VERSION ""

NS_ :

BS_:

BU_: L_DHRR_FD L_UWB_BLE_MST_FD L_UWB_RR_FD L_UWB_BLE_SLV_FD L_UWB_FR_FD L_ROA_FR_FD L_ROA_FD L_DHRL_FD L_UWB_TRNK_FD L_UWB_FRNK_FD L_EDT_FD L_UWB_FL_FD GW_BDC_FD L_UWB_RL_FD L_SAL_FD L_WPC_FD L_TPMS_FD L_DHL_FD L_DHR_FD

BO_ 994 PDC_FD_03_200ms: 16 GW_BDC_FD
 SG_ PDC_FD_Crc3Val : 0|16@1+ (1,0) [0|0] "" Vector__XXX
 SG_ PDC_FD_AlvCnt3Val : 16|8@1+ (1,0) [0|0] "" Vector__XXX
 SG_ Warn_DrvDrSwSta_Copy_0 : 64|2@1+ (1,0) [0|0] ""  L_UWB_BLE_MST_FD
 SG_ Warn_AsstDrSwSta_Copy_0 : 66|2@1+ (1,0) [0|0] ""  L_UWB_BLE_MST_FD
 SG_ Warn_RrLftDrSwSta_Copy_0 : 68|2@1+ (1,0) [0|0] ""  L_UWB_BLE_MST_FD
 SG_ Warn_RrRtDrSwSta_Copy_0 : 70|2@1+ (1,0) [0|0] ""  L_UWB_BLE_MST_FD
 SG_ Warn_HoodSwSta_Copy_0 : 72|2@1+ (1,0) [0|0] ""  L_UWB_BLE_MST_FD
 SG_ DoorLock_DrvDrUnLkSta_Copy_0 : 74|2@1+ (1,0) [0|0] ""  L_UWB_BLE_MST_FD
 SG_ DoorLock_AsstDrUnLkSta_Copy_0 : 76|2@1+ (1,0) [0|0] ""  L_UWB_BLE_MST_FD
 SG_ DoorLock_RrLftDrUnLkSta_Copy_0 : 78|2@1+ (1,0) [0|0] ""  L_UWB_BLE_MST_FD
 SG_ DoorLock_RrRtDrUnLkSta_Copy_0 : 80|2@1+ (1,0) [0|0] ""  L_UWB_BLE_MST_FD
 SG_ DoorLock_DrvKeyLkSwSta_Copy_0 : 82|2@1+ (1,0) [0|0] "" Vector__XXX
 SG_ DoorLock_DrvKeyUnLkSwSta_Copy_0 : 84|2@1+ (1,0) [0|0] "" Vector__XXX
 SG_ DoorLock_CtrlDrLkSwSta_ICU_Copy_ : 86|2@1+ (1,0) [0|0] "" Vector__XXX
 SG_ DoorLock_CtrlDrUnLkSwSta_ICU_Cop : 88|2@1+ (1,0) [0|0] "" Vector__XXX
 SG_ DoorLock_CtrlDrLkUnLkSwSta_ICU_C : 90|2@1+ (1,0) [0|0] "" Vector__XXX
 SG_ C_CrashUnlockState_Copy_0 : 92|2@1+ (1,0) [0|0] "" Vector__XXX
 SG_ Lamp_LedHdLmpSta_Copy_0 : 94|2@1+ (1,0) [0|0] "" Vector__XXX
 SG_ Warn_ChaDrSwFrtSta_Copy_0 : 96|2@1+ (1,0) [0|0] "" Vector__XXX
 SG_ Warn_ChaDrSwRrSta_Copy_0 : 98|2@1+ (1,0) [0|0] "" Vector__XXX

BO_ 2348810241 L_BDC_FD_01_200ms: 32 GW_BDC_FD
 SG_ L_BDC_FD_Crc1Val : 0|16@1+ (1,0) [0|0] "0"  L_SAL_FD
 SG_ MoodLamp_BottomBlueVal : 104|8@1+ (1,0) [0|0] ""  L_SAL_FD
 SG_ MoodLamp_AIVoiceMicLevel : 112|6@1+ (1,0) [0|0] ""  L_SAL_FD
 SG_ MoodLamp_AIVoiceTTSLevel : 120|6@1+ (1,0) [0|0] ""  L_SAL_FD
 SG_ MoodLamp_VehicleSpeed : 128|9@1+ (1,0) [0|0] ""  L_SAL_FD
 SG_ MoodLamp_MLBrghtModCmd_6bit : 137|6@1+ (1,0) [0|0] ""  L_SAL_FD
 SG_ MoodLamp_MLColorModCmd_6bit : 143|6@1+ (1,0) [0|0] ""  L_SAL_FD
 SG_ MoodLamp_DrvTempChgModCmd : 149|2@1+ (1,0) [0|0] ""  L_SAL_FD
 SG_ MoodLamp_AstTempChgModCmd : 151|2@1+ (1,0) [0|0] ""  L_SAL_FD
 SG_ MoodLamp_PhoneCallModCmd : 153|2@1+ (1,0) [0|0] ""  L_SAL_FD
 SG_ MoodLamp_AIVoiceRecogPosSta : 155|3@1+ (1,0) [0|0] ""  L_SAL_FD
 SG_ MoodLamp_FLDoorWarnModCmd : 158|3@1+ (1,0) [0|0] ""  L_SAL_FD
 SG_ L_BDC_FD_AlvCnt1Val : 16|8@1+ (1,0) [0|0] "0"  L_SAL_FD
 SG_ MoodLamp_FRDoorWarnModCmd : 161|3@1+ (1,0) [0|0] ""  L_SAL_FD
 SG_ MoodLamp_RLDoorWarnModCmd : 164|3@1+ (1,0) [0|0] ""  L_SAL_FD
 SG_ MoodLamp_RRDoorWarnModCmd : 167|3@1+ (1,1) [0|0] ""  L_SAL_FD
 SG_ MoodLamp_HazardModCmd : 170|2@1+ (1,0) [0|0] ""  L_SAL_FD
 SG_ MoodLamp_FLDoorObstacleModCmd : 172|2@1+ (1,0) [0|0] ""  L_SAL_FD
 SG_ MoodLamp_FRDoorObstacleModCmd : 174|2@1+ (1,0) [0|0] ""  L_SAL_FD
 SG_ MoodLamp_RLDoorObstacleModCmd : 176|2@1+ (1,0) [0|0] ""  L_SAL_FD
 SG_ MoodLamp_RRDoorObstacleModCmd : 178|2@1+ (1,0) [0|0] ""  L_SAL_FD
 SG_ MoodLamp_LowFuelWarnModCmd : 180|2@1+ (1,0) [0|0] ""  L_SAL_FD
 SG_ MoodLamp_NShiftModCmd : 182|3@1+ (1,0) [0|0] ""  L_SAL_FD
 SG_ MoodLamp_MLBrghtModCmd : 24|4@1+ (1,0) [0|0] ""  L_SAL_FD
 SG_ MoodLamp_MLColorModCmd : 28|4@1+ (1,0) [0|0] ""  L_SAL_FD
 SG_ MoodLamp_WelcomeAndGoodbyeSeqMod : 32|2@1+ (1,0) [0|0] ""  L_SAL_FD
 SG_ MoodLamp_AIVoiceSeqModCmd : 34|3@1+ (1,0) [0|0] ""  L_SAL_FD
 SG_ MoodLamp_EngineRunningSeqModCmd : 37|2@1+ (1,0) [0|0] ""  L_SAL_FD
 SG_ MoodLamp_OverSpeedSeqModCmd : 40|2@1+ (1,0) [0|0] ""  L_SAL_FD
 SG_ MoodLamp_DriveSeqModCmd : 42|4@1+ (1,0) [0|0] ""  L_SAL_FD
 SG_ MoodLamp_AirCleaningSeqModCmd : 48|3@1+ (1,0) [0|0] ""  L_SAL_FD
 SG_ MoodLamp_FootLampModCmd : 51|2@1+ (1,0) [0|0] ""  L_SAL_FD
 SG_ MoodLamp_SunroofModCmd : 53|2@1+ (1,0) [0|0] ""  L_SAL_FD
 SG_ MoodLamp_BrghtVal : 56|4@1+ (1,0) [0|0] ""  L_SAL_FD
 SG_ MoodLamp_RedVal : 64|8@1+ (1,0) [0|0] ""  L_SAL_FD
 SG_ MoodLamp_GreenVal : 72|8@1+ (1,0) [0|0] ""  L_SAL_FD
 SG_ MoodLamp_BlueVal : 80|8@1+ (1,0) [0|0] ""  L_SAL_FD
 SG_ MoodLamp_BottomRedVal : 88|8@1+ (1,0) [0|0] ""  L_SAL_FD
 SG_ MoodLamp_BottomGreenVal : 96|8@1+ (1,0) [0|0] ""  L_SAL_FD

BO_ 996 PDC_FD_10_200ms: 16 GW_BDC_FD
 SG_ PDC_FD_Crc10Val : 0|16@1+ (1,0) [0|0] "" Vector__XXX
 SG_ PDC_PwrOnModePowerReq_Copy_0 : 107|2@1+ (1,0) [0|0] "" Vector__XXX
 SG_ PDC_LeadAcidBatType_Copy_0 : 109|5@1+ (1,0) [0|0] "" Vector__XXX
 SG_ PDC_BatPwrClassOpt_Copy_0 : 114|2@1+ (1,0) [0|0] "" Vector__XXX
 SG_ PDC_MainLBMOpt : 116|2@1+ (1,0) [0|0] "" Vector__XXX
 SG_ PDC_FD_AlvCnt10Val : 16|8@1+ (1,0) [0|0] "" Vector__XXX
 SG_ ICU_PowerAutoCutModSta_Copy_0 : 64|2@1+ (1,0) [0|0] ""  L_TPMS_FD
 SG_ Autocut_DlvryModSta_Copy_0 : 66|2@1+ (1,0) [0|0] "" Vector__XXX
 SG_ ICU_SoCBattStaMsgReq_Copy_0 : 68|2@1+ (1,0) [0|0] "" Vector__XXX
 SG_ Batt_SoCWarningValue_Copy_0 : 70|8@1+ (1,0) [0|0] "%" Vector__XXX
 SG_ ICU_BattAutoCutPreWrng_Copy_0 : 78|2@1+ (1,0) [0|0] "" Vector__XXX
 SG_ OTAModeACCOffReq_Copy_0 : 80|2@1+ (1,0) [0|0] "" Vector__XXX
 SG_ C_ICUIGNOffReq_Copy_0 : 82|2@1+ (1,0) [0|0] "" Vector__XXX
 SG_ IGN_AutoOff_WarnSta_Copy_0 : 84|2@1+ (1,0) [0|0] "" Vector__XXX
 SG_ IGN_AutoOff_WarnSta_CLU_Copy_0 : 86|2@1+ (1,0) [0|0] "" Vector__XXX
 SG_ PDC_BatPwrStateClassA_Copy_0 : 88|2@1+ (1,0) [0|0] "" Vector__XXX
 SG_ PDC_BatPwrStateClassB_Copy_0 : 90|2@1+ (1,0) [0|0] "" Vector__XXX
 SG_ PDC_BatPwrStateClassC_Copy_0 : 92|2@1+ (1,0) [0|0] "" Vector__XXX
 SG_ PLBMAvailableState_Copy_0 : 94|1@1+ (1,0) [0|0] "" Vector__XXX
 SG_ Bat_dischrg_Copy_0 : 95|2@1+ (1,0) [0|0] "" Vector__XXX
 SG_ Bat12V_Chr_Req_Copy_0 : 97|2@1+ (1,0) [0|0] "" Vector__XXX
 SG_ ICU_BattMngAlert_Copy_0 : 99|8@1+ (1,0) [0|0] "" Vector__XXX

BO_ 2549874800 NM_CGW_CCU: 32 GW_BDC_FD
 SG_ SNI_CGW_CCU : 0|8@1+ (1,0) [0|0] ""  L_DHL_FD,L_DHRL_FD,L_DHRR_FD,L_DHR_FD,L_SAL_FD,L_TPMS_FD,L_UWB_BLE_MST_FD,L_UWB_BLE_SLV_FD,L_UWB_FL_FD,L_UWB_FRNK_FD,L_UWB_FR_FD,L_UWB_RL_FD,L_UWB_RR_FD,L_UWB_TRNK_FD,L_WPC_FD
 SG_ CBV_NMCoSRB_CGW_CCU : 11|1@1+ (1,0) [0|0] ""  L_DHL_FD,L_DHRL_FD,L_DHRR_FD,L_DHR_FD,L_SAL_FD,L_TPMS_FD,L_UWB_BLE_MST_FD,L_UWB_BLE_SLV_FD,L_UWB_FL_FD,L_UWB_FRNK_FD,L_UWB_FR_FD,L_UWB_RL_FD,L_UWB_RR_FD,L_UWB_TRNK_FD,L_WPC_FD
 SG_ CBV_AWB_CGW_CCU : 12|1@1+ (1,0) [0|0] ""  L_DHL_FD,L_DHRL_FD,L_DHRR_FD,L_DHR_FD,L_SAL_FD,L_TPMS_FD,L_UWB_BLE_MST_FD,L_UWB_BLE_SLV_FD,L_UWB_FL_FD,L_UWB_FRNK_FD,L_UWB_FR_FD,L_UWB_RL_FD,L_UWB_RR_FD,L_UWB_TRNK_FD,L_WPC_FD
 SG_ PNI_CGW_CCU_2 : 128|64@1+ (1,0) [0|0] ""  L_DHL_FD,L_DHRL_FD,L_DHRR_FD,L_DHR_FD,L_SAL_FD,L_TPMS_FD,L_UWB_BLE_MST_FD,L_UWB_BLE_SLV_FD,L_UWB_FL_FD,L_UWB_FRNK_FD,L_UWB_FR_FD,L_UWB_RL_FD,L_UWB_RR_FD,L_UWB_TRNK_FD,L_WPC_FD
 SG_ CBV_PNIB_CGW_CCU : 14|1@1+ (1,0) [0|0] ""  L_DHL_FD,L_DHRL_FD,L_DHRR_FD,L_DHR_FD,L_SAL_FD,L_TPMS_FD,L_UWB_BLE_MST_FD,L_UWB_BLE_SLV_FD,L_UWB_FL_FD,L_UWB_FRNK_FD,L_UWB_FR_FD,L_UWB_RL_FD,L_UWB_RR_FD,L_UWB_TRNK_FD,L_WPC_FD
 SG_ NRR_CGW_CCU : 16|8@1+ (1,0) [0|0] ""  L_DHL_FD,L_DHRL_FD,L_DHRR_FD,L_DHR_FD,L_SAL_FD,L_TPMS_FD,L_UWB_BLE_MST_FD,L_UWB_BLE_SLV_FD,L_UWB_FL_FD,L_UWB_FRNK_FD,L_UWB_FR_FD,L_UWB_RL_FD,L_UWB_RR_FD,L_UWB_TRNK_FD,L_WPC_FD
 SG_ PNI_CGW_CCU_3 : 192|64@1+ (1,0) [0|0] ""  L_DHL_FD,L_DHRL_FD,L_DHRR_FD,L_DHR_FD,L_SAL_FD,L_TPMS_FD,L_UWB_BLE_MST_FD,L_UWB_BLE_SLV_FD,L_UWB_FL_FD,L_UWB_FRNK_FD,L_UWB_FR_FD,L_UWB_RL_FD,L_UWB_RR_FD,L_UWB_TRNK_FD,L_WPC_FD
 SG_ NM_State_CGW_CCU : 24|8@1+ (1,0) [0|0] ""  L_DHL_FD,L_DHRL_FD,L_DHRR_FD,L_DHR_FD,L_SAL_FD,L_TPMS_FD,L_UWB_BLE_MST_FD,L_UWB_BLE_SLV_FD,L_UWB_FL_FD,L_UWB_FRNK_FD,L_UWB_FR_FD,L_UWB_RL_FD,L_UWB_RR_FD,L_UWB_TRNK_FD,L_WPC_FD
 SG_ PNI_CGW_CCU : 32|32@1+ (1,0) [0|0] ""  L_DHL_FD,L_DHRL_FD,L_DHRR_FD,L_DHR_FD,L_SAL_FD,L_TPMS_FD,L_UWB_BLE_MST_FD,L_UWB_BLE_SLV_FD,L_UWB_FL_FD,L_UWB_FRNK_FD,L_UWB_FR_FD,L_UWB_RL_FD,L_UWB_RR_FD,L_UWB_TRNK_FD,L_WPC_FD
 SG_ PNI_CGW_CCU_1 : 64|64@1+ (1,0) [0|0] ""  L_DHL_FD,L_DHRL_FD,L_DHRR_FD,L_DHR_FD,L_SAL_FD,L_TPMS_FD,L_UWB_BLE_MST_FD,L_UWB_BLE_SLV_FD,L_UWB_FL_FD,L_UWB_FRNK_FD,L_UWB_FR_FD,L_UWB_RL_FD,L_UWB_RR_FD,L_UWB_TRNK_FD,L_WPC_FD
 SG_ CBV_RMR_CGW_CCU : 8|1@1+ (1,0) [0|0] ""  L_DHL_FD,L_DHRL_FD,L_DHRR_FD,L_DHR_FD,L_SAL_FD,L_TPMS_FD,L_UWB_BLE_MST_FD,L_UWB_BLE_SLV_FD,L_UWB_FL_FD,L_UWB_FRNK_FD,L_UWB_FR_FD,L_UWB_RL_FD,L_UWB_RR_FD,L_UWB_TRNK_FD,L_WPC_FD
 SG_ CBV_NMCoID_CGW_CCU : 9|2@1+ (1,0) [0|0] ""  L_DHL_FD,L_DHRL_FD,L_DHRR_FD,L_DHR_FD,L_SAL_FD,L_TPMS_FD,L_UWB_BLE_MST_FD,L_UWB_BLE_SLV_FD,L_UWB_FL_FD,L_UWB_FRNK_FD,L_UWB_FR_FD,L_UWB_RL_FD,L_UWB_RR_FD,L_UWB_TRNK_FD,L_WPC_FD

BO_ 2348810242 L_BDC_FD_02_200ms: 32 GW_BDC_FD
 SG_ TPMS_SnsrIdRrVal : 128|32@1+ (1,0) [0|0] ""  L_TPMS_FD
 SG_ TPMS_FrontLowPressureWarnSetVal : 160|16@1+ (1,0) [0|0] ""  L_TPMS_FD
 SG_ TPMS_RearLowPressureWarnSetVal : 176|16@1+ (1,0) [0|0] ""  L_TPMS_FD
 SG_ TPMS_FrontLowPressureWarnClearVa : 192|16@1+ (1,0) [0|0] ""  L_TPMS_FD
 SG_ TPMS_RearLowPressureWarnClearVal : 208|16@1+ (1,0) [0|0] ""  L_TPMS_FD
 SG_ TPMS_SensorSupplierInfo : 224|2@1+ (1,0) [0|0] ""  L_TPMS_FD
 SG_ TPMS_RfConfigueVal : 226|2@1+ (1,0) [0|0] ""  L_TPMS_FD
 SG_ TPMS_SnsrIdFlVal : 24|32@1+ (1,0) [0|0] ""  L_TPMS_FD
 SG_ TPMS_LowPressureWarnSta : 56|4@1+ (1,0) [0|0] ""  L_TPMS_FD
 SG_ TPMS_LastTpsDataReq : 60|2@1+ (1,0) [0|0] ""  L_TPMS_FD
 SG_ TPMS_SnsrIdFrVal : 64|32@1+ (1,0) [0|0] ""  L_TPMS_FD
 SG_ TPMS_SnsrIdRlVal : 96|32@1+ (1,0) [0|0] ""  L_TPMS_FD

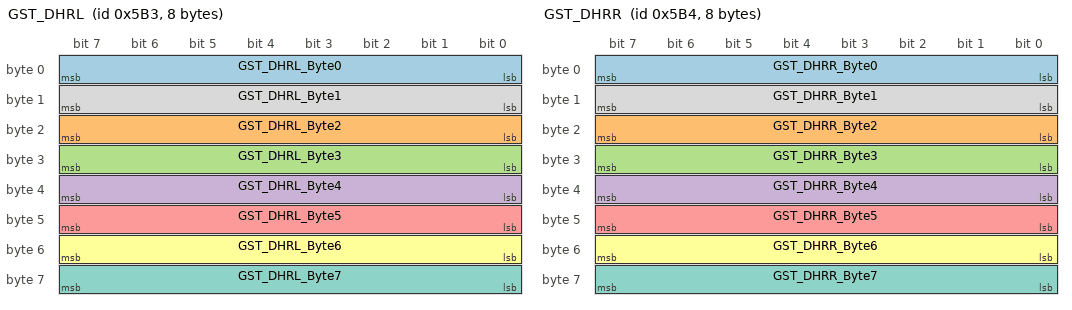
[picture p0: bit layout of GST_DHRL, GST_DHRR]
BO_ 1459 GST_DHRL: 8 GW_BDC_FD
 SG_ GST_DHRL_Byte0 : 0|8@1+ (1,0) [0|0] ""  L_DHRL_FD
 SG_ GST_DHRL_Byte2 : 16|8@1+ (1,0) [0|0] ""  L_DHRL_FD
 SG_ GST_DHRL_Byte3 : 24|8@1+ (1,0) [0|0] ""  L_DHRL_FD
 SG_ GST_DHRL_Byte4 : 32|8@1+ (1,0) [0|0] ""  L_DHRL_FD
 SG_ GST_DHRL_Byte5 : 40|8@1+ (1,0) [0|0] ""  L_DHRL_FD
 SG_ GST_DHRL_Byte6 : 48|8@1+ (1,0) [0|0] ""  L_DHRL_FD
 SG_ GST_DHRL_Byte7 : 56|8@1+ (1,0) [0|0] ""  L_DHRL_FD
 SG_ GST_DHRL_Byte1 : 8|8@1+ (1,0) [0|0] ""  L_DHRL_FD

BO_ 2683310258 L_ROA_FD_Debug_03: 8 L_ROA_FD
 SG_ ROA_Debug_08 : 0|64@1+ (1,0) [0|0] "" Vector__XXX

BO_ 1460 GST_DHRR: 8 GW_BDC_FD
 SG_ GST_DHRR_Byte0 : 0|8@1+ (1,0) [0|0] ""  L_DHRR_FD
 SG_ GST_DHRR_Byte2 : 16|8@1+ (1,0) [0|0] ""  L_DHRR_FD
 SG_ GST_DHRR_Byte3 : 24|8@1+ (1,0) [0|0] ""  L_DHRR_FD
 SG_ GST_DHRR_Byte4 : 32|8@1+ (1,0) [0|0] ""  L_DHRR_FD
 SG_ GST_DHRR_Byte5 : 40|8@1+ (1,0) [0|0] ""  L_DHRR_FD
 SG_ GST_DHRR_Byte6 : 48|8@1+ (1,0) [0|0] ""  L_DHRR_FD
 SG_ GST_DHRR_Byte7 : 56|8@1+ (1,0) [0|0] ""  L_DHRR_FD
 SG_ GST_DHRR_Byte1 : 8|8@1+ (1,0) [0|0] ""  L_DHRR_FD

BO_ 2683310256 L_ROA_FD_Debug_01: 32 L_ROA_FD
 SG_ ROA_Debug_00 : 0|64@1+ (1,0) [0|0] "" Vector__XXX
 SG_ ROA_Debug_02 : 128|64@1+ (1,0) [0|0] "" Vector__XXX
 SG_ ROA_Debug_03 : 192|64@1+ (1,0) [0|0] "" Vector__XXX
 SG_ ROA_Debug_01 : 64|64@1+ (1,0) [0|0] "" Vector__XXX

BO_ 2683310257 L_ROA_FD_Debug_02: 32 L_ROA_FD
 SG_ ROA_Debug_04 : 0|64@1+ (1,0) [0|0] "" Vector__XXX
 SG_ ROA_Debug_06 : 128|64@1+ (1,0) [0|0] "" Vector__XXX
 SG_ ROA_Debug_07 : 192|64@1+ (1,0) [0|0] "" Vector__XXX
 SG_ ROA_Debug_05 : 64|64@1+ (1,0) [0|0] "" Vector__XXX

BO_ 2281701616 L_UWB_RL_FD_10_200ms: 24 L_UWB_RL_FD
 SG_ L_UWB_RL_FD_Crc10Val : 0|16@1+ (1,0) [0|0] "0" Vector__XXX
 SG_ UWB_RL_SW_MCU_Ver_Major : 104|8@1+ (1,0) [0|0] ""  L_UWB_BLE_MST_FD
 SG_ UWB_RL_SW_MCU_Ver_Minor : 112|8@1+ (1,0) [0|0] ""  L_UWB_BLE_MST_FD
 SG_ UWB_RL_SW_IC_Ver_Major : 120|8@1+ (1,0) [0|0] ""  L_UWB_BLE_MST_FD
 SG_ UWB_RL_SW_IC_Ver_Minor : 128|8@1+ (1,0) [0|0] ""  L_UWB_BLE_MST_FD
 SG_ UWB_RL_DTC : 136|8@1+ (1,0) [0|0] ""  L_UWB_BLE_MST_FD
 SG_ L_UWB_RL_FD_AlvCnt10Val : 16|8@1+ (1,0) [0|0] "0" Vector__XXX
 SG_ UWB_RL_Status1 : 24|4@1+ (1,0) [0|7] ""  GW_BDC_FD,L_UWB_BLE_MST_FD
 SG_ UWB_RL_Status2 : 28|4@1+ (1,0) [0|0] ""  GW_BDC_FD,L_UWB_BLE_MST_FD
 SG_ UWB_RL_Status3 : 32|4@1+ (1,0) [0|0] ""  GW_BDC_FD,L_UWB_BLE_MST_FD
 SG_ UWB_RL_Status4 : 36|4@1+ (1,0) [0|0] ""  GW_BDC_FD,L_UWB_BLE_MST_FD
 SG_ UWB_RL_Status5 : 40|4@1+ (1,0) [0|0] ""  GW_BDC_FD,L_UWB_BLE_MST_FD
 SG_ UWB_RL_Status6 : 44|4@1+ (1,0) [0|0] ""  GW_BDC_FD,L_UWB_BLE_MST_FD
 SG_ UWB_RL_Status7 : 48|4@1+ (1,0) [0|0] ""  GW_BDC_FD,L_UWB_BLE_MST_FD
 SG_ UWB_RL_Status8 : 52|4@1+ (1,0) [0|0] ""  GW_BDC_FD,L_UWB_BLE_MST_FD
 SG_ UWB_RL_Status9 : 56|4@1+ (1,0) [0|0] ""  GW_BDC_FD,L_UWB_BLE_MST_FD
 SG_ UWB_RL_Status10 : 60|4@1+ (1,0) [0|0] ""  GW_BDC_FD,L_UWB_BLE_MST_FD
 SG_ UWB_RL_Status11 : 64|4@1+ (1,0) [0|0] ""  GW_BDC_FD,L_UWB_BLE_MST_FD
 SG_ UWB_RL_Status12 : 68|4@1+ (1,0) [0|0] ""  GW_BDC_FD,L_UWB_BLE_MST_FD
 SG_ UWB_RL_Status13 : 72|4@1+ (1,0) [0|0] ""  GW_BDC_FD,L_UWB_BLE_MST_FD
 SG_ UWB_RL_Status14 : 76|4@1+ (1,0) [0|0] ""  GW_BDC_FD,L_UWB_BLE_MST_FD
 SG_ UWB_RL_Status15 : 80|4@1+ (1,0) [0|0] ""  GW_BDC_FD,L_UWB_BLE_MST_FD
 SG_ UWB_RL_Status16 : 84|4@1+ (1,0) [0|0] ""  GW_BDC_FD,L_UWB_BLE_MST_FD
 SG_ UWB_RL_HW_Ver_Major : 88|8@1+ (1,0) [0|0] ""  L_UWB_BLE_MST_FD
 SG_ UWB_RL_HW_Ver_Minor : 96|8@1+ (1,0) [0|0] ""  L_UWB_BLE_MST_FD

BO_ 979 BDC_FD_04_200ms: 32 GW_BDC_FD
 SG_ BDC_FD_Crc4Val : 0|16@1+ (1,0) [0|0] "" Vector__XXX
 SG_ BDC_FD_AlvCnt4Val : 16|8@1+ (1,0) [0|0] "" Vector__XXX
 SG_ BAlarm_BglrAlrm_CurrentSta : 24|4@1+ (1,0) [0|0] "" Vector__XXX
 SG_ BAlarm_BglrAlrm_Sta : 28|2@1+ (1,0) [0|0] "" Vector__XXX
 SG_ BAlarm_PncAlrmSta_Copy_0 : 30|2@1+ (1,0) [0|0] "" Vector__XXX
 SG_ SBR_StBltStpWrngBzrSta_Copy_0 : 34|3@1+ (1,0) [0|0] "" Vector__XXX
 SG_ SBR_StBltWrngBzrSta_Copy_0 : 37|3@1+ (1,0) [0|0] "" Vector__XXX
 SG_ BAlarm_BrglrHrnRlySta_Copy_0 : 40|2@1+ (1,0) [0|0] "" Vector__XXX
 SG_ SBR_DrvStBltIndSta_Copy_0 : 42|2@1+ (1,0) [0|0] "" Vector__XXX
 SG_ SBR_RrLftStBltWrngIndSta_Copy_0 : 44|2@1+ (1,0) [0|0] "" Vector__XXX
 SG_ SBR_RrRtStBltWrngIndSta_Copy_0 : 46|2@1+ (1,0) [0|0] "" Vector__XXX
 SG_ SBR_RrCtrStBltIndSta_Copy_0 : 48|2@1+ (1,0) [0|0] "" Vector__XXX
 SG_ SBR_3rdLftStBltWrngIndSta_Copy_0 : 50|2@1+ (1,0) [0|0] "" Vector__XXX
 SG_ SBR_3rdRtStBltWrngIndSta_Copy_0 : 52|2@1+ (1,0) [0|0] "" Vector__XXX
 SG_ SBR_3rdCtrStBltWrngIndSta_Copy_0 : 54|2@1+ (1,0) [0|0] "" Vector__XXX
 SG_ Warn_BzrWrngSta_Copy_0 : 56|4@1+ (1,0) [0|0] "" Vector__XXX
 SG_ Warn_BCMWrngSta_Copy_0 : 60|4@1+ (1,0) [0|0] "" Vector__XXX
 SG_ ROA_RrBlwAutoOffReq_Copy_0 : 64|2@1+ (1,0) [0|0] "" Vector__XXX
 SG_ ROA_RegionOpt_Copy_0 : 66|2@1+ (1,0) [0|0] "" Vector__XXX
 SG_ Warn_RrStRmndOpt_Copy_0 : 68|2@1+ (1,0) [0|0] "" Vector__XXX
 SG_ Warn_RrStRmndAlrmOnReq_Copy_0 : 70|2@1+ (1,0) [0|0] "" Vector__XXX
 SG_ Warn_RrStRmndSysSta_Copy_0 : 72|2@1+ (1,0) [0|0] "" Vector__XXX
 SG_ Warn_RrStRmndAlrmInfo_Copy_0 : 74|3@1+ (1,0) [0|0] "" Vector__XXX
 SG_ Warn_RoaErr_Copy_0 : 77|3@1+ (1,0) [0|0] "" Vector__XXX
 SG_ Warn_RrStRmndDelay_Copy_0 : 80|2@1+ (1,0) [0|0] "" Vector__XXX
 SG_ Warn_RrStRmndSysAct_Copy_0 : 82|2@1+ (1,0) [0|0] "" Vector__XXX
 SG_ WAL_FobSearching_Copy_0 : 84|2@1+ (1,0) [0|0] "" Vector__XXX
 SG_ Warn_RrStRmndSysOffIND_Copy_0 : 86|2@1+ (1,0) [0|0] "" Vector__XXX
 SG_ Warn_VehNotPWrngSta_Copy_0 : 88|3@1+ (1,0) [0|0] "" Vector__XXX
 SG_ Warn_RrStRmndAlrmInfo_1_Copy_0 : 91|3@1+ (1,0) [0|0] ""  L_ROA_FD

BO_ 2533736961 L_UWB_TRNK_FD_06_00ms: 32 L_UWB_TRNK_FD
 SG_ L_UWB_TRNK_FD_Crc6Val : 0|16@1+ (1,0) [0|0] "" Vector__XXX
 SG_ L_UWB_TRNK_FD_AlvCnt6Val : 16|8@1+ (1,0) [0|0] "" Vector__XXX
 SG_ TRNK_SWID_4_IVD_1 : 24|232@1+ (1,0) [0|0] ""  L_UWB_BLE_MST_FD

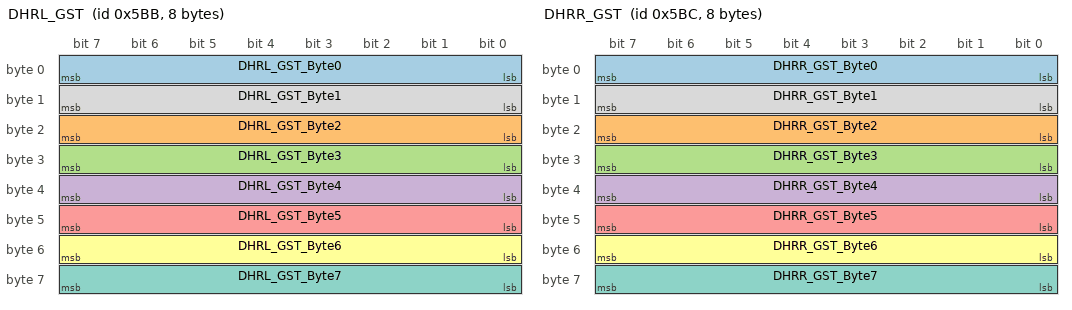
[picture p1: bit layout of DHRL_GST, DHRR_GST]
BO_ 1467 DHRL_GST: 8 L_DHRL_FD
 SG_ DHRL_GST_Byte0 : 0|8@1+ (1,0) [0|0] ""  GW_BDC_FD
 SG_ DHRL_GST_Byte2 : 16|8@1+ (1,0) [0|0] ""  GW_BDC_FD
 SG_ DHRL_GST_Byte3 : 24|8@1+ (1,0) [0|0] ""  GW_BDC_FD
 SG_ DHRL_GST_Byte4 : 32|8@1+ (1,0) [0|0] ""  GW_BDC_FD
 SG_ DHRL_GST_Byte5 : 40|8@1+ (1,0) [0|0] ""  GW_BDC_FD
 SG_ DHRL_GST_Byte6 : 48|8@1+ (1,0) [0|0] ""  GW_BDC_FD
 SG_ DHRL_GST_Byte7 : 56|8@1+ (1,0) [0|0] ""  GW_BDC_FD
 SG_ DHRL_GST_Byte1 : 8|8@1+ (1,0) [0|0] ""  GW_BDC_FD

BO_ 977 BDC_FD_02_200ms: 32 GW_BDC_FD
 SG_ BDC_FD_Crc2Val : 0|16@1+ (1,0) [0|0] "" Vector__XXX
 SG_ BDC_FD_AlvCnt2Val : 16|8@1+ (1,0) [0|0] "" Vector__XXX
 SG_ BCM_KeyInSta_Copy_0 : 24|2@1+ (1,0) [0|0] "" Vector__XXX
 SG_ BCM_AccInSta_Copy_0 : 26|2@1+ (1,0) [0|0] "" Vector__XXX
 SG_ BCM_Ign1InSta_Copy_0 : 28|2@1+ (1,0) [0|0] ""  L_ROA_FD,L_ROA_FR_FD,L_TPMS_FD,L_UWB_BLE_MST_FD,L_UWB_BLE_SLV_FD
 SG_ BCM_Ign2InSta_Copy_0 : 30|2@1+ (1,0) [0|0] ""  L_ROA_FD,L_ROA_FR_FD,L_UWB_BLE_MST_FD,L_UWB_BLE_SLV_FD
 SG_ IBU_HDPSpprtSWVer_Copy_0 : 32|6@1+ (1,0) [0|0] "" Vector__XXX
 SG_ IBU_HDPSpprtRdy_Copy_0 : 38|2@1+ (1,0) [0|0] "" Vector__XXX
 SG_ BCM_GearPosPSta_Copy_0 : 40|2@1+ (1,0) [0|0] "" Vector__XXX
 SG_ BCM_SmkOptTyp_Copy_0 : 42|2@1+ (1,0) [0|0] "" Vector__XXX
 SG_ BDC_ResetOpSta_Copy_0 : 44|2@1+ (1,0) [0|0] "" Vector__XXX
 SG_ IBU_SWVerMajor1_Copy_0 : 48|7@1+ (1,0) [0|0] "" Vector__XXX
 SG_ IBU_SWVerMinor1_Copy_0 : 56|7@1+ (1,0) [0|0] "" Vector__XXX
 SG_ IBU_SWVerMinor2_Copy_0 : 64|7@1+ (1,0) [0|0] "" Vector__XXX
 SG_ BDC_PlatformVerType_Copy_0 : 72|4@1+ (1,0) [0|0] "" Vector__XXX
 SG_ BDC_PlatformVerDate_Copy_0 : 80|8@1+ (1,0) [0|0] "" Vector__XXX

BO_ 2529538561 L_UWB_RL_FD_06_00ms: 32 L_UWB_RL_FD
 SG_ L_UWB_RL_FD_Crc6Val : 0|16@1+ (1,0) [0|0] "" Vector__XXX
 SG_ L_UWB_RL_FD_AlvCnt6Val : 16|8@1+ (1,0) [0|0] "" Vector__XXX
 SG_ RL_SWID_4_IVD_1 : 24|232@1+ (1,0) [0|0] ""  L_UWB_BLE_MST_FD

BO_ 1468 DHRR_GST: 8 L_DHRR_FD
 SG_ DHRR_GST_Byte0 : 0|8@1+ (1,0) [0|0] ""  GW_BDC_FD
 SG_ DHRR_GST_Byte2 : 16|8@1+ (1,0) [0|0] ""  GW_BDC_FD
 SG_ DHRR_GST_Byte3 : 24|8@1+ (1,0) [0|0] ""  GW_BDC_FD
 SG_ DHRR_GST_Byte4 : 32|8@1+ (1,0) [0|0] ""  GW_BDC_FD
 SG_ DHRR_GST_Byte5 : 40|8@1+ (1,0) [0|0] ""  GW_BDC_FD
 SG_ DHRR_GST_Byte6 : 48|8@1+ (1,0) [0|0] ""  GW_BDC_FD
 SG_ DHRR_GST_Byte7 : 56|8@1+ (1,0) [0|0] ""  GW_BDC_FD
 SG_ DHRR_GST_Byte1 : 8|8@1+ (1,0) [0|0] ""  GW_BDC_FD

CM_ BO_ 994 "[PE] Periodic and On Event";
CM_ SG_ 994 PDC_FD_Crc3Val "PDC_FD_CyclicRedundancyCheck3Value";
CM_ SG_ 994 PDC_FD_AlvCnt3Val "PDC_FD_AliveCounter3Value";
CM_ SG_ 994 Warn_DrvDrSwSta_Copy_0 "DoorLock_DriverDoorSwitchStatus ##2G## -  - C_DrvDrSw,CF_Gway_DrvDrSw,Warn_DrvDrSwSta";
CM_ SG_ 994 Warn_AsstDrSwSta_Copy_0 "Warn_AssistDoorSwitchStatus ##2G## -  - C_AstDrSw,CF_Gway_AstDrSw,Warn_AsstDrSwSta";
CM_ SG_ 994 Warn_RrLftDrSwSta_Copy_0 "Warn_RearLeftDoorSwitchStatus ##2G## -  - C_RLDrSw,CF_Gway_RLDrSw,Warn_RrLftDrSwSta";
CM_ SG_ 994 Warn_RrRtDrSwSta_Copy_0 "Warn_RearRightDoorSwitchStatus ##2G## -  - C_RRDrSw,CF_Gway_RRDrSw,Warn_RrRtDrSwSta";
CM_ SG_ 994 Warn_HoodSwSta_Copy_0 "Warn_HoodSwitchStatus ##2G## -  - C_HoodSw,CF_Gway_HoodSw";
CM_ SG_ 994 DoorLock_DrvDrUnLkSta_Copy_0 "DoorLock_DriverDoorUnLockStatus ##2G## -  - C_DrvUnlockState,CF_Gway_DrvUnlockState";
CM_ SG_ 994 DoorLock_AsstDrUnLkSta_Copy_0 "DoorLock_AssistDoorUnLockStatus ##2G## -  - C_AstUnlockState,DoorLock_AsstDrUnLkSta";
CM_ SG_ 994 DoorLock_RrLftDrUnLkSta_Copy_0 "DoorLock_RearLeftDoorUnLockStatus ##2G## -  - C_RLUnlockState,DoorLock_RrLftDrUnLkSta";
CM_ SG_ 994 DoorLock_RrRtDrUnLkSta_Copy_0 "DoorLock_RearRightDoorUnLockStatus ##2G## -  - C_RRUnlockState,DoorLock_RrRtDrUnLkSta";
CM_ SG_ 994 DoorLock_DrvKeyLkSwSta_Copy_0 "DoorLock_DriverKeyLockSwitchStatus ##2G## -  - C_DrvKeyLockSw";
CM_ SG_ 994 DoorLock_DrvKeyUnLkSwSta_Copy_0 "DoorLock_DriverKeyUnLockSwitchStatus ##2G## -  - C_DrvKeyUnlockSw";
CM_ SG_ 994 DoorLock_CtrlDrLkSwSta_ICU_Copy_ "Central Door Lock Switch State(DRV or AST or RL or RR Door trim)";
CM_ SG_ 994 DoorLock_CtrlDrUnLkSwSta_ICU_Cop "Central Door Unlock Switch State(DRV or AST or RL or RR Door trim)";
CM_ SG_ 994 DoorLock_CtrlDrLkUnLkSwSta_ICU_C "Central Door Lock/Unlock Switch State(C/PAD, Integrated & self return type)";
CM_ SG_ 994 C_CrashUnlockState_Copy_0 "Crash Unlock Active State";
CM_ SG_ 994 Lamp_LedHdLmpSta_Copy_0 "Lamp_LedHeadLampStatus ##2G## -  - CF_Afs_LedHLStat";
CM_ SG_ 994 Warn_ChaDrSwFrtSta_Copy_0 "##2G## - -  CF_Gway_ChaDrSwFrt";
CM_ SG_ 994 Warn_ChaDrSwRrSta_Copy_0 "##2G## -  - CF_Gway_ChaDrSwRr";
CM_ BO_ 2348810241 "[PE] Periodic and On Event";
CM_ SG_ 2348810241 L_BDC_FD_Crc1Val "L_BDC_FD_CyclicRedundancyCheck1Value";
CM_ SG_ 2348810241 MoodLamp_MLBrghtModCmd_6bit "MoodLamp Brightness Mode Command (6bit)";
CM_ SG_ 2348810241 MoodLamp_MLColorModCmd_6bit "MoodLamp Color Mode Command (6bit)";
CM_ SG_ 2348810241 L_BDC_FD_AlvCnt1Val "L_BDC_FD_AliveCounter1Value";
CM_ BO_ 996 "[PE] Periodic and On Event";
CM_ SG_ 996 PDC_FD_Crc10Val "PDC_FD_CyclicRedundancyCheck10Value";
CM_ SG_ 996 PDC_PwrOnModePowerReq_Copy_0 "This is for high voltage battery discharge request at Power On mode of EV";
CM_ SG_ 996 PDC_LeadAcidBatType_Copy_0 "Lead Acid Battery Type Information";
CM_ SG_ 996 PDC_MainLBMOpt "M-LBM(Main LBM) Option";
CM_ SG_ 996 PDC_FD_AlvCnt10Val "PDC_FD_AliveCounter10Value";
CM_ SG_ 996 ICU_PowerAutoCutModSta_Copy_0 "##2G## -  - CF_Gway_ICUPowerAutoCutMode";
CM_ SG_ 996 Autocut_DlvryModSta_Copy_0 "Autocut_DeliveryModeStatus ##2G## -  - C_SJBDeliveryMode,CF_Gway_SJBDeliveryMode";
CM_ SG_ 996 ICU_SoCBattStaMsgReq_Copy_0 "##2G## -  - Batt_SoCWarningAlertMsgReq";
CM_ SG_ 996 Batt_SoCWarningValue_Copy_0 "Value of SoC warning level. ##2G## -  - Batt_SoCWarningValue";
CM_ SG_ 996 ICU_BattAutoCutPreWrng_Copy_0 "This is a warning signal before blocking the dark current of the ICU by the battery SOC.";
CM_ SG_ 996 OTAModeACCOffReq_Copy_0 "ACC off request during OTA mode for battery saver";
CM_ SG_ 996 C_ICUIGNOffReq_Copy_0 "IGN off request(Not engine running state only) for battery saver";
CM_ SG_ 996 IGN_AutoOff_WarnSta_Copy_0 "this signal is defined as the warning signal related with battery discharge";
CM_ SG_ 996 IGN_AutoOff_WarnSta_CLU_Copy_0 "this signal is defined as the warning signal related with battery discharge";
CM_ SG_ 996 PDC_BatPwrStateClassA_Copy_0 "Vehicle Low-Voltage Power State Class A";
CM_ SG_ 996 PDC_BatPwrStateClassB_Copy_0 "Vehicle Low-Voltage Power State Class  B";
CM_ SG_ 996 PDC_BatPwrStateClassC_Copy_0 "Vehicle Low-Voltage Power State Class  C";
CM_ SG_ 996 Bat_dischrg_Copy_0 "Battery discharge notification flag #2G# Bat_dischrg";
CM_ SG_ 996 Bat12V_Chr_Req_Copy_0 "12V lead acid battery charging request signal";
CM_ SG_ 996 ICU_BattMngAlert_Copy_0 "This signal is for battery discharge warning.";
CM_ BO_ 2549874800 "[P] Periodic";
CM_ SG_ 2549874800 SNI_CGW_CCU "ASR NM Source Node Identifier";
CM_ SG_ 2549874800 CBV_NMCoSRB_CGW_CCU "ASR NM Control Bit Vector - ASR NM Coordinator Sleep Ready Bit";
CM_ SG_ 2549874800 CBV_AWB_CGW_CCU "ASR NM Control Bit Vector - Active Wakeup Bit";
CM_ SG_ 2549874800 PNI_CGW_CCU_2 "ASR NM Partial Networking Information";
CM_ SG_ 2549874800 CBV_PNIB_CGW_CCU "ASR NM Control Bit Vector - PN Info Bit";
CM_ SG_ 2549874800 NRR_CGW_CCU "ASR NM Network Request Reason";
CM_ SG_ 2549874800 PNI_CGW_CCU_3 "ASR NM Partial Networking Information";
CM_ SG_ 2549874800 NM_State_CGW_CCU "ASR NM State_Current State_Previous State";
CM_ SG_ 2549874800 PNI_CGW_CCU "ASR NM Partial Networking Information";
CM_ SG_ 2549874800 PNI_CGW_CCU_1 "ASR NM Partial Networking Information";
CM_ SG_ 2549874800 CBV_RMR_CGW_CCU "ASR NM Control Bit Vector - Repeat Message Request";
CM_ SG_ 2549874800 CBV_NMCoID_CGW_CCU "ASR NM Control Bit Vector - ASR NM Coordinator ID";
CM_ BO_ 2348810242 "[PE] Periodic and On Event";
CM_ SG_ 2348810242 TPMS_SnsrIdRrVal "TPMS ID Learning Information(RR)";
CM_ SG_ 2348810242 TPMS_FrontLowPressureWarnSetVal "Front tire low pressure warning setting pressure";
CM_ SG_ 2348810242 TPMS_RearLowPressureWarnSetVal "Rear tire low pressure warning setting pressure";
CM_ SG_ 2348810242 TPMS_FrontLowPressureWarnClearVa "Front tire low pressure warning release pressure";
CM_ SG_ 2348810242 TPMS_RearLowPressureWarnClearVal "Rear tire low pressure warning release pressure";
CM_ SG_ 2348810242 TPMS_SensorSupplierInfo "TPMS Sensor Supplier Info";
CM_ SG_ 2348810242 TPMS_RfConfigueVal "RF Frequency Info by Sales Area";
CM_ SG_ 2348810242 TPMS_SnsrIdFlVal "TPMS ID Learning Information(FL)";
CM_ SG_ 2348810242 TPMS_LowPressureWarnSta "Low pressure condition by tire position";
CM_ SG_ 2348810242 TPMS_LastTpsDataReq "Final Received FL/FR/RL/RR TPS Data Request";
CM_ SG_ 2348810242 TPMS_SnsrIdFrVal "TPMS ID Learning Information(FR)";
CM_ SG_ 2348810242 TPMS_SnsrIdRlVal "TPMS ID Learning Information(RL)";
CM_ BO_ 1459 "[TP] Transport Protocol";
CM_ SG_ 1459 GST_DHRL_Byte0 "Diag Request for DHRL";
CM_ SG_ 1459 GST_DHRL_Byte2 "Diag Request for DHRL";
CM_ SG_ 1459 GST_DHRL_Byte3 "Diag Request for DHRL";
CM_ SG_ 1459 GST_DHRL_Byte4 "Diag Request for DHRL";
CM_ SG_ 1459 GST_DHRL_Byte5 "Diag Request for DHRL";
CM_ SG_ 1459 GST_DHRL_Byte6 "Diag Request for DHRL";
CM_ SG_ 1459 GST_DHRL_Byte7 "Diag Request for DHRL";
CM_ SG_ 1459 GST_DHRL_Byte1 "Diag Request for DHRL";
CM_ BO_ 2683310258 "[EW] On Event and On Write";
CM_ SG_ 2683310258 ROA_Debug_08 "Debug Monitoring Data";
CM_ BO_ 1460 "[TP] Transport Protocol";
CM_ SG_ 1460 GST_DHRR_Byte0 "Diag Request for DHRR";
CM_ SG_ 1460 GST_DHRR_Byte2 "Diag Request for DHRR";
CM_ SG_ 1460 GST_DHRR_Byte3 "Diag Request for DHRR";
CM_ SG_ 1460 GST_DHRR_Byte4 "Diag Request for DHRR";
CM_ SG_ 1460 GST_DHRR_Byte5 "Diag Request for DHRR";
CM_ SG_ 1460 GST_DHRR_Byte6 "Diag Request for DHRR";
CM_ SG_ 1460 GST_DHRR_Byte7 "Diag Request for DHRR";
CM_ SG_ 1460 GST_DHRR_Byte1 "Diag Request for DHRR";
CM_ BO_ 2683310256 "[EW] On Event and On Write";
CM_ SG_ 2683310256 ROA_Debug_00 "Debug Monitoring Data";
CM_ SG_ 2683310256 ROA_Debug_02 "Debug Monitoring Data";
CM_ SG_ 2683310256 ROA_Debug_03 "Debug Monitoring Data";
CM_ SG_ 2683310256 ROA_Debug_01 "Debug Monitoring Data";
CM_ BO_ 2683310257 "[EW] On Event and On Write";
CM_ SG_ 2683310257 ROA_Debug_04 "Debug Monitoring Data";
CM_ SG_ 2683310257 ROA_Debug_06 "Debug Monitoring Data";
CM_ SG_ 2683310257 ROA_Debug_07 "Debug Monitoring Data";
CM_ SG_ 2683310257 ROA_Debug_05 "Debug Monitoring Data";
CM_ BO_ 2281701616 "[PE] Periodic and On Event";
CM_ SG_ 2281701616 L_UWB_RL_FD_Crc10Val "L_UWB_RL_FD_CyclicRedundancyCheck10Value";
CM_ SG_ 2281701616 UWB_RL_SW_MCU_Ver_Major "UWB RL SW MCU Version Major";
CM_ SG_ 2281701616 UWB_RL_SW_MCU_Ver_Minor "UWB RL SW MCU Version Minor";
CM_ SG_ 2281701616 UWB_RL_SW_IC_Ver_Major "UWB RL SW IC Version Major";
CM_ SG_ 2281701616 UWB_RL_SW_IC_Ver_Minor "UWB RL SW IC Version Minor";
CM_ SG_ 2281701616 UWB_RL_DTC "UWB RL DTC Data";
CM_ SG_ 2281701616 L_UWB_RL_FD_AlvCnt10Val "L_UWB_RL_FD_AliveCounter10Value";
CM_ SG_ 2281701616 UWB_RL_Status1 "UWB_RL Processing Status 1";
CM_ SG_ 2281701616 UWB_RL_Status2 "UWB_RL Processing Status 2";
CM_ SG_ 2281701616 UWB_RL_Status3 "UWB_RL Processing Status 3";
CM_ SG_ 2281701616 UWB_RL_Status4 "UWB_RL Processing Status 4";
CM_ SG_ 2281701616 UWB_RL_Status5 "UWB_RL Processing Status 5";
CM_ SG_ 2281701616 UWB_RL_Status6 "UWB_RL Processing Status 6";
CM_ SG_ 2281701616 UWB_RL_Status7 "UWB_RL Processing Status 7";
CM_ SG_ 2281701616 UWB_RL_Status8 "UWB_RL Processing Status 8";
CM_ SG_ 2281701616 UWB_RL_Status9 "UWB_RL Processing Status 9";
CM_ SG_ 2281701616 UWB_RL_Status10 "UWB_RL Processing Status 10";
CM_ SG_ 2281701616 UWB_RL_Status11 "UWB_RL Processing Status 11";
CM_ SG_ 2281701616 UWB_RL_Status12 "UWB_RL Processing Status 12";
CM_ SG_ 2281701616 UWB_RL_Status13 "UWB_RL Processing Status 13";
CM_ SG_ 2281701616 UWB_RL_Status14 "UWB_RL Processing Status 14";
CM_ SG_ 2281701616 UWB_RL_Status15 "UWB_RL Processing Status 15";
CM_ SG_ 2281701616 UWB_RL_Status16 "UWB_RL Processing Status 16";
CM_ SG_ 2281701616 UWB_RL_HW_Ver_Major "UWB RL HW Version Major";
CM_ SG_ 2281701616 UWB_RL_HW_Ver_Minor "UWB RL HW Version Minor";
CM_ BO_ 979 "[PE] Periodic and On Event";
CM_ SG_ 979 BDC_FD_Crc4Val "BDC_FD_CyclicRedundancyCheck4Value";
CM_ SG_ 979 BDC_FD_AlvCnt4Val "BDC_FD_AliveCounter4Value";
CM_ SG_ 979 BAlarm_BglrAlrm_CurrentSta "Only for CAN FD (SV~)";
CM_ SG_ 979 BAlarm_BglrAlrm_Sta "Only for CAN FD (SV~)";
CM_ SG_ 979 BAlarm_PncAlrmSta_Copy_0 "BAlarm_PanicAlarmStatus ##2G##BCM - BCMmsg17 - C_PanicState";
CM_ SG_ 979 SBR_StBltStpWrngBzrSta_Copy_0 "SBR_SeatBeltStepWarningBuzzerStatus ##2G##BCM - BCMmsg32 - C_SeatBeltWngBuzStep";
CM_ SG_ 979 SBR_StBltWrngBzrSta_Copy_0 "SBR_SeatBeltWarningBuzzerStatus ##2G##BCM - BCMmsg32 - C_SeatBeltWngBuz";
CM_ SG_ 979 BAlarm_BrglrHrnRlySta_Copy_0 "BAlarm_BurglarHornRelayStatus ##2G##BCM - BCMmsg19 - C_BurglarHornRly";
CM_ SG_ 979 SBR_DrvStBltIndSta_Copy_0 "SBR_DriverSeatBeltIndicatorStatus ##2G##BCM - BCMmsg32 - C_DrvSeatBeltInd";
CM_ SG_ 979 SBR_RrLftStBltWrngIndSta_Copy_0 "SBR_RearLeftSeatBeltWarningIndicatorStatus ##2G##BCM - BCMmsg32 - C_RLSeatBeltInd";
CM_ SG_ 979 SBR_RrRtStBltWrngIndSta_Copy_0 "SBR_RearRightSeatBeltWarningIndicatorStatus ##2G##BCM - BCMmsg32 - C_RRSeatBeltInd";
CM_ SG_ 979 SBR_RrCtrStBltIndSta_Copy_0 "SBR_RearCenterSeatBeltIndicatorStatus ##2G##BCM - BCMmsg32 - C_RCSeatBeltInd";
CM_ SG_ 979 SBR_3rdLftStBltWrngIndSta_Copy_0 "SBR_3rdLeftSeatBeltWarningIndicatorStatus ##2G##BCM - BCMmsg32 - C_3LSeatBeltInd";
CM_ SG_ 979 SBR_3rdRtStBltWrngIndSta_Copy_0 "SBR_3rdRightSeatBeltWarningIndicatorStatus ##2G##BCM - BCMmsg32 - C_3RSeatBeltInd";
CM_ SG_ 979 SBR_3rdCtrStBltWrngIndSta_Copy_0 "SBR_3rdCeterSeatBeltWarningIndicatorStatus ##2G##BCM - BCMmsg32 - C_3CSeatBeltInd";
CM_ SG_ 979 Warn_BzrWrngSta_Copy_0 "Warn_BuzzerWarningStatus ##2G##BCM - BCMmsg18 - C_WngBuz";
CM_ SG_ 979 Warn_BCMWrngSta_Copy_0 "Warn_BCMWarningStatus ##2G##BCM - BCMmsg19 - C_BCMWarning";
CM_ SG_ 979 ROA_RegionOpt_Copy_0 "A Euro NCAP Option signal (BDC only)";
CM_ SG_ 979 Warn_RrStRmndOpt_Copy_0 "Warn_RearSeatReminderOption ##2G##BCM - BCMmsg22 - C_RrSeatRemindOpt";
CM_ SG_ 979 Warn_RrStRmndAlrmOnReq_Copy_0 "Warn_RearSeatReminderAlarmOnRequest ##2G##BCM - BCMmsg22 - C_RrSeatRemindAlarm";
CM_ SG_ 979 Warn_RrStRmndSysSta_Copy_0 "Warn_RearSeatReminderSystemStatus ##2G##BCM - BCMmsg22 - C_RrSeatRemindState";
CM_ SG_ 979 Warn_RrStRmndAlrmInfo_Copy_0 "Warn_RearSeatReminderAlarmInformaion ##2G##BCM - BCMmsg22 - C_RrSeatRemindInfo";
CM_ SG_ 979 Warn_RoaErr_Copy_0 "Warn_RoaError##2G##BCM - BCMmsg22 - C_RoaError";
CM_ SG_ 979 Warn_RrStRmndDelay_Copy_0 "Warn_RStRmndDelay";
CM_ SG_ 979 Warn_RrStRmndSysAct_Copy_0 "Warn_RrStRmndSysAct";
CM_ SG_ 979 WAL_FobSearching_Copy_0 "IBU Walk Away Lock Fob Searching State for Radar ROA";
CM_ SG_ 979 Warn_RrStRmndSysOffIND_Copy_0 "Warning_RearSeatRemindSystemOffIND";
CM_ SG_ 979 Warn_VehNotPWrngSta_Copy_0 "Vehicle Not P Warning";
CM_ SG_ 979 Warn_RrStRmndAlrmInfo_1_Copy_0 "Warn_RearSeatReminderAlarmInformaion";
CM_ BO_ 2533736961 "[EW] On Event and On Write";
CM_ SG_ 2533736961 L_UWB_TRNK_FD_Crc6Val "L_UWB_TRNK_FD_CyclicRedundancyCheck6Value";
CM_ SG_ 2533736961 L_UWB_TRNK_FD_AlvCnt6Val "L_UWB_TRNK_FD_AliveCounter6Value";
CM_ SG_ 2533736961 TRNK_SWID_4_IVD_1 "UWB TRNK SW Unit 4 IVD1";
CM_ BO_ 1467 "[TP] Transport Protocol";
CM_ SG_ 1467 DHRL_GST_Byte0 "Diag Response from DHRL";
CM_ SG_ 1467 DHRL_GST_Byte2 "Diag Response from DHRL";
CM_ SG_ 1467 DHRL_GST_Byte3 "Diag Response from DHRL";
CM_ SG_ 1467 DHRL_GST_Byte4 "Diag Response from DHRL";
CM_ SG_ 1467 DHRL_GST_Byte5 "Diag Response from DHRL";
CM_ SG_ 1467 DHRL_GST_Byte6 "Diag Response from DHRL";
CM_ SG_ 1467 DHRL_GST_Byte7 "Diag Response from DHRL";
CM_ SG_ 1467 DHRL_GST_Byte1 "Diag Response from DHRL";
CM_ BO_ 977 "[PE] Periodic and On Event";
CM_ SG_ 977 BDC_FD_Crc2Val "BDC_FD_CyclicRedundancyCheck2Value";
CM_ SG_ 977 BDC_FD_AlvCnt2Val "BDC_FD_AliveCounter2Value";
CM_ SG_ 977 BCM_KeyInSta_Copy_0 "BCM_KeyInStatus ##2G##BCM - BCMmsg17 - C_KeyInSW";
CM_ SG_ 977 BCM_AccInSta_Copy_0 "BCM_AccInputStatus ##2G##BCM - BCMmsg17 - C_Acc";
CM_ SG_ 977 BCM_Ign1InSta_Copy_0 "BCM_Ignition1InputStatus ##2G##BCM - BCMmsg17 - C_Ign1";
CM_ SG_ 977 BCM_Ign2InSta_Copy_0 "BCM_Ignition1InputStatus ##2G##BCM - BCMmsg17 - C_Ign2";
CM_ SG_ 977 BCM_GearPosPSta_Copy_0 "BCM_GearPositionPStatus ##2G##BCM - BCMmsg17 - C_PpositiOn";
CM_ SG_ 977 BCM_SmkOptTyp_Copy_0 "BCM_SmkOptionType ##2G##BCM - BCMmsg17 - C_SMKOption";
CM_ SG_ 977 BDC_ResetOpSta_Copy_0 "This signal indicates whether the reset operation has been completed or not";
CM_ SG_ 977 IBU_SWVerMajor1_Copy_0 "First Word(ASCII) in IBU S/W Ver";
CM_ SG_ 977 IBU_SWVerMinor1_Copy_0 "Second Word(ASCII) in IBU S/W Ver";
CM_ SG_ 977 IBU_SWVerMinor2_Copy_0 "Third Word(ASCII) in IBU S/W Ver";
CM_ SG_ 977 BDC_PlatformVerType_Copy_0 "BDC Platform Type Information";
CM_ SG_ 977 BDC_PlatformVerDate_Copy_0 "BDC Platform Version Date Version Information";
CM_ BO_ 2529538561 "[EW] On Event and On Write";
CM_ SG_ 2529538561 L_UWB_RL_FD_Crc6Val "L_UWB_RL_FD_CyclicRedundancyCheck6Value";
CM_ SG_ 2529538561 L_UWB_RL_FD_AlvCnt6Val "L_UWB_RL_FD_AliveCounter6Value";
CM_ SG_ 2529538561 RL_SWID_4_IVD_1 "UWB RL SW Unit 4 IVD1";
CM_ BO_ 1468 "[TP] Transport Protocol";
CM_ SG_ 1468 DHRR_GST_Byte0 "Diag Response from DHRR";
CM_ SG_ 1468 DHRR_GST_Byte2 "Diag Response from DHRR";
CM_ SG_ 1468 DHRR_GST_Byte3 "Diag Response from DHRR";
CM_ SG_ 1468 DHRR_GST_Byte4 "Diag Response from DHRR";
CM_ SG_ 1468 DHRR_GST_Byte5 "Diag Response from DHRR";
CM_ SG_ 1468 DHRR_GST_Byte6 "Diag Response from DHRR";
CM_ SG_ 1468 DHRR_GST_Byte7 "Diag Response from DHRR";
CM_ SG_ 1468 DHRR_GST_Byte1 "Diag Response from DHRR";
BA_DEF_ BO_  "CANFD_BRS" ENUM  "0","1";
BA_DEF_ BO_  "GenMsgEVName" STRING ;
BA_DEF_ BO_  "NmAsrMessage" ENUM  "No","Yes";
BA_DEF_ BO_  "DiagState" ENUM  "No","Yes";
BA_DEF_ BO_  "DiagResponse" ENUM  "No","Yes";
BA_DEF_ BO_  "DiagRequest" ENUM  "No","Yes";
BA_DEF_ BO_  "TpMessage" ENUM  "No","Yes";
BA_DEF_ BO_  "UsrMsgIDSforwardDeviation" INT 0 100;
BA_DEF_ BO_  "UsrMsgIDSbackwardDeviation" INT 50 1000;
BA_DEF_ BO_  "GenMsgCycleTime" INT 0 2000;
BA_DEF_ BO_  "GenMsgStartDelayTime" INT 0 2000;
BA_DEF_ BO_  "GenMsgSendType" ENUM  "Cyclic","NoMsgSendType";
BA_DEF_ BO_  "GenMsgCycleTimeFast" INT 0 500;
BA_DEF_ BO_  "GenMsgDelayTime" INT 0 20;
BA_DEF_ BO_  "GenMsgILSupport" ENUM  "No","Yes";
BA_DEF_ BO_  "GenMsgNrOfRepetition" INT 0 3;
BA_DEF_ BO_  "TpTxIndex" INT 0 65535;
BA_DEF_ BO_  "VFrameFormat" ENUM  "StandardCAN","ExtendedCAN","reserved","reserved","reserved","reserved","reserved","reserved","reserved","reserved","reserved","reserved","reserved","reserved","StandardCAN_FD","ExtendedCAN_FD";
BA_DEF_ SG_  "UserSigValidity" ENUM  "B+","ACC","IG","IG1","IG2","IG3","IG1 or IG2","IG1 or IG3","Undef";
BA_DEF_ SG_  "TimeoutValue" STRING ;
BA_DEF_ SG_  "UsrSigPurpose" ENUM  "Undef","FN","DIAG","DIAG(Req)","DIAG(Res)","DIAG(Func)","DEV","CCP","NM","TP";
BA_DEF_ SG_  "GenSigStartValue" INT 0 1215752192;
BA_DEF_ SG_  "NetworkRequest" ENUM  "Yes","No";
BA_DEF_ SG_  "NetworkRequestHoldingTime" INT 0 65535;
BA_DEF_ SG_  "Description" STRING ;
BA_DEF_ SG_  "Version" STRING ;
BA_DEF_ SG_  "GenSigEnvVarType" ENUM  "Int","Float","Undef";
BA_DEF_ SG_  "GenSigSendType" ENUM  "Cyclic","OnWrite","OnWriteWithRepetition","OnChange","OnChangeWithRepetition","IfActive","IfActiveWithRepetition","NoSigSendType","OnChangeAndIfActive","OnChangeAndIfActiveWithRepetition";
BA_DEF_ SG_  "GwSigLatencyTime" INT 0 65536;
BA_DEF_ SG_  "GwSigMissingSourceType" ENUM  "Undef","OldValue","DefaultValue","InitialValue";
BA_DEF_ SG_  "NWM-WakeupAllowed" ENUM  "<n.a.>";
BA_DEF_ SG_  "RoutingFactor" INT 1 1215752192;
BA_DEF_ SG_  "SystemSignalLongSymbol" STRING ;
BA_DEF_REL_ BU_SG_REL_  "GenSigTimeoutTime" INT 0 7000;
BA_DEF_DEF_  "CANFD_BRS" "1";
BA_DEF_DEF_  "GenMsgEVName" "@Signame";
BA_DEF_DEF_  "NmAsrMessage" "No";
BA_DEF_DEF_  "DiagState" "No";
BA_DEF_DEF_  "DiagResponse" "No";
BA_DEF_DEF_  "DiagRequest" "No";
BA_DEF_DEF_  "TpMessage" "No";
BA_DEF_DEF_  "UsrMsgIDSforwardDeviation" 10;
BA_DEF_DEF_  "UsrMsgIDSbackwardDeviation" 100;
BA_DEF_DEF_  "GenMsgCycleTime" 200;
BA_DEF_DEF_  "GenMsgStartDelayTime" 0;
BA_DEF_DEF_  "GenMsgSendType" "NoMsgSendType";
BA_DEF_DEF_  "GenMsgCycleTimeFast" 40;
BA_DEF_DEF_  "GenMsgDelayTime" 20;
BA_DEF_DEF_  "GenMsgILSupport" "Yes";
BA_DEF_DEF_  "GenMsgNrOfRepetition" 3;
BA_DEF_DEF_  "TpTxIndex" 0;
BA_DEF_DEF_  "VFrameFormat" "StandardCAN";
BA_DEF_DEF_  "UserSigValidity" "IG";
BA_DEF_DEF_  "TimeoutValue" "";
BA_DEF_DEF_  "UsrSigPurpose" "FN";
BA_DEF_DEF_  "GenSigStartValue" 0;
BA_DEF_DEF_  "NetworkRequest" "No";
BA_DEF_DEF_  "NetworkRequestHoldingTime" 0;
BA_DEF_DEF_  "Description" "";
BA_DEF_DEF_  "Version" "";
BA_DEF_DEF_  "GenSigEnvVarType" "Undef";
BA_DEF_DEF_  "GenSigSendType" "NoSigSendType";
BA_DEF_DEF_  "GwSigLatencyTime" 40;
BA_DEF_DEF_  "GwSigMissingSourceType" "Undef";
BA_DEF_DEF_  "NWM-WakeupAllowed" "<n.a.>";
BA_DEF_DEF_  "RoutingFactor" 1;
BA_DEF_DEF_REL_ "GenSigTimeoutTime" 500;
BA_DEF_DEF_  "SystemSignalLongSymbol" "";
BA_ "GenMsgSendType" BO_ 994 0;
BA_ "VFrameFormat" BO_ 994 14;
BA_ "GenMsgSendType" BO_ 2348810241 0;
BA_ "VFrameFormat" BO_ 2348810241 15;
BA_ "GenMsgStartDelayTime" BO_ 996 10;
BA_ "GenMsgSendType" BO_ 996 0;
BA_ "VFrameFormat" BO_ 996 14;
BA_ "GenMsgNrOfRepetition" BO_ 2549874800 0;
BA_ "GenMsgCycleTimeFast" BO_ 2549874800 0;
BA_ "GenMsgCycleTime" BO_ 2549874800 100;
BA_ "GenMsgSendType" BO_ 2549874800 0;
BA_ "VFrameFormat" BO_ 2549874800 15;
BA_ "GenMsgSendType" BO_ 2348810242 0;
BA_ "VFrameFormat" BO_ 2348810242 15;
BA_ "TpTxIndex" BO_ 1459 213;
BA_ "TpMessage" BO_ 1459 1;
BA_ "GenMsgILSupport" BO_ 1459 0;
BA_ "DiagRequest" BO_ 1459 1;
BA_ "GenMsgNrOfRepetition" BO_ 1459 0;
BA_ "GenMsgCycleTimeFast" BO_ 1459 0;
BA_ "GenMsgCycleTime" BO_ 1459 0;
BA_ "VFrameFormat" BO_ 1459 14;
BA_ "GenMsgDelayTime" BO_ 2683310258 10;
BA_ "GenMsgCycleTime" BO_ 2683310258 0;
BA_ "VFrameFormat" BO_ 2683310258 15;
BA_ "TpTxIndex" BO_ 1460 214;
BA_ "TpMessage" BO_ 1460 1;
BA_ "GenMsgILSupport" BO_ 1460 0;
BA_ "DiagRequest" BO_ 1460 1;
BA_ "GenMsgNrOfRepetition" BO_ 1460 0;
BA_ "GenMsgCycleTimeFast" BO_ 1460 0;
BA_ "GenMsgCycleTime" BO_ 1460 0;
BA_ "VFrameFormat" BO_ 1460 14;
BA_ "GenMsgDelayTime" BO_ 2683310256 10;
BA_ "GenMsgCycleTime" BO_ 2683310256 0;
BA_ "VFrameFormat" BO_ 2683310256 15;
BA_ "GenMsgDelayTime" BO_ 2683310257 10;
BA_ "GenMsgCycleTime" BO_ 2683310257 0;
BA_ "VFrameFormat" BO_ 2683310257 15;
BA_ "GenMsgSendType" BO_ 2281701616 0;
BA_ "VFrameFormat" BO_ 2281701616 15;
BA_ "GenMsgSendType" BO_ 979 0;
BA_ "VFrameFormat" BO_ 979 14;
BA_ "GenMsgDelayTime" BO_ 2533736961 10;
BA_ "GenMsgCycleTime" BO_ 2533736961 0;
BA_ "VFrameFormat" BO_ 2533736961 15;
BA_ "TpTxIndex" BO_ 1467 213;
BA_ "TpMessage" BO_ 1467 1;
BA_ "GenMsgILSupport" BO_ 1467 0;
BA_ "DiagResponse" BO_ 1467 1;
BA_ "GenMsgNrOfRepetition" BO_ 1467 0;
BA_ "GenMsgCycleTimeFast" BO_ 1467 0;
BA_ "GenMsgCycleTime" BO_ 1467 0;
BA_ "VFrameFormat" BO_ 1467 14;
BA_ "GenMsgSendType" BO_ 977 0;
BA_ "VFrameFormat" BO_ 977 14;
BA_ "GenMsgDelayTime" BO_ 2529538561 10;
BA_ "GenMsgCycleTime" BO_ 2529538561 0;
BA_ "VFrameFormat" BO_ 2529538561 15;
BA_ "TpTxIndex" BO_ 1468 214;
BA_ "TpMessage" BO_ 1468 1;
BA_ "GenMsgILSupport" BO_ 1468 0;
BA_ "DiagResponse" BO_ 1468 1;
BA_ "GenMsgNrOfRepetition" BO_ 1468 0;
BA_ "GenMsgCycleTimeFast" BO_ 1468 0;
BA_ "GenMsgCycleTime" BO_ 1468 0;
BA_ "VFrameFormat" BO_ 1468 14;
BA_ "Version" SG_ 994 PDC_FD_Crc3Val "22.10.20";
BA_ "UserSigValidity" SG_ 994 PDC_FD_Crc3Val 3;
BA_ "GenSigStartValue" SG_ 994 PDC_FD_Crc3Val 65535;
BA_ "GenSigSendType" SG_ 994 PDC_FD_Crc3Val 4;
BA_ "Description" SG_ 994 PDC_FD_Crc3Val "The data area for CRC calculation is based on the data length (DLC) of the message DB.

The CRC shall be calculated over the entire data block (excluding the CRC bytes) including the user data, alive counter and Data ID



- CRC Polynomial (0x1021) , Ini";
BA_ "Version" SG_ 994 PDC_FD_AlvCnt3Val "22.10.20";
BA_ "UserSigValidity" SG_ 994 PDC_FD_AlvCnt3Val 3;
BA_ "GenSigSendType" SG_ 994 PDC_FD_AlvCnt3Val 4;
BA_ "Description" SG_ 994 PDC_FD_AlvCnt3Val "For the first transmission request for a data element the counter shall be initialized with 0 and shall be incremented by 1 for every subsequent send request. 

When the counter reaches the maximum value(0xFF), then it shall restart with 0 for the next s";
BA_ "Version" SG_ 994 Warn_DrvDrSwSta_Copy_0 "17.12.00";
BA_ "NetworkRequestHoldingTime" SG_ 994 Warn_DrvDrSwSta_Copy_0 5000;
BA_ "NetworkRequest" SG_ 994 Warn_DrvDrSwSta_Copy_0 0;
BA_ "UserSigValidity" SG_ 994 Warn_DrvDrSwSta_Copy_0 0;
BA_ "GenSigSendType" SG_ 994 Warn_DrvDrSwSta_Copy_0 4;
BA_ "Version" SG_ 994 Warn_AsstDrSwSta_Copy_0 "17.12.00";
BA_ "NetworkRequestHoldingTime" SG_ 994 Warn_AsstDrSwSta_Copy_0 5000;
BA_ "NetworkRequest" SG_ 994 Warn_AsstDrSwSta_Copy_0 0;
BA_ "UserSigValidity" SG_ 994 Warn_AsstDrSwSta_Copy_0 0;
BA_ "GenSigSendType" SG_ 994 Warn_AsstDrSwSta_Copy_0 4;
BA_ "Version" SG_ 994 Warn_RrLftDrSwSta_Copy_0 "17.12.00";
BA_ "NetworkRequestHoldingTime" SG_ 994 Warn_RrLftDrSwSta_Copy_0 5000;
BA_ "NetworkRequest" SG_ 994 Warn_RrLftDrSwSta_Copy_0 0;
BA_ "UserSigValidity" SG_ 994 Warn_RrLftDrSwSta_Copy_0 0;
BA_ "GenSigSendType" SG_ 994 Warn_RrLftDrSwSta_Copy_0 4;
BA_ "Version" SG_ 994 Warn_RrRtDrSwSta_Copy_0 "17.12.00";
BA_ "NetworkRequestHoldingTime" SG_ 994 Warn_RrRtDrSwSta_Copy_0 5000;
BA_ "NetworkRequest" SG_ 994 Warn_RrRtDrSwSta_Copy_0 0;
BA_ "UserSigValidity" SG_ 994 Warn_RrRtDrSwSta_Copy_0 0;
BA_ "GenSigSendType" SG_ 994 Warn_RrRtDrSwSta_Copy_0 4;
BA_ "Version" SG_ 994 Warn_HoodSwSta_Copy_0 "17.12.00";
BA_ "NetworkRequestHoldingTime" SG_ 994 Warn_HoodSwSta_Copy_0 5000;
BA_ "NetworkRequest" SG_ 994 Warn_HoodSwSta_Copy_0 0;
BA_ "UserSigValidity" SG_ 994 Warn_HoodSwSta_Copy_0 0;
BA_ "GenSigSendType" SG_ 994 Warn_HoodSwSta_Copy_0 4;
BA_ "Version" SG_ 994 DoorLock_DrvDrUnLkSta_Copy_0 "21.09.05";
BA_ "NetworkRequestHoldingTime" SG_ 994 DoorLock_DrvDrUnLkSta_Copy_0 5000;
BA_ "NetworkRequest" SG_ 994 DoorLock_DrvDrUnLkSta_Copy_0 0;
BA_ "UserSigValidity" SG_ 994 DoorLock_DrvDrUnLkSta_Copy_0 0;
BA_ "GenSigSendType" SG_ 994 DoorLock_DrvDrUnLkSta_Copy_0 4;
BA_ "Version" SG_ 994 DoorLock_AsstDrUnLkSta_Copy_0 "17.12.00";
BA_ "NetworkRequestHoldingTime" SG_ 994 DoorLock_AsstDrUnLkSta_Copy_0 5000;
BA_ "NetworkRequest" SG_ 994 DoorLock_AsstDrUnLkSta_Copy_0 0;
BA_ "UserSigValidity" SG_ 994 DoorLock_AsstDrUnLkSta_Copy_0 0;
BA_ "GenSigSendType" SG_ 994 DoorLock_AsstDrUnLkSta_Copy_0 4;
BA_ "Version" SG_ 994 DoorLock_RrLftDrUnLkSta_Copy_0 "17.12.00";
BA_ "NetworkRequestHoldingTime" SG_ 994 DoorLock_RrLftDrUnLkSta_Copy_0 5000;
BA_ "NetworkRequest" SG_ 994 DoorLock_RrLftDrUnLkSta_Copy_0 0;
BA_ "UserSigValidity" SG_ 994 DoorLock_RrLftDrUnLkSta_Copy_0 0;
BA_ "GenSigSendType" SG_ 994 DoorLock_RrLftDrUnLkSta_Copy_0 4;
BA_ "Version" SG_ 994 DoorLock_RrRtDrUnLkSta_Copy_0 "17.12.00";
BA_ "NetworkRequestHoldingTime" SG_ 994 DoorLock_RrRtDrUnLkSta_Copy_0 5000;
BA_ "NetworkRequest" SG_ 994 DoorLock_RrRtDrUnLkSta_Copy_0 0;
BA_ "UserSigValidity" SG_ 994 DoorLock_RrRtDrUnLkSta_Copy_0 0;
BA_ "GenSigSendType" SG_ 994 DoorLock_RrRtDrUnLkSta_Copy_0 4;
BA_ "Version" SG_ 994 DoorLock_DrvKeyLkSwSta_Copy_0 "17.12.00";
BA_ "NetworkRequestHoldingTime" SG_ 994 DoorLock_DrvKeyLkSwSta_Copy_0 5000;
BA_ "NetworkRequest" SG_ 994 DoorLock_DrvKeyLkSwSta_Copy_0 0;
BA_ "UserSigValidity" SG_ 994 DoorLock_DrvKeyLkSwSta_Copy_0 0;
BA_ "GenSigSendType" SG_ 994 DoorLock_DrvKeyLkSwSta_Copy_0 4;
BA_ "Version" SG_ 994 DoorLock_DrvKeyUnLkSwSta_Copy_0 "17.12.00";
BA_ "NetworkRequestHoldingTime" SG_ 994 DoorLock_DrvKeyUnLkSwSta_Copy_0 5000;
BA_ "NetworkRequest" SG_ 994 DoorLock_DrvKeyUnLkSwSta_Copy_0 0;
BA_ "UserSigValidity" SG_ 994 DoorLock_DrvKeyUnLkSwSta_Copy_0 0;
BA_ "GenSigSendType" SG_ 994 DoorLock_DrvKeyUnLkSwSta_Copy_0 4;
BA_ "Version" SG_ 994 DoorLock_CtrlDrLkSwSta_ICU_Copy_ "19.07.01";
BA_ "NetworkRequestHoldingTime" SG_ 994 DoorLock_CtrlDrLkSwSta_ICU_Copy_ 5000;
BA_ "NetworkRequest" SG_ 994 DoorLock_CtrlDrLkSwSta_ICU_Copy_ 0;
BA_ "UserSigValidity" SG_ 994 DoorLock_CtrlDrLkSwSta_ICU_Copy_ 0;
BA_ "GenSigSendType" SG_ 994 DoorLock_CtrlDrLkSwSta_ICU_Copy_ 4;
BA_ "Description" SG_ 994 DoorLock_CtrlDrLkSwSta_ICU_Copy_ "Central Door Lock Switch State

(DRV or AST or RL or RR Door trim)";
BA_ "SystemSignalLongSymbol" SG_ 994 DoorLock_CtrlDrLkSwSta_ICU_Copy_ "DoorLock_CtrlDrLkSwSta_ICU_Copy_0";
BA_ "Version" SG_ 994 DoorLock_CtrlDrUnLkSwSta_ICU_Cop "19.07.01";
BA_ "NetworkRequestHoldingTime" SG_ 994 DoorLock_CtrlDrUnLkSwSta_ICU_Cop 5000;
BA_ "NetworkRequest" SG_ 994 DoorLock_CtrlDrUnLkSwSta_ICU_Cop 0;
BA_ "UserSigValidity" SG_ 994 DoorLock_CtrlDrUnLkSwSta_ICU_Cop 0;
BA_ "GenSigSendType" SG_ 994 DoorLock_CtrlDrUnLkSwSta_ICU_Cop 4;
BA_ "Description" SG_ 994 DoorLock_CtrlDrUnLkSwSta_ICU_Cop "Central Door Unlock Switch State

(DRV or AST or RL or RR Door trim)";
BA_ "SystemSignalLongSymbol" SG_ 994 DoorLock_CtrlDrUnLkSwSta_ICU_Cop "DoorLock_CtrlDrUnLkSwSta_ICU_Copy_0";
BA_ "Version" SG_ 994 DoorLock_CtrlDrLkUnLkSwSta_ICU_C "19.07.01";
BA_ "NetworkRequestHoldingTime" SG_ 994 DoorLock_CtrlDrLkUnLkSwSta_ICU_C 5000;
BA_ "NetworkRequest" SG_ 994 DoorLock_CtrlDrLkUnLkSwSta_ICU_C 0;
BA_ "UserSigValidity" SG_ 994 DoorLock_CtrlDrLkUnLkSwSta_ICU_C 0;
BA_ "GenSigSendType" SG_ 994 DoorLock_CtrlDrLkUnLkSwSta_ICU_C 4;
BA_ "Description" SG_ 994 DoorLock_CtrlDrLkUnLkSwSta_ICU_C "Central Door Lock/Unlock Switch State

(C/PAD, Integrated & self return type)";
BA_ "SystemSignalLongSymbol" SG_ 994 DoorLock_CtrlDrLkUnLkSwSta_ICU_C "DoorLock_CtrlDrLkUnLkSwSta_ICU_Copy_0";
BA_ "Version" SG_ 994 C_CrashUnlockState_Copy_0 "21.07.05";
BA_ "NetworkRequest" SG_ 994 C_CrashUnlockState_Copy_0 0;
BA_ "UserSigValidity" SG_ 994 C_CrashUnlockState_Copy_0 0;
BA_ "GenSigSendType" SG_ 994 C_CrashUnlockState_Copy_0 4;
BA_ "Description" SG_ 994 C_CrashUnlockState_Copy_0 "Crash Unlock Active State

-0x0:Off

-0x1:Unlock(crash)";
BA_ "Version" SG_ 994 Lamp_LedHdLmpSta_Copy_0 "21.11.00";
BA_ "NetworkRequestHoldingTime" SG_ 994 Lamp_LedHdLmpSta_Copy_0 5000;
BA_ "NetworkRequest" SG_ 994 Lamp_LedHdLmpSta_Copy_0 0;
BA_ "UserSigValidity" SG_ 994 Lamp_LedHdLmpSta_Copy_0 3;
BA_ "GenSigSendType" SG_ 994 Lamp_LedHdLmpSta_Copy_0 4;
BA_ "Description" SG_ 994 Lamp_LedHdLmpSta_Copy_0 "This signal is LED headlamp status inform whether LED fail or not which is regulation of ECE, Domestic.



If LED H/Lamp detects LED failure then a cluster shall be turn on to 'LED' indicator in the display panel and It should be to display the words 'Ch";
BA_ "Version" SG_ 994 Warn_ChaDrSwFrtSta_Copy_0 "18.08.12";
BA_ "UserSigValidity" SG_ 994 Warn_ChaDrSwFrtSta_Copy_0 7;
BA_ "GenSigSendType" SG_ 994 Warn_ChaDrSwFrtSta_Copy_0 4;
BA_ "Description" SG_ 994 Warn_ChaDrSwFrtSta_Copy_0 "Front Charging Door Open Switch";
BA_ "Version" SG_ 994 Warn_ChaDrSwRrSta_Copy_0 "18.08.12";
BA_ "UserSigValidity" SG_ 994 Warn_ChaDrSwRrSta_Copy_0 7;
BA_ "GenSigSendType" SG_ 994 Warn_ChaDrSwRrSta_Copy_0 4;
BA_ "Description" SG_ 994 Warn_ChaDrSwRrSta_Copy_0 "Rear Charging Door Open Switch";
BA_ "Version" SG_ 2348810241 L_BDC_FD_Crc1Val "22.12.05";
BA_ "UserSigValidity" SG_ 2348810241 L_BDC_FD_Crc1Val 3;
BA_ "GenSigStartValue" SG_ 2348810241 L_BDC_FD_Crc1Val 65535;
BA_ "GenSigSendType" SG_ 2348810241 L_BDC_FD_Crc1Val 4;
BA_ "Description" SG_ 2348810241 L_BDC_FD_Crc1Val "The data area for CRC calculation is based on the data length (DLC) of the message DB.

The CRC shall be calculated over the entire data block (excluding the CRC bytes) including the user data, alive counter and Data ID



- CRC Polynomial (0x1021) , Ini";
BA_ "Version" SG_ 2348810241 MoodLamp_BottomBlueVal "22.12.05";
BA_ "NetworkRequestHoldingTime" SG_ 2348810241 MoodLamp_BottomBlueVal 5000;
BA_ "NetworkRequest" SG_ 2348810241 MoodLamp_BottomBlueVal 0;
BA_ "UserSigValidity" SG_ 2348810241 MoodLamp_BottomBlueVal 0;
BA_ "GenSigSendType" SG_ 2348810241 MoodLamp_BottomBlueVal 4;
BA_ "Version" SG_ 2348810241 MoodLamp_AIVoiceMicLevel "22.12.05";
BA_ "NetworkRequestHoldingTime" SG_ 2348810241 MoodLamp_AIVoiceMicLevel 5000;
BA_ "NetworkRequest" SG_ 2348810241 MoodLamp_AIVoiceMicLevel 0;
BA_ "UserSigValidity" SG_ 2348810241 MoodLamp_AIVoiceMicLevel 0;
BA_ "GenSigSendType" SG_ 2348810241 MoodLamp_AIVoiceMicLevel 4;
BA_ "Version" SG_ 2348810241 MoodLamp_AIVoiceTTSLevel "22.12.05";
BA_ "NetworkRequestHoldingTime" SG_ 2348810241 MoodLamp_AIVoiceTTSLevel 5000;
BA_ "NetworkRequest" SG_ 2348810241 MoodLamp_AIVoiceTTSLevel 0;
BA_ "UserSigValidity" SG_ 2348810241 MoodLamp_AIVoiceTTSLevel 0;
BA_ "GenSigSendType" SG_ 2348810241 MoodLamp_AIVoiceTTSLevel 4;
BA_ "Version" SG_ 2348810241 MoodLamp_VehicleSpeed "22.12.05";
BA_ "NetworkRequestHoldingTime" SG_ 2348810241 MoodLamp_VehicleSpeed 5000;
BA_ "NetworkRequest" SG_ 2348810241 MoodLamp_VehicleSpeed 0;
BA_ "UserSigValidity" SG_ 2348810241 MoodLamp_VehicleSpeed 0;
BA_ "GenSigSendType" SG_ 2348810241 MoodLamp_VehicleSpeed 4;
BA_ "Version" SG_ 2348810241 MoodLamp_MLBrghtModCmd_6bit "24.07.06";
BA_ "NetworkRequestHoldingTime" SG_ 2348810241 MoodLamp_MLBrghtModCmd_6bit 5000;
BA_ "NetworkRequest" SG_ 2348810241 MoodLamp_MLBrghtModCmd_6bit 0;
BA_ "UserSigValidity" SG_ 2348810241 MoodLamp_MLBrghtModCmd_6bit 0;
BA_ "GenSigSendType" SG_ 2348810241 MoodLamp_MLBrghtModCmd_6bit 4;
BA_ "Description" SG_ 2348810241 MoodLamp_MLBrghtModCmd_6bit "MoodLamp Brightness Mode Command (6bit)";
BA_ "Version" SG_ 2348810241 MoodLamp_MLColorModCmd_6bit "24.04.03";
BA_ "NetworkRequestHoldingTime" SG_ 2348810241 MoodLamp_MLColorModCmd_6bit 5000;
BA_ "NetworkRequest" SG_ 2348810241 MoodLamp_MLColorModCmd_6bit 0;
BA_ "UserSigValidity" SG_ 2348810241 MoodLamp_MLColorModCmd_6bit 0;
BA_ "GenSigSendType" SG_ 2348810241 MoodLamp_MLColorModCmd_6bit 4;
BA_ "Description" SG_ 2348810241 MoodLamp_MLColorModCmd_6bit "MoodLamp Color Mode Command (6bit)";
BA_ "Version" SG_ 2348810241 MoodLamp_DrvTempChgModCmd "24.05.01";
BA_ "NetworkRequestHoldingTime" SG_ 2348810241 MoodLamp_DrvTempChgModCmd 5000;
BA_ "NetworkRequest" SG_ 2348810241 MoodLamp_DrvTempChgModCmd 0;
BA_ "UserSigValidity" SG_ 2348810241 MoodLamp_DrvTempChgModCmd 0;
BA_ "GenSigSendType" SG_ 2348810241 MoodLamp_DrvTempChgModCmd 4;
BA_ "Description" SG_ 2348810241 MoodLamp_DrvTempChgModCmd "MoodLamp Driver Seat Temperature Change Mode Command";
BA_ "Version" SG_ 2348810241 MoodLamp_AstTempChgModCmd "24.05.01";
BA_ "NetworkRequestHoldingTime" SG_ 2348810241 MoodLamp_AstTempChgModCmd 5000;
BA_ "NetworkRequest" SG_ 2348810241 MoodLamp_AstTempChgModCmd 0;
BA_ "UserSigValidity" SG_ 2348810241 MoodLamp_AstTempChgModCmd 0;
BA_ "GenSigSendType" SG_ 2348810241 MoodLamp_AstTempChgModCmd 4;
BA_ "Description" SG_ 2348810241 MoodLamp_AstTempChgModCmd "MoodLamp Assist Seat Temperature Change Mode Command";
BA_ "Version" SG_ 2348810241 MoodLamp_PhoneCallModCmd "24.05.01";
BA_ "NetworkRequestHoldingTime" SG_ 2348810241 MoodLamp_PhoneCallModCmd 5000;
BA_ "NetworkRequest" SG_ 2348810241 MoodLamp_PhoneCallModCmd 0;
BA_ "UserSigValidity" SG_ 2348810241 MoodLamp_PhoneCallModCmd 1;
BA_ "GenSigSendType" SG_ 2348810241 MoodLamp_PhoneCallModCmd 4;
BA_ "Description" SG_ 2348810241 MoodLamp_PhoneCallModCmd "MoodLamp Phone Call Mode Command";
BA_ "Version" SG_ 2348810241 MoodLamp_AIVoiceRecogPosSta "24.05.01";
BA_ "NetworkRequestHoldingTime" SG_ 2348810241 MoodLamp_AIVoiceRecogPosSta 5000;
BA_ "NetworkRequest" SG_ 2348810241 MoodLamp_AIVoiceRecogPosSta 0;
BA_ "UserSigValidity" SG_ 2348810241 MoodLamp_AIVoiceRecogPosSta 0;
BA_ "GenSigSendType" SG_ 2348810241 MoodLamp_AIVoiceRecogPosSta 4;
BA_ "Description" SG_ 2348810241 MoodLamp_AIVoiceRecogPosSta "MoodLamp AIVoice Recognition Position Status";
BA_ "Version" SG_ 2348810241 MoodLamp_FLDoorWarnModCmd "24.05.01";
BA_ "NetworkRequestHoldingTime" SG_ 2348810241 MoodLamp_FLDoorWarnModCmd 5000;
BA_ "NetworkRequest" SG_ 2348810241 MoodLamp_FLDoorWarnModCmd 0;
BA_ "UserSigValidity" SG_ 2348810241 MoodLamp_FLDoorWarnModCmd 0;
BA_ "GenSigSendType" SG_ 2348810241 MoodLamp_FLDoorWarnModCmd 4;
BA_ "Description" SG_ 2348810241 MoodLamp_FLDoorWarnModCmd "MoodLamp Front-Left Door Warning Mode Command";
BA_ "Version" SG_ 2348810241 L_BDC_FD_AlvCnt1Val "22.12.05";
BA_ "UserSigValidity" SG_ 2348810241 L_BDC_FD_AlvCnt1Val 3;
BA_ "GenSigSendType" SG_ 2348810241 L_BDC_FD_AlvCnt1Val 4;
BA_ "Description" SG_ 2348810241 L_BDC_FD_AlvCnt1Val "For the first transmission request for a data element the counter shall be initialized with 0 and shall be incremented by 1 for every subsequent send request. 

When the counter reaches the maximum value(0xFF), then it shall restart with 0 for the next s";
BA_ "Version" SG_ 2348810241 MoodLamp_FRDoorWarnModCmd "24.05.01";
BA_ "NetworkRequestHoldingTime" SG_ 2348810241 MoodLamp_FRDoorWarnModCmd 5000;
BA_ "NetworkRequest" SG_ 2348810241 MoodLamp_FRDoorWarnModCmd 0;
BA_ "UserSigValidity" SG_ 2348810241 MoodLamp_FRDoorWarnModCmd 0;
BA_ "GenSigSendType" SG_ 2348810241 MoodLamp_FRDoorWarnModCmd 4;
BA_ "Description" SG_ 2348810241 MoodLamp_FRDoorWarnModCmd "MoodLamp Front-Right Door Warning Mode Command";
BA_ "Version" SG_ 2348810241 MoodLamp_RLDoorWarnModCmd "24.05.01";
BA_ "NetworkRequestHoldingTime" SG_ 2348810241 MoodLamp_RLDoorWarnModCmd 5000;
BA_ "NetworkRequest" SG_ 2348810241 MoodLamp_RLDoorWarnModCmd 0;
BA_ "UserSigValidity" SG_ 2348810241 MoodLamp_RLDoorWarnModCmd 0;
BA_ "GenSigSendType" SG_ 2348810241 MoodLamp_RLDoorWarnModCmd 4;
BA_ "Description" SG_ 2348810241 MoodLamp_RLDoorWarnModCmd "MoodLamp Rear-Left Door Warning Mode Command";
BA_ "Version" SG_ 2348810241 MoodLamp_RRDoorWarnModCmd "24.05.01";
BA_ "NetworkRequestHoldingTime" SG_ 2348810241 MoodLamp_RRDoorWarnModCmd 5000;
BA_ "NetworkRequest" SG_ 2348810241 MoodLamp_RRDoorWarnModCmd 0;
BA_ "UserSigValidity" SG_ 2348810241 MoodLamp_RRDoorWarnModCmd 0;
BA_ "GenSigSendType" SG_ 2348810241 MoodLamp_RRDoorWarnModCmd 4;
BA_ "Description" SG_ 2348810241 MoodLamp_RRDoorWarnModCmd "MoodLamp Rear-Right Door Warning Mode Command";
BA_ "Version" SG_ 2348810241 MoodLamp_HazardModCmd "24.05.01";
BA_ "NetworkRequestHoldingTime" SG_ 2348810241 MoodLamp_HazardModCmd 5000;
BA_ "NetworkRequest" SG_ 2348810241 MoodLamp_HazardModCmd 0;
BA_ "UserSigValidity" SG_ 2348810241 MoodLamp_HazardModCmd 0;
BA_ "GenSigSendType" SG_ 2348810241 MoodLamp_HazardModCmd 4;
BA_ "Description" SG_ 2348810241 MoodLamp_HazardModCmd "MoodLamp Hazard Lamp Linked Mode Command";
BA_ "Version" SG_ 2348810241 MoodLamp_FLDoorObstacleModCmd "24.05.01";
BA_ "NetworkRequestHoldingTime" SG_ 2348810241 MoodLamp_FLDoorObstacleModCmd 5000;
BA_ "NetworkRequest" SG_ 2348810241 MoodLamp_FLDoorObstacleModCmd 0;
BA_ "UserSigValidity" SG_ 2348810241 MoodLamp_FLDoorObstacleModCmd 0;
BA_ "GenSigSendType" SG_ 2348810241 MoodLamp_FLDoorObstacleModCmd 4;
BA_ "Description" SG_ 2348810241 MoodLamp_FLDoorObstacleModCmd "MoodLamp Front-Left Door Obstacle Mode Command";
BA_ "Version" SG_ 2348810241 MoodLamp_FRDoorObstacleModCmd "24.05.01";
BA_ "NetworkRequestHoldingTime" SG_ 2348810241 MoodLamp_FRDoorObstacleModCmd 5000;
BA_ "NetworkRequest" SG_ 2348810241 MoodLamp_FRDoorObstacleModCmd 0;
BA_ "UserSigValidity" SG_ 2348810241 MoodLamp_FRDoorObstacleModCmd 0;
BA_ "GenSigSendType" SG_ 2348810241 MoodLamp_FRDoorObstacleModCmd 4;
BA_ "Description" SG_ 2348810241 MoodLamp_FRDoorObstacleModCmd "MoodLamp Front-Right Door Obstacle Mode Command";
BA_ "Version" SG_ 2348810241 MoodLamp_RLDoorObstacleModCmd "24.05.01";
BA_ "NetworkRequestHoldingTime" SG_ 2348810241 MoodLamp_RLDoorObstacleModCmd 5000;
BA_ "NetworkRequest" SG_ 2348810241 MoodLamp_RLDoorObstacleModCmd 0;
BA_ "UserSigValidity" SG_ 2348810241 MoodLamp_RLDoorObstacleModCmd 0;
BA_ "GenSigSendType" SG_ 2348810241 MoodLamp_RLDoorObstacleModCmd 4;
BA_ "Description" SG_ 2348810241 MoodLamp_RLDoorObstacleModCmd "MoodLamp Rear-Left Door Obstacle Mode Command";
BA_ "Version" SG_ 2348810241 MoodLamp_RRDoorObstacleModCmd "24.05.01";
BA_ "NetworkRequestHoldingTime" SG_ 2348810241 MoodLamp_RRDoorObstacleModCmd 5000;
BA_ "NetworkRequest" SG_ 2348810241 MoodLamp_RRDoorObstacleModCmd 0;
BA_ "UserSigValidity" SG_ 2348810241 MoodLamp_RRDoorObstacleModCmd 0;
BA_ "GenSigSendType" SG_ 2348810241 MoodLamp_RRDoorObstacleModCmd 4;
BA_ "Description" SG_ 2348810241 MoodLamp_RRDoorObstacleModCmd "MoodLamp Rear-Right Door Obstacle Mode Command";
BA_ "Version" SG_ 2348810241 MoodLamp_LowFuelWarnModCmd "24.05.01";
BA_ "NetworkRequestHoldingTime" SG_ 2348810241 MoodLamp_LowFuelWarnModCmd 5000;
BA_ "NetworkRequest" SG_ 2348810241 MoodLamp_LowFuelWarnModCmd 0;
BA_ "UserSigValidity" SG_ 2348810241 MoodLamp_LowFuelWarnModCmd 0;
BA_ "GenSigSendType" SG_ 2348810241 MoodLamp_LowFuelWarnModCmd 4;
BA_ "Description" SG_ 2348810241 MoodLamp_LowFuelWarnModCmd "MoodLamp Low Fuel, AER Warning Mode Command";
BA_ "Version" SG_ 2348810241 MoodLamp_NShiftModCmd "24.05.01";
BA_ "NetworkRequestHoldingTime" SG_ 2348810241 MoodLamp_NShiftModCmd 5000;
BA_ "NetworkRequest" SG_ 2348810241 MoodLamp_NShiftModCmd 0;
BA_ "UserSigValidity" SG_ 2348810241 MoodLamp_NShiftModCmd 0;
BA_ "GenSigSendType" SG_ 2348810241 MoodLamp_NShiftModCmd 4;
BA_ "Description" SG_ 2348810241 MoodLamp_NShiftModCmd "MoodLamp N e-Shift Mode Command";
BA_ "Version" SG_ 2348810241 MoodLamp_MLBrghtModCmd "24.01.10";
BA_ "NetworkRequestHoldingTime" SG_ 2348810241 MoodLamp_MLBrghtModCmd 5000;
BA_ "NetworkRequest" SG_ 2348810241 MoodLamp_MLBrghtModCmd 0;
BA_ "UserSigValidity" SG_ 2348810241 MoodLamp_MLBrghtModCmd 0;
BA_ "GenSigSendType" SG_ 2348810241 MoodLamp_MLBrghtModCmd 4;
BA_ "Version" SG_ 2348810241 MoodLamp_MLColorModCmd "22.12.05";
BA_ "NetworkRequestHoldingTime" SG_ 2348810241 MoodLamp_MLColorModCmd 5000;
BA_ "NetworkRequest" SG_ 2348810241 MoodLamp_MLColorModCmd 0;
BA_ "UserSigValidity" SG_ 2348810241 MoodLamp_MLColorModCmd 0;
BA_ "GenSigSendType" SG_ 2348810241 MoodLamp_MLColorModCmd 4;
BA_ "Version" SG_ 2348810241 MoodLamp_WelcomeAndGoodbyeSeqMod "22.12.05";
BA_ "NetworkRequestHoldingTime" SG_ 2348810241 MoodLamp_WelcomeAndGoodbyeSeqMod 5000;
BA_ "NetworkRequest" SG_ 2348810241 MoodLamp_WelcomeAndGoodbyeSeqMod 0;
BA_ "UserSigValidity" SG_ 2348810241 MoodLamp_WelcomeAndGoodbyeSeqMod 0;
BA_ "GenSigSendType" SG_ 2348810241 MoodLamp_WelcomeAndGoodbyeSeqMod 4;
BA_ "SystemSignalLongSymbol" SG_ 2348810241 MoodLamp_WelcomeAndGoodbyeSeqMod "MoodLamp_WelcomeAndGoodbyeSeqModCmd";
BA_ "Version" SG_ 2348810241 MoodLamp_AIVoiceSeqModCmd "22.12.05";
BA_ "NetworkRequestHoldingTime" SG_ 2348810241 MoodLamp_AIVoiceSeqModCmd 5000;
BA_ "NetworkRequest" SG_ 2348810241 MoodLamp_AIVoiceSeqModCmd 0;
BA_ "UserSigValidity" SG_ 2348810241 MoodLamp_AIVoiceSeqModCmd 0;
BA_ "GenSigSendType" SG_ 2348810241 MoodLamp_AIVoiceSeqModCmd 4;
BA_ "Version" SG_ 2348810241 MoodLamp_EngineRunningSeqModCmd "22.12.05";
BA_ "NetworkRequestHoldingTime" SG_ 2348810241 MoodLamp_EngineRunningSeqModCmd 5000;
BA_ "NetworkRequest" SG_ 2348810241 MoodLamp_EngineRunningSeqModCmd 0;
BA_ "UserSigValidity" SG_ 2348810241 MoodLamp_EngineRunningSeqModCmd 0;
BA_ "GenSigSendType" SG_ 2348810241 MoodLamp_EngineRunningSeqModCmd 4;
BA_ "Version" SG_ 2348810241 MoodLamp_OverSpeedSeqModCmd "22.12.05";
BA_ "NetworkRequestHoldingTime" SG_ 2348810241 MoodLamp_OverSpeedSeqModCmd 5000;
BA_ "NetworkRequest" SG_ 2348810241 MoodLamp_OverSpeedSeqModCmd 0;
BA_ "UserSigValidity" SG_ 2348810241 MoodLamp_OverSpeedSeqModCmd 0;
BA_ "GenSigSendType" SG_ 2348810241 MoodLamp_OverSpeedSeqModCmd 4;
BA_ "Version" SG_ 2348810241 MoodLamp_DriveSeqModCmd "22.12.05";
BA_ "NetworkRequestHoldingTime" SG_ 2348810241 MoodLamp_DriveSeqModCmd 5000;
BA_ "NetworkRequest" SG_ 2348810241 MoodLamp_DriveSeqModCmd 0;
BA_ "UserSigValidity" SG_ 2348810241 MoodLamp_DriveSeqModCmd 0;
BA_ "GenSigSendType" SG_ 2348810241 MoodLamp_DriveSeqModCmd 4;
BA_ "Version" SG_ 2348810241 MoodLamp_AirCleaningSeqModCmd "22.12.05";
BA_ "NetworkRequestHoldingTime" SG_ 2348810241 MoodLamp_AirCleaningSeqModCmd 5000;
BA_ "NetworkRequest" SG_ 2348810241 MoodLamp_AirCleaningSeqModCmd 0;
BA_ "UserSigValidity" SG_ 2348810241 MoodLamp_AirCleaningSeqModCmd 0;
BA_ "GenSigSendType" SG_ 2348810241 MoodLamp_AirCleaningSeqModCmd 4;
BA_ "Version" SG_ 2348810241 MoodLamp_FootLampModCmd "23.03.00";
BA_ "NetworkRequestHoldingTime" SG_ 2348810241 MoodLamp_FootLampModCmd 5000;
BA_ "NetworkRequest" SG_ 2348810241 MoodLamp_FootLampModCmd 0;
BA_ "UserSigValidity" SG_ 2348810241 MoodLamp_FootLampModCmd 0;
BA_ "GenSigSendType" SG_ 2348810241 MoodLamp_FootLampModCmd 4;
BA_ "Version" SG_ 2348810241 MoodLamp_SunroofModCmd "22.12.05";
BA_ "NetworkRequestHoldingTime" SG_ 2348810241 MoodLamp_SunroofModCmd 5000;
BA_ "NetworkRequest" SG_ 2348810241 MoodLamp_SunroofModCmd 0;
BA_ "UserSigValidity" SG_ 2348810241 MoodLamp_SunroofModCmd 0;
BA_ "GenSigSendType" SG_ 2348810241 MoodLamp_SunroofModCmd 4;
BA_ "Version" SG_ 2348810241 MoodLamp_BrghtVal "22.12.05";
BA_ "NetworkRequestHoldingTime" SG_ 2348810241 MoodLamp_BrghtVal 5000;
BA_ "NetworkRequest" SG_ 2348810241 MoodLamp_BrghtVal 0;
BA_ "UserSigValidity" SG_ 2348810241 MoodLamp_BrghtVal 0;
BA_ "GenSigSendType" SG_ 2348810241 MoodLamp_BrghtVal 4;
BA_ "Version" SG_ 2348810241 MoodLamp_RedVal "22.12.05";
BA_ "NetworkRequestHoldingTime" SG_ 2348810241 MoodLamp_RedVal 5000;
BA_ "NetworkRequest" SG_ 2348810241 MoodLamp_RedVal 0;
BA_ "UserSigValidity" SG_ 2348810241 MoodLamp_RedVal 0;
BA_ "GenSigSendType" SG_ 2348810241 MoodLamp_RedVal 4;
BA_ "Version" SG_ 2348810241 MoodLamp_GreenVal "22.12.05";
BA_ "NetworkRequestHoldingTime" SG_ 2348810241 MoodLamp_GreenVal 5000;
BA_ "NetworkRequest" SG_ 2348810241 MoodLamp_GreenVal 0;
BA_ "UserSigValidity" SG_ 2348810241 MoodLamp_GreenVal 0;
BA_ "GenSigSendType" SG_ 2348810241 MoodLamp_GreenVal 4;
BA_ "Version" SG_ 2348810241 MoodLamp_BlueVal "22.12.05";
BA_ "NetworkRequestHoldingTime" SG_ 2348810241 MoodLamp_BlueVal 5000;
BA_ "NetworkRequest" SG_ 2348810241 MoodLamp_BlueVal 0;
BA_ "UserSigValidity" SG_ 2348810241 MoodLamp_BlueVal 0;
BA_ "GenSigSendType" SG_ 2348810241 MoodLamp_BlueVal 4;
BA_ "Version" SG_ 2348810241 MoodLamp_BottomRedVal "22.12.05";
BA_ "NetworkRequestHoldingTime" SG_ 2348810241 MoodLamp_BottomRedVal 5000;
BA_ "NetworkRequest" SG_ 2348810241 MoodLamp_BottomRedVal 0;
BA_ "UserSigValidity" SG_ 2348810241 MoodLamp_BottomRedVal 0;
BA_ "GenSigSendType" SG_ 2348810241 MoodLamp_BottomRedVal 4;
BA_ "Version" SG_ 2348810241 MoodLamp_BottomGreenVal "22.12.05";
BA_ "NetworkRequestHoldingTime" SG_ 2348810241 MoodLamp_BottomGreenVal 5000;
BA_ "NetworkRequest" SG_ 2348810241 MoodLamp_BottomGreenVal 0;
BA_ "UserSigValidity" SG_ 2348810241 MoodLamp_BottomGreenVal 0;
BA_ "GenSigSendType" SG_ 2348810241 MoodLamp_BottomGreenVal 4;
BA_ "Version" SG_ 996 PDC_FD_Crc10Val "22.10.20";
BA_ "UserSigValidity" SG_ 996 PDC_FD_Crc10Val 3;
BA_ "GenSigStartValue" SG_ 996 PDC_FD_Crc10Val 65535;
BA_ "GenSigSendType" SG_ 996 PDC_FD_Crc10Val 4;
BA_ "Description" SG_ 996 PDC_FD_Crc10Val "The data area for CRC calculation is based on the data length (DLC) of the message DB.

The CRC shall be calculated over the entire data block (excluding the CRC bytes) including the user data, alive counter and Data ID



- CRC Polynomial (0x1021) , Ini";
BA_ "Version" SG_ 996 PDC_PwrOnModePowerReq_Copy_0 "23.07.05";
BA_ "UserSigValidity" SG_ 996 PDC_PwrOnModePowerReq_Copy_0 0;
BA_ "TimeoutValue" SG_ 996 PDC_PwrOnModePowerReq_Copy_0 "0x0";
BA_ "GenSigSendType" SG_ 996 PDC_PwrOnModePowerReq_Copy_0 4;
BA_ "Description" SG_ 996 PDC_PwrOnModePowerReq_Copy_0 "This is for high voltage battery discharge request at Power On mode of EV";
BA_ "Version" SG_ 996 PDC_LeadAcidBatType_Copy_0 "23.06.02";
BA_ "UserSigValidity" SG_ 996 PDC_LeadAcidBatType_Copy_0 0;
BA_ "GenSigSendType" SG_ 996 PDC_LeadAcidBatType_Copy_0 4;
BA_ "Description" SG_ 996 PDC_LeadAcidBatType_Copy_0 "Lead Acid Battery Type Information

 - Validity

After EOL coding

 - Value Table

0x00:Not Applied

0x01:CMF 35Ah

0x02:CMF 40Ah

0x03:CMF 45Ah

0x04:CMF 50Ah

0x05:CMF 60Ah

0x06:CMF 68Ah

0x07:CMF 70Ah

0x08:CMF 80Ah

0x09:CMF 90Ah

0x0A:CMF 110Ah

0x";
BA_ "Version" SG_ 996 PDC_BatPwrClassOpt_Copy_0 "23.07.05";
BA_ "UserSigValidity" SG_ 996 PDC_BatPwrClassOpt_Copy_0 0;
BA_ "GenSigSendType" SG_ 996 PDC_BatPwrClassOpt_Copy_0 4;
BA_ "Description" SG_ 996 PDC_BatPwrClassOpt_Copy_0 "This signal informs which signal among soc and batpwrstateclass is regarded as the state of power.";
BA_ "Version" SG_ 996 PDC_MainLBMOpt "24.04.03";
BA_ "UserSigValidity" SG_ 996 PDC_MainLBMOpt 0;
BA_ "GenSigSendType" SG_ 996 PDC_MainLBMOpt 4;
BA_ "Description" SG_ 996 PDC_MainLBMOpt "This signal is always sended if PDC2 is appiled

it indicate whether MLBM is applied or not";
BA_ "Version" SG_ 996 PDC_FD_AlvCnt10Val "22.10.20";
BA_ "UserSigValidity" SG_ 996 PDC_FD_AlvCnt10Val 3;
BA_ "GenSigSendType" SG_ 996 PDC_FD_AlvCnt10Val 4;
BA_ "Description" SG_ 996 PDC_FD_AlvCnt10Val "For the first transmission request for a data element the counter shall be initialized with 0 and shall be incremented by 1 for every subsequent send request. 

When the counter reaches the maximum value(0xFF), then it shall restart with 0 for the next s";
BA_ "Version" SG_ 996 ICU_PowerAutoCutModSta_Copy_0 "22.06.05";
BA_ "UserSigValidity" SG_ 996 ICU_PowerAutoCutModSta_Copy_0 0;
BA_ "GenSigSendType" SG_ 996 ICU_PowerAutoCutModSta_Copy_0 4;
BA_ "Description" SG_ 996 ICU_PowerAutoCutModSta_Copy_0 "ICU Delivery Mode State";
BA_ "Version" SG_ 996 Autocut_DlvryModSta_Copy_0 "17.12.00";
BA_ "NetworkRequestHoldingTime" SG_ 996 Autocut_DlvryModSta_Copy_0 5000;
BA_ "NetworkRequest" SG_ 996 Autocut_DlvryModSta_Copy_0 0;
BA_ "UserSigValidity" SG_ 996 Autocut_DlvryModSta_Copy_0 0;
BA_ "GenSigStartValue" SG_ 996 Autocut_DlvryModSta_Copy_0 1;
BA_ "GenSigSendType" SG_ 996 Autocut_DlvryModSta_Copy_0 4;
BA_ "Description" SG_ 996 Autocut_DlvryModSta_Copy_0 "-(Old)C_SJB_DeliveryMode

-Initial value: 1";
BA_ "Version" SG_ 996 ICU_SoCBattStaMsgReq_Copy_0 "17.12.00";
BA_ "UserSigValidity" SG_ 996 ICU_SoCBattStaMsgReq_Copy_0 0;
BA_ "GenSigStartValue" SG_ 996 ICU_SoCBattStaMsgReq_Copy_0 3;
BA_ "GenSigSendType" SG_ 996 ICU_SoCBattStaMsgReq_Copy_0 4;
BA_ "Description" SG_ 996 ICU_SoCBattStaMsgReq_Copy_0 "Determine if soc level is warning or alert.";
BA_ "Version" SG_ 996 Batt_SoCWarningValue_Copy_0 "21.11.00";
BA_ "UserSigValidity" SG_ 996 Batt_SoCWarningValue_Copy_0 0;
BA_ "GenSigStartValue" SG_ 996 Batt_SoCWarningValue_Copy_0 255;
BA_ "GenSigSendType" SG_ 996 Batt_SoCWarningValue_Copy_0 4;
BA_ "Description" SG_ 996 Batt_SoCWarningValue_Copy_0 "This signal is Battery SOC from battery sensor.";
BA_ "Version" SG_ 996 ICU_BattAutoCutPreWrng_Copy_0 "20.04.06";
BA_ "UserSigValidity" SG_ 996 ICU_BattAutoCutPreWrng_Copy_0 0;
BA_ "GenSigStartValue" SG_ 996 ICU_BattAutoCutPreWrng_Copy_0 3;
BA_ "GenSigSendType" SG_ 996 ICU_BattAutoCutPreWrng_Copy_0 4;
BA_ "Description" SG_ 996 ICU_BattAutoCutPreWrng_Copy_0 "This is a warning signal before blocking the dark current of the ICU by the battery SOC.";
BA_ "Version" SG_ 996 OTAModeACCOffReq_Copy_0 "21.11.00";
BA_ "NetworkRequest" SG_ 996 OTAModeACCOffReq_Copy_0 0;
BA_ "UserSigValidity" SG_ 996 OTAModeACCOffReq_Copy_0 0;
BA_ "TimeoutValue" SG_ 996 OTAModeACCOffReq_Copy_0 "0x0";
BA_ "GenSigSendType" SG_ 996 OTAModeACCOffReq_Copy_0 4;
BA_ "Description" SG_ 996 OTAModeACCOffReq_Copy_0 "ACC off request during OTA mode for battery saver";
BA_ "Version" SG_ 996 C_ICUIGNOffReq_Copy_0 "21.11.00";
BA_ "NetworkRequest" SG_ 996 C_ICUIGNOffReq_Copy_0 0;
BA_ "UserSigValidity" SG_ 996 C_ICUIGNOffReq_Copy_0 0;
BA_ "TimeoutValue" SG_ 996 C_ICUIGNOffReq_Copy_0 "0x0";
BA_ "GenSigSendType" SG_ 996 C_ICUIGNOffReq_Copy_0 4;
BA_ "Description" SG_ 996 C_ICUIGNOffReq_Copy_0 "IGN off request(Not engine running state only) for battery saver";
BA_ "Version" SG_ 996 IGN_AutoOff_WarnSta_Copy_0 "21.11.00";
BA_ "UserSigValidity" SG_ 996 IGN_AutoOff_WarnSta_Copy_0 3;
BA_ "GenSigSendType" SG_ 996 IGN_AutoOff_WarnSta_Copy_0 4;
BA_ "Description" SG_ 996 IGN_AutoOff_WarnSta_Copy_0 "This signal is for battery discharge warning (engine not running && IGN/ACC on)

To prevent battery discharge, ICU requests the head unit to display warning and requests IBU to turn IGN/ACC off.";
BA_ "Version" SG_ 996 IGN_AutoOff_WarnSta_CLU_Copy_0 "21.11.00";
BA_ "UserSigValidity" SG_ 996 IGN_AutoOff_WarnSta_CLU_Copy_0 3;
BA_ "GenSigSendType" SG_ 996 IGN_AutoOff_WarnSta_CLU_Copy_0 4;
BA_ "Description" SG_ 996 IGN_AutoOff_WarnSta_CLU_Copy_0 "This signal is for battery discharge warning (engine not running && IGN/ACC on)

To prevent battery discharge, ICU requests the Cluster to display warning and requests IBU to turn IGN/ACC off.";
BA_ "Version" SG_ 996 PDC_BatPwrStateClassA_Copy_0 "23.07.06";
BA_ "UserSigValidity" SG_ 996 PDC_BatPwrStateClassA_Copy_0 0;
BA_ "GenSigSendType" SG_ 996 PDC_BatPwrStateClassA_Copy_0 4;
BA_ "Description" SG_ 996 PDC_BatPwrStateClassA_Copy_0 "This signal is used to inform whether the power state is good for the operation of the function using the low voltage.

0x1 : power state level is low

0x2: power staest level is good(high)";
BA_ "Version" SG_ 996 PDC_BatPwrStateClassB_Copy_0 "23.07.06";
BA_ "UserSigValidity" SG_ 996 PDC_BatPwrStateClassB_Copy_0 0;
BA_ "GenSigSendType" SG_ 996 PDC_BatPwrStateClassB_Copy_0 4;
BA_ "Description" SG_ 996 PDC_BatPwrStateClassB_Copy_0 "This signal is used to inform whether the power state is good for the operation of the function using the low voltage.

0x1 : power state level is low

0x2: power staest level is good(high)";
BA_ "Version" SG_ 996 PDC_BatPwrStateClassC_Copy_0 "23.07.06";
BA_ "UserSigValidity" SG_ 996 PDC_BatPwrStateClassC_Copy_0 0;
BA_ "GenSigSendType" SG_ 996 PDC_BatPwrStateClassC_Copy_0 4;
BA_ "Description" SG_ 996 PDC_BatPwrStateClassC_Copy_0 "This signal is used to inform whether the power state is good for the operation of the function using the low voltage.

0x1 : power state level is low

0x2: power staest level is good(high)";
BA_ "Version" SG_ 996 PLBMAvailableState_Copy_0 "21.06.11";
BA_ "UserSigValidity" SG_ 996 PLBMAvailableState_Copy_0 0;
BA_ "GenSigSendType" SG_ 996 PLBMAvailableState_Copy_0 4;
BA_ "Description" SG_ 996 PLBMAvailableState_Copy_0 "Power supply Available status notification at PLBM. If this value is Set, BMS can request Discharge-request to PDC during parking mode";
BA_ "Version" SG_ 996 Bat_dischrg_Copy_0 "21.11.00";
BA_ "UserSigValidity" SG_ 996 Bat_dischrg_Copy_0 3;
BA_ "GenSigSendType" SG_ 996 Bat_dischrg_Copy_0 4;
BA_ "Description" SG_ 996 Bat_dischrg_Copy_0 "Battery discharge notification flag";
BA_ "Version" SG_ 996 Bat12V_Chr_Req_Copy_0 "22.02.04";
BA_ "UserSigValidity" SG_ 996 Bat12V_Chr_Req_Copy_0 0;
BA_ "TimeoutValue" SG_ 996 Bat12V_Chr_Req_Copy_0 "0x0";
BA_ "GenSigSendType" SG_ 996 Bat12V_Chr_Req_Copy_0 4;
BA_ "Description" SG_ 996 Bat12V_Chr_Req_Copy_0 "12V lead acid battery charging request signal 

0x0:Off (Default)

0x1:On_IBS

0x2:On_OTA

0x3:On_Load";
BA_ "Version" SG_ 996 ICU_BattMngAlert_Copy_0 "21.07.05";
BA_ "UserSigValidity" SG_ 996 ICU_BattMngAlert_Copy_0 0;
BA_ "GenSigSendType" SG_ 996 ICU_BattMngAlert_Copy_0 4;
BA_ "Description" SG_ 996 ICU_BattMngAlert_Copy_0 "This signal is for battery discharge warning.

1bit : Hazard

2bit : Tail

3bit~8bit : Reserved";
BA_ "RoutingFactor" SG_ 2549874800 SNI_CGW_CCU 0;
BA_ "UserSigValidity" SG_ 2549874800 SNI_CGW_CCU 0;
BA_ "UsrSigPurpose" SG_ 2549874800 SNI_CGW_CCU 8;
BA_ "RoutingFactor" SG_ 2549874800 CBV_NMCoSRB_CGW_CCU 0;
BA_ "UserSigValidity" SG_ 2549874800 CBV_NMCoSRB_CGW_CCU 0;
BA_ "UsrSigPurpose" SG_ 2549874800 CBV_NMCoSRB_CGW_CCU 8;
BA_ "RoutingFactor" SG_ 2549874800 CBV_AWB_CGW_CCU 0;
BA_ "UserSigValidity" SG_ 2549874800 CBV_AWB_CGW_CCU 0;
BA_ "UsrSigPurpose" SG_ 2549874800 CBV_AWB_CGW_CCU 8;
BA_ "RoutingFactor" SG_ 2549874800 PNI_CGW_CCU_2 0;
BA_ "UserSigValidity" SG_ 2549874800 PNI_CGW_CCU_2 0;
BA_ "UsrSigPurpose" SG_ 2549874800 PNI_CGW_CCU_2 8;
BA_ "Description" SG_ 2549874800 PNI_CGW_CCU_2 "For PN ECUs, each partial networking cluster (PNC) is assigned a Partial Networking Information bit. The Partial Networking Information bit field contains the signals PNC_1 to PNC_224.







PNC_1(All ECUs), PNC_2(OTA Cooperative ECUs), PNC_3(OTA Cooper";
BA_ "RoutingFactor" SG_ 2549874800 CBV_PNIB_CGW_CCU 0;
BA_ "UserSigValidity" SG_ 2549874800 CBV_PNIB_CGW_CCU 0;
BA_ "UsrSigPurpose" SG_ 2549874800 CBV_PNIB_CGW_CCU 8;
BA_ "RoutingFactor" SG_ 2549874800 NRR_CGW_CCU 0;
BA_ "UserSigValidity" SG_ 2549874800 NRR_CGW_CCU 0;
BA_ "UsrSigPurpose" SG_ 2549874800 NRR_CGW_CCU 8;
BA_ "RoutingFactor" SG_ 2549874800 PNI_CGW_CCU_3 0;
BA_ "UserSigValidity" SG_ 2549874800 PNI_CGW_CCU_3 0;
BA_ "UsrSigPurpose" SG_ 2549874800 PNI_CGW_CCU_3 8;
BA_ "Description" SG_ 2549874800 PNI_CGW_CCU_3 "For PN ECUs, each partial networking cluster (PNC) is assigned a Partial Networking Information bit. The Partial Networking Information bit field contains the signals PNC_1 to PNC_224.







PNC_1(All ECUs), PNC_2(OTA Cooperative ECUs), PNC_3(OTA Cooper";
BA_ "RoutingFactor" SG_ 2549874800 NM_State_CGW_CCU 0;
BA_ "UserSigValidity" SG_ 2549874800 NM_State_CGW_CCU 0;
BA_ "UsrSigPurpose" SG_ 2549874800 NM_State_CGW_CCU 8;
BA_ "RoutingFactor" SG_ 2549874800 PNI_CGW_CCU 0;
BA_ "UserSigValidity" SG_ 2549874800 PNI_CGW_CCU 0;
BA_ "UsrSigPurpose" SG_ 2549874800 PNI_CGW_CCU 8;
BA_ "Description" SG_ 2549874800 PNI_CGW_CCU "For PN ECUs, each partial networking cluster (PNC) is assigned a Partial Networking Information bit. The Partial Networking Information bit field contains the signals PNC_1 to PNC_224.







PNC_1(All ECUs), PNC_2(OTA Cooperative ECUs), PNC_3(OTA Cooper";
BA_ "RoutingFactor" SG_ 2549874800 PNI_CGW_CCU_1 0;
BA_ "UserSigValidity" SG_ 2549874800 PNI_CGW_CCU_1 0;
BA_ "UsrSigPurpose" SG_ 2549874800 PNI_CGW_CCU_1 8;
BA_ "Description" SG_ 2549874800 PNI_CGW_CCU_1 "For PN ECUs, each partial networking cluster (PNC) is assigned a Partial Networking Information bit. The Partial Networking Information bit field contains the signals PNC_1 to PNC_224.







PNC_1(All ECUs), PNC_2(OTA Cooperative ECUs), PNC_3(OTA Cooper";
BA_ "RoutingFactor" SG_ 2549874800 CBV_RMR_CGW_CCU 0;
BA_ "UserSigValidity" SG_ 2549874800 CBV_RMR_CGW_CCU 0;
BA_ "UsrSigPurpose" SG_ 2549874800 CBV_RMR_CGW_CCU 8;
BA_ "RoutingFactor" SG_ 2549874800 CBV_NMCoID_CGW_CCU 0;
BA_ "UserSigValidity" SG_ 2549874800 CBV_NMCoID_CGW_CCU 0;
BA_ "UsrSigPurpose" SG_ 2549874800 CBV_NMCoID_CGW_CCU 8;
BA_ "Version" SG_ 2348810242 TPMS_SnsrIdRrVal "23.07.04";
BA_ "UserSigValidity" SG_ 2348810242 TPMS_SnsrIdRrVal 3;
BA_ "GenSigSendType" SG_ 2348810242 TPMS_SnsrIdRrVal 4;
BA_ "Description" SG_ 2348810242 TPMS_SnsrIdRrVal "TPMS ID Learning Information of rear right sensor.";
BA_ "Version" SG_ 2348810242 TPMS_FrontLowPressureWarnSetVal "23.07.04";
BA_ "UserSigValidity" SG_ 2348810242 TPMS_FrontLowPressureWarnSetVal 3;
BA_ "GenSigSendType" SG_ 2348810242 TPMS_FrontLowPressureWarnSetVal 4;
BA_ "Description" SG_ 2348810242 TPMS_FrontLowPressureWarnSetVal "Front tire low pressure warning reference air pressure.";
BA_ "Version" SG_ 2348810242 TPMS_RearLowPressureWarnSetVal "23.07.04";
BA_ "UserSigValidity" SG_ 2348810242 TPMS_RearLowPressureWarnSetVal 3;
BA_ "GenSigSendType" SG_ 2348810242 TPMS_RearLowPressureWarnSetVal 4;
BA_ "Description" SG_ 2348810242 TPMS_RearLowPressureWarnSetVal "Rear tire low pressure warning reference air pressure";
BA_ "Version" SG_ 2348810242 TPMS_FrontLowPressureWarnClearVa "23.07.04";
BA_ "UserSigValidity" SG_ 2348810242 TPMS_FrontLowPressureWarnClearVa 3;
BA_ "GenSigSendType" SG_ 2348810242 TPMS_FrontLowPressureWarnClearVa 4;
BA_ "Description" SG_ 2348810242 TPMS_FrontLowPressureWarnClearVa "Front tire low pressure Warning release reference pressure";
BA_ "SystemSignalLongSymbol" SG_ 2348810242 TPMS_FrontLowPressureWarnClearVa "TPMS_FrontLowPressureWarnClearVal";
BA_ "Version" SG_ 2348810242 TPMS_RearLowPressureWarnClearVal "23.07.04";
BA_ "UserSigValidity" SG_ 2348810242 TPMS_RearLowPressureWarnClearVal 3;
BA_ "GenSigSendType" SG_ 2348810242 TPMS_RearLowPressureWarnClearVal 4;
BA_ "Description" SG_ 2348810242 TPMS_RearLowPressureWarnClearVal "Rear tire low pressure Warning release reference pressure";
BA_ "Version" SG_ 2348810242 TPMS_SensorSupplierInfo "24.07.05";
BA_ "UserSigValidity" SG_ 2348810242 TPMS_SensorSupplierInfo 3;
BA_ "GenSigSendType" SG_ 2348810242 TPMS_SensorSupplierInfo 4;
BA_ "Description" SG_ 2348810242 TPMS_SensorSupplierInfo "TPMS Sensor Supplier Info";
BA_ "Version" SG_ 2348810242 TPMS_RfConfigueVal "24.07.05";
BA_ "UserSigValidity" SG_ 2348810242 TPMS_RfConfigueVal 3;
BA_ "GenSigSendType" SG_ 2348810242 TPMS_RfConfigueVal 4;
BA_ "Description" SG_ 2348810242 TPMS_RfConfigueVal "RF Frequency Info by Sales Area";
BA_ "Version" SG_ 2348810242 TPMS_SnsrIdFlVal "23.07.04";
BA_ "UserSigValidity" SG_ 2348810242 TPMS_SnsrIdFlVal 3;
BA_ "GenSigSendType" SG_ 2348810242 TPMS_SnsrIdFlVal 4;
BA_ "Description" SG_ 2348810242 TPMS_SnsrIdFlVal "TPMS ID Learning Information of front left sensor.";
BA_ "Version" SG_ 2348810242 TPMS_LowPressureWarnSta "24.07.03";
BA_ "UserSigValidity" SG_ 2348810242 TPMS_LowPressureWarnSta 0;
BA_ "GenSigSendType" SG_ 2348810242 TPMS_LowPressureWarnSta 4;
BA_ "Description" SG_ 2348810242 TPMS_LowPressureWarnSta "Low pressure warning status by tire position

- b0000 : No low pressure

- b0001: FL position low pressure

- b0010 : FR position low pressure

- b0100: RL position low pressure

- b1000: RR position low pressure

б╪ When transmitting multi-position low ";
BA_ "Version" SG_ 2348810242 TPMS_LastTpsDataReq "24.07.03";
BA_ "UserSigValidity" SG_ 2348810242 TPMS_LastTpsDataReq 0;
BA_ "GenSigSendType" SG_ 2348810242 TPMS_LastTpsDataReq 4;
BA_ "Description" SG_ 2348810242 TPMS_LastTpsDataReq "The signal request for last tpms sensor data.";
BA_ "Version" SG_ 2348810242 TPMS_SnsrIdFrVal "23.07.04";
BA_ "UserSigValidity" SG_ 2348810242 TPMS_SnsrIdFrVal 3;
BA_ "GenSigSendType" SG_ 2348810242 TPMS_SnsrIdFrVal 4;
BA_ "Description" SG_ 2348810242 TPMS_SnsrIdFrVal "TPMS ID Learning Information of front right sensor.";
BA_ "Version" SG_ 2348810242 TPMS_SnsrIdRlVal "23.07.04";
BA_ "UserSigValidity" SG_ 2348810242 TPMS_SnsrIdRlVal 3;
BA_ "GenSigSendType" SG_ 2348810242 TPMS_SnsrIdRlVal 4;
BA_ "Description" SG_ 2348810242 TPMS_SnsrIdRlVal "TPMS ID Learning Information of rear left sensor.";
BA_ "Version" SG_ 1459 GST_DHRL_Byte0 "21.02.04";
BA_ "NetworkRequestHoldingTime" SG_ 1459 GST_DHRL_Byte0 5000;
BA_ "NetworkRequest" SG_ 1459 GST_DHRL_Byte0 0;
BA_ "UserSigValidity" SG_ 1459 GST_DHRL_Byte0 0;
BA_ "UsrSigPurpose" SG_ 1459 GST_DHRL_Byte0 3;
BA_ "Description" SG_ 1459 GST_DHRL_Byte0 "TP Index : 213";
BA_ "Version" SG_ 1459 GST_DHRL_Byte2 "21.02.04";
BA_ "NetworkRequestHoldingTime" SG_ 1459 GST_DHRL_Byte2 5000;
BA_ "NetworkRequest" SG_ 1459 GST_DHRL_Byte2 0;
BA_ "UserSigValidity" SG_ 1459 GST_DHRL_Byte2 0;
BA_ "UsrSigPurpose" SG_ 1459 GST_DHRL_Byte2 3;
BA_ "Description" SG_ 1459 GST_DHRL_Byte2 "TP Index : 213";
BA_ "Version" SG_ 1459 GST_DHRL_Byte3 "21.02.04";
BA_ "NetworkRequestHoldingTime" SG_ 1459 GST_DHRL_Byte3 5000;
BA_ "NetworkRequest" SG_ 1459 GST_DHRL_Byte3 0;
BA_ "UserSigValidity" SG_ 1459 GST_DHRL_Byte3 0;
BA_ "UsrSigPurpose" SG_ 1459 GST_DHRL_Byte3 3;
BA_ "Description" SG_ 1459 GST_DHRL_Byte3 "TP Index : 213";
BA_ "Version" SG_ 1459 GST_DHRL_Byte4 "21.02.04";
BA_ "NetworkRequestHoldingTime" SG_ 1459 GST_DHRL_Byte4 5000;
BA_ "NetworkRequest" SG_ 1459 GST_DHRL_Byte4 0;
BA_ "UserSigValidity" SG_ 1459 GST_DHRL_Byte4 0;
BA_ "UsrSigPurpose" SG_ 1459 GST_DHRL_Byte4 3;
BA_ "Description" SG_ 1459 GST_DHRL_Byte4 "TP Index : 213";
BA_ "Version" SG_ 1459 GST_DHRL_Byte5 "21.02.04";
BA_ "NetworkRequestHoldingTime" SG_ 1459 GST_DHRL_Byte5 5000;
BA_ "NetworkRequest" SG_ 1459 GST_DHRL_Byte5 0;
BA_ "UserSigValidity" SG_ 1459 GST_DHRL_Byte5 0;
BA_ "UsrSigPurpose" SG_ 1459 GST_DHRL_Byte5 3;
BA_ "Description" SG_ 1459 GST_DHRL_Byte5 "TP Index : 213";
BA_ "Version" SG_ 1459 GST_DHRL_Byte6 "21.02.04";
BA_ "NetworkRequestHoldingTime" SG_ 1459 GST_DHRL_Byte6 5000;
BA_ "NetworkRequest" SG_ 1459 GST_DHRL_Byte6 0;
BA_ "UserSigValidity" SG_ 1459 GST_DHRL_Byte6 0;
BA_ "UsrSigPurpose" SG_ 1459 GST_DHRL_Byte6 3;
BA_ "Description" SG_ 1459 GST_DHRL_Byte6 "TP Index : 213";
BA_ "Version" SG_ 1459 GST_DHRL_Byte7 "21.02.04";
BA_ "NetworkRequestHoldingTime" SG_ 1459 GST_DHRL_Byte7 5000;
BA_ "NetworkRequest" SG_ 1459 GST_DHRL_Byte7 0;
BA_ "UserSigValidity" SG_ 1459 GST_DHRL_Byte7 0;
BA_ "UsrSigPurpose" SG_ 1459 GST_DHRL_Byte7 3;
BA_ "Description" SG_ 1459 GST_DHRL_Byte7 "TP Index : 213";
BA_ "Version" SG_ 1459 GST_DHRL_Byte1 "21.02.04";
BA_ "NetworkRequestHoldingTime" SG_ 1459 GST_DHRL_Byte1 5000;
BA_ "NetworkRequest" SG_ 1459 GST_DHRL_Byte1 0;
BA_ "UserSigValidity" SG_ 1459 GST_DHRL_Byte1 0;
BA_ "UsrSigPurpose" SG_ 1459 GST_DHRL_Byte1 3;
BA_ "Description" SG_ 1459 GST_DHRL_Byte1 "TP Index : 213";
BA_ "Version" SG_ 2683310258 ROA_Debug_08 "23.07.02";
BA_ "UserSigValidity" SG_ 2683310258 ROA_Debug_08 0;
BA_ "GenSigSendType" SG_ 2683310258 ROA_Debug_08 2;
BA_ "Version" SG_ 1460 GST_DHRR_Byte0 "21.02.04";
BA_ "NetworkRequestHoldingTime" SG_ 1460 GST_DHRR_Byte0 5000;
BA_ "NetworkRequest" SG_ 1460 GST_DHRR_Byte0 0;
BA_ "UserSigValidity" SG_ 1460 GST_DHRR_Byte0 0;
BA_ "UsrSigPurpose" SG_ 1460 GST_DHRR_Byte0 3;
BA_ "Description" SG_ 1460 GST_DHRR_Byte0 "TP Index : 214";
BA_ "Version" SG_ 1460 GST_DHRR_Byte2 "21.02.04";
BA_ "NetworkRequestHoldingTime" SG_ 1460 GST_DHRR_Byte2 5000;
BA_ "NetworkRequest" SG_ 1460 GST_DHRR_Byte2 0;
BA_ "UserSigValidity" SG_ 1460 GST_DHRR_Byte2 0;
BA_ "UsrSigPurpose" SG_ 1460 GST_DHRR_Byte2 3;
BA_ "Description" SG_ 1460 GST_DHRR_Byte2 "TP Index : 214";
BA_ "Version" SG_ 1460 GST_DHRR_Byte3 "21.02.04";
BA_ "NetworkRequestHoldingTime" SG_ 1460 GST_DHRR_Byte3 5000;
BA_ "NetworkRequest" SG_ 1460 GST_DHRR_Byte3 0;
BA_ "UserSigValidity" SG_ 1460 GST_DHRR_Byte3 0;
BA_ "UsrSigPurpose" SG_ 1460 GST_DHRR_Byte3 3;
BA_ "Description" SG_ 1460 GST_DHRR_Byte3 "TP Index : 214";
BA_ "Version" SG_ 1460 GST_DHRR_Byte4 "21.02.04";
BA_ "NetworkRequestHoldingTime" SG_ 1460 GST_DHRR_Byte4 5000;
BA_ "NetworkRequest" SG_ 1460 GST_DHRR_Byte4 0;
BA_ "UserSigValidity" SG_ 1460 GST_DHRR_Byte4 0;
BA_ "UsrSigPurpose" SG_ 1460 GST_DHRR_Byte4 3;
BA_ "Description" SG_ 1460 GST_DHRR_Byte4 "TP Index : 214";
BA_ "Version" SG_ 1460 GST_DHRR_Byte5 "21.02.04";
BA_ "NetworkRequestHoldingTime" SG_ 1460 GST_DHRR_Byte5 5000;
BA_ "NetworkRequest" SG_ 1460 GST_DHRR_Byte5 0;
BA_ "UserSigValidity" SG_ 1460 GST_DHRR_Byte5 0;
BA_ "UsrSigPurpose" SG_ 1460 GST_DHRR_Byte5 3;
BA_ "Description" SG_ 1460 GST_DHRR_Byte5 "TP Index : 214";
BA_ "Version" SG_ 1460 GST_DHRR_Byte6 "21.02.04";
BA_ "NetworkRequestHoldingTime" SG_ 1460 GST_DHRR_Byte6 5000;
BA_ "NetworkRequest" SG_ 1460 GST_DHRR_Byte6 0;
BA_ "UserSigValidity" SG_ 1460 GST_DHRR_Byte6 0;
BA_ "UsrSigPurpose" SG_ 1460 GST_DHRR_Byte6 3;
BA_ "Description" SG_ 1460 GST_DHRR_Byte6 "TP Index : 214";
BA_ "Version" SG_ 1460 GST_DHRR_Byte7 "21.02.04";
BA_ "NetworkRequestHoldingTime" SG_ 1460 GST_DHRR_Byte7 5000;
BA_ "NetworkRequest" SG_ 1460 GST_DHRR_Byte7 0;
BA_ "UserSigValidity" SG_ 1460 GST_DHRR_Byte7 0;
BA_ "UsrSigPurpose" SG_ 1460 GST_DHRR_Byte7 3;
BA_ "Description" SG_ 1460 GST_DHRR_Byte7 "TP Index : 214";
BA_ "Version" SG_ 1460 GST_DHRR_Byte1 "21.02.04";
BA_ "NetworkRequestHoldingTime" SG_ 1460 GST_DHRR_Byte1 5000;
BA_ "NetworkRequest" SG_ 1460 GST_DHRR_Byte1 0;
BA_ "UserSigValidity" SG_ 1460 GST_DHRR_Byte1 0;
BA_ "UsrSigPurpose" SG_ 1460 GST_DHRR_Byte1 3;
BA_ "Description" SG_ 1460 GST_DHRR_Byte1 "TP Index : 214";
BA_ "Version" SG_ 2683310256 ROA_Debug_00 "23.07.02";
BA_ "UserSigValidity" SG_ 2683310256 ROA_Debug_00 0;
BA_ "GenSigSendType" SG_ 2683310256 ROA_Debug_00 2;
BA_ "Version" SG_ 2683310256 ROA_Debug_02 "23.07.02";
BA_ "UserSigValidity" SG_ 2683310256 ROA_Debug_02 0;
BA_ "GenSigSendType" SG_ 2683310256 ROA_Debug_02 2;
BA_ "Version" SG_ 2683310256 ROA_Debug_03 "23.07.02";
BA_ "UserSigValidity" SG_ 2683310256 ROA_Debug_03 0;
BA_ "GenSigSendType" SG_ 2683310256 ROA_Debug_03 2;
BA_ "Version" SG_ 2683310256 ROA_Debug_01 "23.07.02";
BA_ "UserSigValidity" SG_ 2683310256 ROA_Debug_01 0;
BA_ "GenSigSendType" SG_ 2683310256 ROA_Debug_01 2;
BA_ "Version" SG_ 2683310257 ROA_Debug_04 "23.07.02";
BA_ "UserSigValidity" SG_ 2683310257 ROA_Debug_04 0;
BA_ "GenSigSendType" SG_ 2683310257 ROA_Debug_04 2;
BA_ "Version" SG_ 2683310257 ROA_Debug_06 "23.07.02";
BA_ "UserSigValidity" SG_ 2683310257 ROA_Debug_06 0;
BA_ "GenSigSendType" SG_ 2683310257 ROA_Debug_06 2;
BA_ "Version" SG_ 2683310257 ROA_Debug_07 "23.07.02";
BA_ "UserSigValidity" SG_ 2683310257 ROA_Debug_07 0;
BA_ "GenSigSendType" SG_ 2683310257 ROA_Debug_07 2;
BA_ "Version" SG_ 2683310257 ROA_Debug_05 "23.07.02";
BA_ "UserSigValidity" SG_ 2683310257 ROA_Debug_05 0;
BA_ "GenSigSendType" SG_ 2683310257 ROA_Debug_05 2;
BA_ "Version" SG_ 2281701616 L_UWB_RL_FD_Crc10Val "23.01.02";
BA_ "UserSigValidity" SG_ 2281701616 L_UWB_RL_FD_Crc10Val 3;
BA_ "GenSigStartValue" SG_ 2281701616 L_UWB_RL_FD_Crc10Val 65535;
BA_ "GenSigSendType" SG_ 2281701616 L_UWB_RL_FD_Crc10Val 4;
BA_ "Description" SG_ 2281701616 L_UWB_RL_FD_Crc10Val "The data area for CRC calculation is based on the data length (DLC) of the message DB.

The CRC shall be calculated over the entire data block (excluding the CRC bytes) including the user data, alive counter and Data ID



- CRC Polynomial (0x1021) , Ini";
BA_ "Version" SG_ 2281701616 UWB_RL_SW_MCU_Ver_Major "23.01.02";
BA_ "UserSigValidity" SG_ 2281701616 UWB_RL_SW_MCU_Ver_Major 0;
BA_ "GenSigSendType" SG_ 2281701616 UWB_RL_SW_MCU_Ver_Major 4;
BA_ "Version" SG_ 2281701616 UWB_RL_SW_MCU_Ver_Minor "23.01.02";
BA_ "UserSigValidity" SG_ 2281701616 UWB_RL_SW_MCU_Ver_Minor 0;
BA_ "GenSigSendType" SG_ 2281701616 UWB_RL_SW_MCU_Ver_Minor 4;
BA_ "Version" SG_ 2281701616 UWB_RL_SW_IC_Ver_Major "23.01.02";
BA_ "UserSigValidity" SG_ 2281701616 UWB_RL_SW_IC_Ver_Major 0;
BA_ "GenSigSendType" SG_ 2281701616 UWB_RL_SW_IC_Ver_Major 4;
BA_ "Version" SG_ 2281701616 UWB_RL_SW_IC_Ver_Minor "23.01.02";
BA_ "UserSigValidity" SG_ 2281701616 UWB_RL_SW_IC_Ver_Minor 0;
BA_ "GenSigSendType" SG_ 2281701616 UWB_RL_SW_IC_Ver_Minor 4;
BA_ "Version" SG_ 2281701616 UWB_RL_DTC "23.01.02";
BA_ "UserSigValidity" SG_ 2281701616 UWB_RL_DTC 0;
BA_ "GenSigSendType" SG_ 2281701616 UWB_RL_DTC 4;
BA_ "Version" SG_ 2281701616 L_UWB_RL_FD_AlvCnt10Val "23.01.02";
BA_ "UserSigValidity" SG_ 2281701616 L_UWB_RL_FD_AlvCnt10Val 3;
BA_ "GenSigSendType" SG_ 2281701616 L_UWB_RL_FD_AlvCnt10Val 4;
BA_ "Description" SG_ 2281701616 L_UWB_RL_FD_AlvCnt10Val "For the first transmission request for a data element the counter shall be initialized with 0 and shall be incremented by 1 for every subsequent send request. 

When the counter reaches the maximum value(0xFF), then it shall restart with 0 for the next s";
BA_ "Version" SG_ 2281701616 UWB_RL_Status1 "24.04.04";
BA_ "UserSigValidity" SG_ 2281701616 UWB_RL_Status1 0;
BA_ "GenSigSendType" SG_ 2281701616 UWB_RL_Status1 4;
BA_ "Description" SG_ 2281701616 UWB_RL_Status1 "UWB_RL Processing Status 1";
BA_ "Version" SG_ 2281701616 UWB_RL_Status2 "24.04.04";
BA_ "UserSigValidity" SG_ 2281701616 UWB_RL_Status2 0;
BA_ "GenSigSendType" SG_ 2281701616 UWB_RL_Status2 4;
BA_ "Description" SG_ 2281701616 UWB_RL_Status2 "UWB_RL Processing Status 2";
BA_ "Version" SG_ 2281701616 UWB_RL_Status3 "24.04.04";
BA_ "UserSigValidity" SG_ 2281701616 UWB_RL_Status3 0;
BA_ "GenSigSendType" SG_ 2281701616 UWB_RL_Status3 4;
BA_ "Description" SG_ 2281701616 UWB_RL_Status3 "UWB_RL Processing Status 3";
BA_ "Version" SG_ 2281701616 UWB_RL_Status4 "24.04.04";
BA_ "UserSigValidity" SG_ 2281701616 UWB_RL_Status4 0;
BA_ "GenSigSendType" SG_ 2281701616 UWB_RL_Status4 4;
BA_ "Description" SG_ 2281701616 UWB_RL_Status4 "UWB_RL Processing Status 4";
BA_ "Version" SG_ 2281701616 UWB_RL_Status5 "24.04.04";
BA_ "UserSigValidity" SG_ 2281701616 UWB_RL_Status5 0;
BA_ "GenSigSendType" SG_ 2281701616 UWB_RL_Status5 4;
BA_ "Description" SG_ 2281701616 UWB_RL_Status5 "UWB_RL Processing Status 5";
BA_ "Version" SG_ 2281701616 UWB_RL_Status6 "24.04.04";
BA_ "UserSigValidity" SG_ 2281701616 UWB_RL_Status6 0;
BA_ "GenSigSendType" SG_ 2281701616 UWB_RL_Status6 4;
BA_ "Description" SG_ 2281701616 UWB_RL_Status6 "UWB_RL Processing Status 6";
BA_ "Version" SG_ 2281701616 UWB_RL_Status7 "24.04.04";
BA_ "UserSigValidity" SG_ 2281701616 UWB_RL_Status7 0;
BA_ "GenSigSendType" SG_ 2281701616 UWB_RL_Status7 4;
BA_ "Description" SG_ 2281701616 UWB_RL_Status7 "UWB_RL Processing Status 7";
BA_ "Version" SG_ 2281701616 UWB_RL_Status8 "24.04.04";
BA_ "UserSigValidity" SG_ 2281701616 UWB_RL_Status8 0;
BA_ "GenSigSendType" SG_ 2281701616 UWB_RL_Status8 4;
BA_ "Description" SG_ 2281701616 UWB_RL_Status8 "UWB_RL Processing Status 8";
BA_ "Version" SG_ 2281701616 UWB_RL_Status9 "24.04.04";
BA_ "UserSigValidity" SG_ 2281701616 UWB_RL_Status9 0;
BA_ "GenSigSendType" SG_ 2281701616 UWB_RL_Status9 4;
BA_ "Description" SG_ 2281701616 UWB_RL_Status9 "UWB_RL Processing Status 9";
BA_ "Version" SG_ 2281701616 UWB_RL_Status10 "24.04.04";
BA_ "UserSigValidity" SG_ 2281701616 UWB_RL_Status10 0;
BA_ "GenSigSendType" SG_ 2281701616 UWB_RL_Status10 4;
BA_ "Description" SG_ 2281701616 UWB_RL_Status10 "UWB_RL Processing Status 10";
BA_ "Version" SG_ 2281701616 UWB_RL_Status11 "24.04.04";
BA_ "UserSigValidity" SG_ 2281701616 UWB_RL_Status11 0;
BA_ "GenSigSendType" SG_ 2281701616 UWB_RL_Status11 4;
BA_ "Description" SG_ 2281701616 UWB_RL_Status11 "UWB_RL Processing Status 11";
BA_ "Version" SG_ 2281701616 UWB_RL_Status12 "24.04.04";
BA_ "UserSigValidity" SG_ 2281701616 UWB_RL_Status12 0;
BA_ "GenSigSendType" SG_ 2281701616 UWB_RL_Status12 4;
BA_ "Description" SG_ 2281701616 UWB_RL_Status12 "UWB_RL Processing Status 12";
BA_ "Version" SG_ 2281701616 UWB_RL_Status13 "24.04.04";
BA_ "UserSigValidity" SG_ 2281701616 UWB_RL_Status13 0;
BA_ "GenSigSendType" SG_ 2281701616 UWB_RL_Status13 4;
BA_ "Description" SG_ 2281701616 UWB_RL_Status13 "UWB_RL Processing Status 13";
BA_ "Version" SG_ 2281701616 UWB_RL_Status14 "24.04.04";
BA_ "UserSigValidity" SG_ 2281701616 UWB_RL_Status14 0;
BA_ "GenSigSendType" SG_ 2281701616 UWB_RL_Status14 4;
BA_ "Description" SG_ 2281701616 UWB_RL_Status14 "UWB_RL Processing Status 14";
BA_ "Version" SG_ 2281701616 UWB_RL_Status15 "24.04.04";
BA_ "UserSigValidity" SG_ 2281701616 UWB_RL_Status15 0;
BA_ "GenSigSendType" SG_ 2281701616 UWB_RL_Status15 4;
BA_ "Description" SG_ 2281701616 UWB_RL_Status15 "UWB_RL Processing Status 15";
BA_ "Version" SG_ 2281701616 UWB_RL_Status16 "24.04.04";
BA_ "UserSigValidity" SG_ 2281701616 UWB_RL_Status16 0;
BA_ "GenSigSendType" SG_ 2281701616 UWB_RL_Status16 4;
BA_ "Description" SG_ 2281701616 UWB_RL_Status16 "UWB_RL Processing Status 16";
BA_ "Version" SG_ 2281701616 UWB_RL_HW_Ver_Major "23.01.02";
BA_ "UserSigValidity" SG_ 2281701616 UWB_RL_HW_Ver_Major 0;
BA_ "GenSigSendType" SG_ 2281701616 UWB_RL_HW_Ver_Major 4;
BA_ "Version" SG_ 2281701616 UWB_RL_HW_Ver_Minor "23.01.02";
BA_ "UserSigValidity" SG_ 2281701616 UWB_RL_HW_Ver_Minor 0;
BA_ "GenSigSendType" SG_ 2281701616 UWB_RL_HW_Ver_Minor 4;
BA_ "Version" SG_ 979 BDC_FD_Crc4Val "22.11.04";
BA_ "UserSigValidity" SG_ 979 BDC_FD_Crc4Val 0;
BA_ "GenSigStartValue" SG_ 979 BDC_FD_Crc4Val 65535;
BA_ "GenSigSendType" SG_ 979 BDC_FD_Crc4Val 4;
BA_ "Description" SG_ 979 BDC_FD_Crc4Val "The data area for CRC calculation is based on the data length (DLC) of the message DB.

The CRC shall be calculated over the entire data block (excluding the CRC bytes) including the user data, alive counter and Data ID



- CRC Polynomial (0x1021) , Ini";
BA_ "Version" SG_ 979 BDC_FD_AlvCnt4Val "22.11.04";
BA_ "UserSigValidity" SG_ 979 BDC_FD_AlvCnt4Val 0;
BA_ "GenSigSendType" SG_ 979 BDC_FD_AlvCnt4Val 4;
BA_ "Description" SG_ 979 BDC_FD_AlvCnt4Val "For the first transmission request for a data element the counter shall be initialized with 0 and shall be incremented by 1 for every subsequent send request. 

When the counter reaches the maximum value(0xFF), then it shall restart with 0 for the next s";
BA_ "Version" SG_ 979 BAlarm_BglrAlrm_CurrentSta "22.11.02";
BA_ "NetworkRequestHoldingTime" SG_ 979 BAlarm_BglrAlrm_CurrentSta 5000;
BA_ "NetworkRequest" SG_ 979 BAlarm_BglrAlrm_CurrentSta 0;
BA_ "UserSigValidity" SG_ 979 BAlarm_BglrAlrm_CurrentSta 0;
BA_ "GenSigSendType" SG_ 979 BAlarm_BglrAlrm_CurrentSta 4;
BA_ "Version" SG_ 979 BAlarm_BglrAlrm_Sta "22.11.02";
BA_ "NetworkRequestHoldingTime" SG_ 979 BAlarm_BglrAlrm_Sta 5000;
BA_ "NetworkRequest" SG_ 979 BAlarm_BglrAlrm_Sta 0;
BA_ "UserSigValidity" SG_ 979 BAlarm_BglrAlrm_Sta 0;
BA_ "GenSigSendType" SG_ 979 BAlarm_BglrAlrm_Sta 4;
BA_ "Version" SG_ 979 BAlarm_PncAlrmSta_Copy_0 "21.09.05";
BA_ "NetworkRequestHoldingTime" SG_ 979 BAlarm_PncAlrmSta_Copy_0 5000;
BA_ "NetworkRequest" SG_ 979 BAlarm_PncAlrmSta_Copy_0 0;
BA_ "UserSigValidity" SG_ 979 BAlarm_PncAlrmSta_Copy_0 0;
BA_ "GenSigSendType" SG_ 979 BAlarm_PncAlrmSta_Copy_0 4;
BA_ "Description" SG_ 979 BAlarm_PncAlrmSta_Copy_0 "-For TeleCranking Panic Function

-This signal send to IBOX";
BA_ "Version" SG_ 979 SBR_StBltStpWrngBzrSta_Copy_0 "18.07.03";
BA_ "NetworkRequestHoldingTime" SG_ 979 SBR_StBltStpWrngBzrSta_Copy_0 5000;
BA_ "NetworkRequest" SG_ 979 SBR_StBltStpWrngBzrSta_Copy_0 0;
BA_ "UserSigValidity" SG_ 979 SBR_StBltStpWrngBzrSta_Copy_0 0;
BA_ "GenSigSendType" SG_ 979 SBR_StBltStpWrngBzrSta_Copy_0 4;
BA_ "Description" SG_ 979 SBR_StBltStpWrngBzrSta_Copy_0 "This signal is used for control the Seatbelt Step Warning Buzzer function with 3 bits.

It provides pre-warning, 1st warning, 2nd warning and 3rd warning.";
BA_ "Version" SG_ 979 SBR_StBltWrngBzrSta_Copy_0 "17.12.00";
BA_ "NetworkRequestHoldingTime" SG_ 979 SBR_StBltWrngBzrSta_Copy_0 5000;
BA_ "NetworkRequest" SG_ 979 SBR_StBltWrngBzrSta_Copy_0 0;
BA_ "UserSigValidity" SG_ 979 SBR_StBltWrngBzrSta_Copy_0 0;
BA_ "GenSigSendType" SG_ 979 SBR_StBltWrngBzrSta_Copy_0 4;
BA_ "Description" SG_ 979 SBR_StBltWrngBzrSta_Copy_0 "-Seat belt Warning (Reminder) buzzer";
BA_ "Version" SG_ 979 BAlarm_BrglrHrnRlySta_Copy_0 "17.12.00";
BA_ "NetworkRequestHoldingTime" SG_ 979 BAlarm_BrglrHrnRlySta_Copy_0 5000;
BA_ "NetworkRequest" SG_ 979 BAlarm_BrglrHrnRlySta_Copy_0 0;
BA_ "UserSigValidity" SG_ 979 BAlarm_BrglrHrnRlySta_Copy_0 0;
BA_ "GenSigSendType" SG_ 979 BAlarm_BrglrHrnRlySta_Copy_0 4;
BA_ "Version" SG_ 979 SBR_DrvStBltIndSta_Copy_0 "17.12.00";
BA_ "NetworkRequestHoldingTime" SG_ 979 SBR_DrvStBltIndSta_Copy_0 5000;
BA_ "NetworkRequest" SG_ 979 SBR_DrvStBltIndSta_Copy_0 0;
BA_ "UserSigValidity" SG_ 979 SBR_DrvStBltIndSta_Copy_0 0;
BA_ "GenSigSendType" SG_ 979 SBR_DrvStBltIndSta_Copy_0 4;
BA_ "Version" SG_ 979 SBR_RrLftStBltWrngIndSta_Copy_0 "18.06.01";
BA_ "NetworkRequestHoldingTime" SG_ 979 SBR_RrLftStBltWrngIndSta_Copy_0 5000;
BA_ "NetworkRequest" SG_ 979 SBR_RrLftStBltWrngIndSta_Copy_0 0;
BA_ "UserSigValidity" SG_ 979 SBR_RrLftStBltWrngIndSta_Copy_0 0;
BA_ "GenSigSendType" SG_ 979 SBR_RrLftStBltWrngIndSta_Copy_0 4;
BA_ "Version" SG_ 979 SBR_RrRtStBltWrngIndSta_Copy_0 "18.06.01";
BA_ "NetworkRequestHoldingTime" SG_ 979 SBR_RrRtStBltWrngIndSta_Copy_0 5000;
BA_ "NetworkRequest" SG_ 979 SBR_RrRtStBltWrngIndSta_Copy_0 0;
BA_ "UserSigValidity" SG_ 979 SBR_RrRtStBltWrngIndSta_Copy_0 0;
BA_ "GenSigSendType" SG_ 979 SBR_RrRtStBltWrngIndSta_Copy_0 4;
BA_ "Version" SG_ 979 SBR_RrCtrStBltIndSta_Copy_0 "20.01.01";
BA_ "NetworkRequestHoldingTime" SG_ 979 SBR_RrCtrStBltIndSta_Copy_0 5000;
BA_ "NetworkRequest" SG_ 979 SBR_RrCtrStBltIndSta_Copy_0 0;
BA_ "UserSigValidity" SG_ 979 SBR_RrCtrStBltIndSta_Copy_0 0;
BA_ "GenSigSendType" SG_ 979 SBR_RrCtrStBltIndSta_Copy_0 4;
BA_ "Version" SG_ 979 SBR_3rdLftStBltWrngIndSta_Copy_0 "18.06.01";
BA_ "NetworkRequestHoldingTime" SG_ 979 SBR_3rdLftStBltWrngIndSta_Copy_0 5000;
BA_ "NetworkRequest" SG_ 979 SBR_3rdLftStBltWrngIndSta_Copy_0 0;
BA_ "UserSigValidity" SG_ 979 SBR_3rdLftStBltWrngIndSta_Copy_0 0;
BA_ "GenSigSendType" SG_ 979 SBR_3rdLftStBltWrngIndSta_Copy_0 4;
BA_ "Description" SG_ 979 SBR_3rdLftStBltWrngIndSta_Copy_0 "This signal is used for control the 3th Row Left Seatbelt indicator function.";
BA_ "Version" SG_ 979 SBR_3rdRtStBltWrngIndSta_Copy_0 "18.06.01";
BA_ "NetworkRequestHoldingTime" SG_ 979 SBR_3rdRtStBltWrngIndSta_Copy_0 5000;
BA_ "NetworkRequest" SG_ 979 SBR_3rdRtStBltWrngIndSta_Copy_0 0;
BA_ "UserSigValidity" SG_ 979 SBR_3rdRtStBltWrngIndSta_Copy_0 0;
BA_ "GenSigSendType" SG_ 979 SBR_3rdRtStBltWrngIndSta_Copy_0 4;
BA_ "Description" SG_ 979 SBR_3rdRtStBltWrngIndSta_Copy_0 "This signal is used for control the 3th Row Right Seatbelt indicator function.";
BA_ "Version" SG_ 979 SBR_3rdCtrStBltWrngIndSta_Copy_0 "20.01.01";
BA_ "NetworkRequestHoldingTime" SG_ 979 SBR_3rdCtrStBltWrngIndSta_Copy_0 5000;
BA_ "NetworkRequest" SG_ 979 SBR_3rdCtrStBltWrngIndSta_Copy_0 0;
BA_ "UserSigValidity" SG_ 979 SBR_3rdCtrStBltWrngIndSta_Copy_0 0;
BA_ "GenSigSendType" SG_ 979 SBR_3rdCtrStBltWrngIndSta_Copy_0 4;
BA_ "Description" SG_ 979 SBR_3rdCtrStBltWrngIndSta_Copy_0 "This signal is used for control the 3th Row Center Seatbelt indicator function.";
BA_ "Version" SG_ 979 Warn_BzrWrngSta_Copy_0 "17.12.00";
BA_ "NetworkRequestHoldingTime" SG_ 979 Warn_BzrWrngSta_Copy_0 5000;
BA_ "NetworkRequest" SG_ 979 Warn_BzrWrngSta_Copy_0 0;
BA_ "UserSigValidity" SG_ 979 Warn_BzrWrngSta_Copy_0 0;
BA_ "GenSigSendType" SG_ 979 Warn_BzrWrngSta_Copy_0 4;
BA_ "Description" SG_ 979 Warn_BzrWrngSta_Copy_0 "-(Old)C_WngBuzzer";
BA_ "Version" SG_ 979 Warn_BCMWrngSta_Copy_0 "23.04.04";
BA_ "NetworkRequestHoldingTime" SG_ 979 Warn_BCMWrngSta_Copy_0 5000;
BA_ "NetworkRequest" SG_ 979 Warn_BCMWrngSta_Copy_0 0;
BA_ "UserSigValidity" SG_ 979 Warn_BCMWrngSta_Copy_0 0;
BA_ "GenSigSendType" SG_ 979 Warn_BCMWrngSta_Copy_0 4;
BA_ "Description" SG_ 979 Warn_BCMWrngSta_Copy_0 "Warning command og BCM";
BA_ "Version" SG_ 979 ROA_RrBlwAutoOffReq_Copy_0 "21.04.00";
BA_ "NetworkRequestHoldingTime" SG_ 979 ROA_RrBlwAutoOffReq_Copy_0 5000;
BA_ "NetworkRequest" SG_ 979 ROA_RrBlwAutoOffReq_Copy_0 0;
BA_ "UserSigValidity" SG_ 979 ROA_RrBlwAutoOffReq_Copy_0 0;
BA_ "GenSigSendType" SG_ 979 ROA_RrBlwAutoOffReq_Copy_0 4;
BA_ "Description" SG_ 979 ROA_RrBlwAutoOffReq_Copy_0 "This signal is used for a request to Rear Blow Off (Auto Cut)";
BA_ "Version" SG_ 979 ROA_RegionOpt_Copy_0 "21.11.07";
BA_ "NetworkRequestHoldingTime" SG_ 979 ROA_RegionOpt_Copy_0 5000;
BA_ "NetworkRequest" SG_ 979 ROA_RegionOpt_Copy_0 0;
BA_ "UserSigValidity" SG_ 979 ROA_RegionOpt_Copy_0 0;
BA_ "GenSigSendType" SG_ 979 ROA_RegionOpt_Copy_0 4;
BA_ "Description" SG_ 979 ROA_RegionOpt_Copy_0 "A Euro NCAP Option signal (BDC only)";
BA_ "Version" SG_ 979 Warn_RrStRmndOpt_Copy_0 "21.04.00";
BA_ "NetworkRequestHoldingTime" SG_ 979 Warn_RrStRmndOpt_Copy_0 5000;
BA_ "NetworkRequest" SG_ 979 Warn_RrStRmndOpt_Copy_0 0;
BA_ "UserSigValidity" SG_ 979 Warn_RrStRmndOpt_Copy_0 0;
BA_ "GenSigSendType" SG_ 979 Warn_RrStRmndOpt_Copy_0 4;
BA_ "Description" SG_ 979 Warn_RrStRmndOpt_Copy_0 "Rear Seat Reminder System Appled Option

(BDC Only Use 0x0 and 0x2 in Signal Value Table)";
BA_ "Version" SG_ 979 Warn_RrStRmndAlrmOnReq_Copy_0 "17.12.00";
BA_ "NetworkRequestHoldingTime" SG_ 979 Warn_RrStRmndAlrmOnReq_Copy_0 5000;
BA_ "NetworkRequest" SG_ 979 Warn_RrStRmndAlrmOnReq_Copy_0 0;
BA_ "UserSigValidity" SG_ 979 Warn_RrStRmndAlrmOnReq_Copy_0 0;
BA_ "GenSigSendType" SG_ 979 Warn_RrStRmndAlrmOnReq_Copy_0 4;
BA_ "Description" SG_ 979 Warn_RrStRmndAlrmOnReq_Copy_0 "Rear Seat Reminder Alarm State";
BA_ "Version" SG_ 979 Warn_RrStRmndSysSta_Copy_0 "17.12.00";
BA_ "NetworkRequestHoldingTime" SG_ 979 Warn_RrStRmndSysSta_Copy_0 5000;
BA_ "NetworkRequest" SG_ 979 Warn_RrStRmndSysSta_Copy_0 0;
BA_ "UserSigValidity" SG_ 979 Warn_RrStRmndSysSta_Copy_0 0;
BA_ "GenSigSendType" SG_ 979 Warn_RrStRmndSysSta_Copy_0 4;
BA_ "Description" SG_ 979 Warn_RrStRmndSysSta_Copy_0 "Rear Seat Reminder Alarm System Enable(On)/Disable(Off) state";
BA_ "Version" SG_ 979 Warn_RrStRmndAlrmInfo_Copy_0 "24.03.06";
BA_ "NetworkRequestHoldingTime" SG_ 979 Warn_RrStRmndAlrmInfo_Copy_0 5000;
BA_ "NetworkRequest" SG_ 979 Warn_RrStRmndAlrmInfo_Copy_0 0;
BA_ "UserSigValidity" SG_ 979 Warn_RrStRmndAlrmInfo_Copy_0 0;
BA_ "GenSigSendType" SG_ 979 Warn_RrStRmndAlrmInfo_Copy_0 4;
BA_ "Description" SG_ 979 Warn_RrStRmndAlrmInfo_Copy_0 "Rear Seat Reminder Warning request signal";
BA_ "Version" SG_ 979 Warn_RoaErr_Copy_0 "18.07.01";
BA_ "NetworkRequestHoldingTime" SG_ 979 Warn_RoaErr_Copy_0 5000;
BA_ "NetworkRequest" SG_ 979 Warn_RoaErr_Copy_0 0;
BA_ "UserSigValidity" SG_ 979 Warn_RoaErr_Copy_0 0;
BA_ "GenSigSendType" SG_ 979 Warn_RoaErr_Copy_0 4;
BA_ "Description" SG_ 979 Warn_RoaErr_Copy_0 "ROA SENSOR Error(Malfunction)  signal";
BA_ "Version" SG_ 979 Warn_RrStRmndDelay_Copy_0 "22.03.04";
BA_ "NetworkRequestHoldingTime" SG_ 979 Warn_RrStRmndDelay_Copy_0 5000;
BA_ "NetworkRequest" SG_ 979 Warn_RrStRmndDelay_Copy_0 0;
BA_ "UserSigValidity" SG_ 979 Warn_RrStRmndDelay_Copy_0 0;
BA_ "TimeoutValue" SG_ 979 Warn_RrStRmndDelay_Copy_0 "0x0";
BA_ "GenSigSendType" SG_ 979 Warn_RrStRmndDelay_Copy_0 4;
BA_ "Version" SG_ 979 Warn_RrStRmndSysAct_Copy_0 "22.03.04";
BA_ "NetworkRequestHoldingTime" SG_ 979 Warn_RrStRmndSysAct_Copy_0 5000;
BA_ "NetworkRequest" SG_ 979 Warn_RrStRmndSysAct_Copy_0 0;
BA_ "UserSigValidity" SG_ 979 Warn_RrStRmndSysAct_Copy_0 0;
BA_ "TimeoutValue" SG_ 979 Warn_RrStRmndSysAct_Copy_0 "0x0";
BA_ "GenSigSendType" SG_ 979 Warn_RrStRmndSysAct_Copy_0 4;
BA_ "Version" SG_ 979 WAL_FobSearching_Copy_0 "19.06.00";
BA_ "NetworkRequestHoldingTime" SG_ 979 WAL_FobSearching_Copy_0 5000;
BA_ "NetworkRequest" SG_ 979 WAL_FobSearching_Copy_0 0;
BA_ "UserSigValidity" SG_ 979 WAL_FobSearching_Copy_0 0;
BA_ "GenSigSendType" SG_ 979 WAL_FobSearching_Copy_0 4;
BA_ "Description" SG_ 979 WAL_FobSearching_Copy_0 "IBU Walk Away Lock Fob Searching State for Radar ROA

(LIN_IBU_WAL_FobSearching for UIP ROA)";
BA_ "Version" SG_ 979 Warn_RrStRmndSysOffIND_Copy_0 "22.08.01";
BA_ "NetworkRequestHoldingTime" SG_ 979 Warn_RrStRmndSysOffIND_Copy_0 5000;
BA_ "NetworkRequest" SG_ 979 Warn_RrStRmndSysOffIND_Copy_0 0;
BA_ "UserSigValidity" SG_ 979 Warn_RrStRmndSysOffIND_Copy_0 0;
BA_ "TimeoutValue" SG_ 979 Warn_RrStRmndSysOffIND_Copy_0 "0x0";
BA_ "GenSigSendType" SG_ 979 Warn_RrStRmndSysOffIND_Copy_0 4;
BA_ "Version" SG_ 979 Warn_VehNotPWrngSta_Copy_0 "23.05.01";
BA_ "NetworkRequestHoldingTime" SG_ 979 Warn_VehNotPWrngSta_Copy_0 5000;
BA_ "NetworkRequest" SG_ 979 Warn_VehNotPWrngSta_Copy_0 0;
BA_ "UserSigValidity" SG_ 979 Warn_VehNotPWrngSta_Copy_0 0;
BA_ "GenSigSendType" SG_ 979 Warn_VehNotPWrngSta_Copy_0 4;
BA_ "Description" SG_ 979 Warn_VehNotPWrngSta_Copy_0 "Vehicle Not P Warning";
BA_ "Version" SG_ 979 Warn_RrStRmndAlrmInfo_1_Copy_0 "24.04.06";
BA_ "NetworkRequestHoldingTime" SG_ 979 Warn_RrStRmndAlrmInfo_1_Copy_0 5000;
BA_ "NetworkRequest" SG_ 979 Warn_RrStRmndAlrmInfo_1_Copy_0 0;
BA_ "UserSigValidity" SG_ 979 Warn_RrStRmndAlrmInfo_1_Copy_0 0;
BA_ "GenSigSendType" SG_ 979 Warn_RrStRmndAlrmInfo_1_Copy_0 4;
BA_ "Description" SG_ 979 Warn_RrStRmndAlrmInfo_1_Copy_0 "Rear Seat Reminder Warning request signal";
BA_ "Version" SG_ 2533736961 L_UWB_TRNK_FD_Crc6Val "24.07.05";
BA_ "RoutingFactor" SG_ 2533736961 L_UWB_TRNK_FD_Crc6Val 0;
BA_ "UserSigValidity" SG_ 2533736961 L_UWB_TRNK_FD_Crc6Val 3;
BA_ "GenSigStartValue" SG_ 2533736961 L_UWB_TRNK_FD_Crc6Val 65535;
BA_ "GenSigSendType" SG_ 2533736961 L_UWB_TRNK_FD_Crc6Val 2;
BA_ "Description" SG_ 2533736961 L_UWB_TRNK_FD_Crc6Val "The data area for CRC calculation is based on the data length (DLC) of the message DB.

The CRC shall be calculated over the entire data block (excluding the CRC bytes) including the user data, alive counter and Data ID



- CRC Polynomial (0x1021) , Ini";
BA_ "Version" SG_ 2533736961 L_UWB_TRNK_FD_AlvCnt6Val "24.07.05";
BA_ "RoutingFactor" SG_ 2533736961 L_UWB_TRNK_FD_AlvCnt6Val 0;
BA_ "UserSigValidity" SG_ 2533736961 L_UWB_TRNK_FD_AlvCnt6Val 3;
BA_ "GenSigSendType" SG_ 2533736961 L_UWB_TRNK_FD_AlvCnt6Val 2;
BA_ "Description" SG_ 2533736961 L_UWB_TRNK_FD_AlvCnt6Val "For the first transmission request for a data element the counter shall be initialized with 0 and shall be incremented by 1 for every subsequent send request. 

When the counter reaches the maximum value(0xFF), then it shall restart with 0 for the next s";
BA_ "Version" SG_ 2533736961 TRNK_SWID_4_IVD_1 "24.07.05";
BA_ "RoutingFactor" SG_ 2533736961 TRNK_SWID_4_IVD_1 0;
BA_ "UserSigValidity" SG_ 2533736961 TRNK_SWID_4_IVD_1 0;
BA_ "GenSigSendType" SG_ 2533736961 TRNK_SWID_4_IVD_1 2;
BA_ "Version" SG_ 1467 DHRL_GST_Byte0 "22.07.01";
BA_ "NetworkRequestHoldingTime" SG_ 1467 DHRL_GST_Byte0 5000;
BA_ "NetworkRequest" SG_ 1467 DHRL_GST_Byte0 0;
BA_ "UserSigValidity" SG_ 1467 DHRL_GST_Byte0 0;
BA_ "UsrSigPurpose" SG_ 1467 DHRL_GST_Byte0 4;
BA_ "Description" SG_ 1467 DHRL_GST_Byte0 "TP Index : 213";
BA_ "Version" SG_ 1467 DHRL_GST_Byte2 "22.07.01";
BA_ "NetworkRequestHoldingTime" SG_ 1467 DHRL_GST_Byte2 5000;
BA_ "NetworkRequest" SG_ 1467 DHRL_GST_Byte2 0;
BA_ "UserSigValidity" SG_ 1467 DHRL_GST_Byte2 0;
BA_ "UsrSigPurpose" SG_ 1467 DHRL_GST_Byte2 4;
BA_ "Description" SG_ 1467 DHRL_GST_Byte2 "TP Index : 213";
BA_ "Version" SG_ 1467 DHRL_GST_Byte3 "22.07.01";
BA_ "NetworkRequestHoldingTime" SG_ 1467 DHRL_GST_Byte3 5000;
BA_ "NetworkRequest" SG_ 1467 DHRL_GST_Byte3 0;
BA_ "UserSigValidity" SG_ 1467 DHRL_GST_Byte3 0;
BA_ "UsrSigPurpose" SG_ 1467 DHRL_GST_Byte3 4;
BA_ "Description" SG_ 1467 DHRL_GST_Byte3 "TP Index : 213";
BA_ "Version" SG_ 1467 DHRL_GST_Byte4 "22.07.01";
BA_ "NetworkRequestHoldingTime" SG_ 1467 DHRL_GST_Byte4 5000;
BA_ "NetworkRequest" SG_ 1467 DHRL_GST_Byte4 0;
BA_ "UserSigValidity" SG_ 1467 DHRL_GST_Byte4 0;
BA_ "UsrSigPurpose" SG_ 1467 DHRL_GST_Byte4 4;
BA_ "Description" SG_ 1467 DHRL_GST_Byte4 "TP Index : 213";
BA_ "Version" SG_ 1467 DHRL_GST_Byte5 "22.07.01";
BA_ "NetworkRequestHoldingTime" SG_ 1467 DHRL_GST_Byte5 5000;
BA_ "NetworkRequest" SG_ 1467 DHRL_GST_Byte5 0;
BA_ "UserSigValidity" SG_ 1467 DHRL_GST_Byte5 0;
BA_ "UsrSigPurpose" SG_ 1467 DHRL_GST_Byte5 4;
BA_ "Description" SG_ 1467 DHRL_GST_Byte5 "TP Index : 213";
BA_ "Version" SG_ 1467 DHRL_GST_Byte6 "22.07.01";
BA_ "NetworkRequestHoldingTime" SG_ 1467 DHRL_GST_Byte6 5000;
BA_ "NetworkRequest" SG_ 1467 DHRL_GST_Byte6 0;
BA_ "UserSigValidity" SG_ 1467 DHRL_GST_Byte6 0;
BA_ "UsrSigPurpose" SG_ 1467 DHRL_GST_Byte6 4;
BA_ "Description" SG_ 1467 DHRL_GST_Byte6 "TP Index : 213";
BA_ "Version" SG_ 1467 DHRL_GST_Byte7 "22.07.01";
BA_ "NetworkRequestHoldingTime" SG_ 1467 DHRL_GST_Byte7 5000;
BA_ "NetworkRequest" SG_ 1467 DHRL_GST_Byte7 0;
BA_ "UserSigValidity" SG_ 1467 DHRL_GST_Byte7 0;
BA_ "UsrSigPurpose" SG_ 1467 DHRL_GST_Byte7 4;
BA_ "Description" SG_ 1467 DHRL_GST_Byte7 "TP Index : 213";
BA_ "Version" SG_ 1467 DHRL_GST_Byte1 "22.07.01";
BA_ "NetworkRequestHoldingTime" SG_ 1467 DHRL_GST_Byte1 5000;
BA_ "NetworkRequest" SG_ 1467 DHRL_GST_Byte1 0;
BA_ "UserSigValidity" SG_ 1467 DHRL_GST_Byte1 0;
BA_ "UsrSigPurpose" SG_ 1467 DHRL_GST_Byte1 4;
BA_ "Description" SG_ 1467 DHRL_GST_Byte1 "TP Index : 213";
BA_ "Version" SG_ 977 BDC_FD_Crc2Val "22.11.04";
BA_ "UserSigValidity" SG_ 977 BDC_FD_Crc2Val 0;
BA_ "GenSigStartValue" SG_ 977 BDC_FD_Crc2Val 65535;
BA_ "GenSigSendType" SG_ 977 BDC_FD_Crc2Val 4;
BA_ "Description" SG_ 977 BDC_FD_Crc2Val "The data area for CRC calculation is based on the data length (DLC) of the message DB.

The CRC shall be calculated over the entire data block (excluding the CRC bytes) including the user data, alive counter and Data ID



- CRC Polynomial (0x1021) , Ini";
BA_ "Version" SG_ 977 BDC_FD_AlvCnt2Val "22.11.04";
BA_ "UserSigValidity" SG_ 977 BDC_FD_AlvCnt2Val 0;
BA_ "GenSigSendType" SG_ 977 BDC_FD_AlvCnt2Val 4;
BA_ "Description" SG_ 977 BDC_FD_AlvCnt2Val "For the first transmission request for a data element the counter shall be initialized with 0 and shall be incremented by 1 for every subsequent send request. 

When the counter reaches the maximum value(0xFF), then it shall restart with 0 for the next s";
BA_ "Version" SG_ 977 BCM_KeyInSta_Copy_0 "17.12.00";
BA_ "NetworkRequestHoldingTime" SG_ 977 BCM_KeyInSta_Copy_0 5000;
BA_ "NetworkRequest" SG_ 977 BCM_KeyInSta_Copy_0 0;
BA_ "UserSigValidity" SG_ 977 BCM_KeyInSta_Copy_0 0;
BA_ "GenSigSendType" SG_ 977 BCM_KeyInSta_Copy_0 4;
BA_ "Description" SG_ 977 BCM_KeyInSta_Copy_0 "Mechanical Key In SW State (If SMK option is On, C_KeyInSw always have  Off

 value)";
BA_ "Version" SG_ 977 BCM_AccInSta_Copy_0 "21.09.05";
BA_ "NetworkRequestHoldingTime" SG_ 977 BCM_AccInSta_Copy_0 5000;
BA_ "NetworkRequest" SG_ 977 BCM_AccInSta_Copy_0 0;
BA_ "UserSigValidity" SG_ 977 BCM_AccInSta_Copy_0 0;
BA_ "GenSigSendType" SG_ 977 BCM_AccInSta_Copy_0 4;
BA_ "Version" SG_ 977 BCM_Ign1InSta_Copy_0 "21.09.05";
BA_ "NetworkRequestHoldingTime" SG_ 977 BCM_Ign1InSta_Copy_0 5000;
BA_ "NetworkRequest" SG_ 977 BCM_Ign1InSta_Copy_0 0;
BA_ "UserSigValidity" SG_ 977 BCM_Ign1InSta_Copy_0 0;
BA_ "GenSigSendType" SG_ 977 BCM_Ign1InSta_Copy_0 4;
BA_ "Version" SG_ 977 BCM_Ign2InSta_Copy_0 "21.09.05";
BA_ "NetworkRequestHoldingTime" SG_ 977 BCM_Ign2InSta_Copy_0 5000;
BA_ "NetworkRequest" SG_ 977 BCM_Ign2InSta_Copy_0 0;
BA_ "UserSigValidity" SG_ 977 BCM_Ign2InSta_Copy_0 0;
BA_ "GenSigSendType" SG_ 977 BCM_Ign2InSta_Copy_0 4;
BA_ "Version" SG_ 977 IBU_HDPSpprtSWVer_Copy_0 "21.10.04";
BA_ "NetworkRequestHoldingTime" SG_ 977 IBU_HDPSpprtSWVer_Copy_0 5000;
BA_ "NetworkRequest" SG_ 977 IBU_HDPSpprtSWVer_Copy_0 0;
BA_ "UserSigValidity" SG_ 977 IBU_HDPSpprtSWVer_Copy_0 0;
BA_ "GenSigSendType" SG_ 977 IBU_HDPSpprtSWVer_Copy_0 4;
BA_ "Description" SG_ 977 IBU_HDPSpprtSWVer_Copy_0 "This signal indicates HDP-IBU requirement version";
BA_ "Version" SG_ 977 IBU_HDPSpprtRdy_Copy_0 "22.03.02";
BA_ "NetworkRequestHoldingTime" SG_ 977 IBU_HDPSpprtRdy_Copy_0 5000;
BA_ "NetworkRequest" SG_ 977 IBU_HDPSpprtRdy_Copy_0 0;
BA_ "UserSigValidity" SG_ 977 IBU_HDPSpprtRdy_Copy_0 0;
BA_ "GenSigSendType" SG_ 977 IBU_HDPSpprtRdy_Copy_0 4;
BA_ "Description" SG_ 977 IBU_HDPSpprtRdy_Copy_0 "ADAS Message (received) Error State";
BA_ "Version" SG_ 977 BCM_GearPosPSta_Copy_0 "21.09.05";
BA_ "NetworkRequestHoldingTime" SG_ 977 BCM_GearPosPSta_Copy_0 5000;
BA_ "NetworkRequest" SG_ 977 BCM_GearPosPSta_Copy_0 0;
BA_ "UserSigValidity" SG_ 977 BCM_GearPosPSta_Copy_0 0;
BA_ "GenSigSendType" SG_ 977 BCM_GearPosPSta_Copy_0 4;
BA_ "Description" SG_ 977 BCM_GearPosPSta_Copy_0 "This signal is valid only when connected to Key Interlock SW or P Position SW as a circuit";
BA_ "Version" SG_ 977 BCM_SmkOptTyp_Copy_0 "17.12.00";
BA_ "NetworkRequestHoldingTime" SG_ 977 BCM_SmkOptTyp_Copy_0 5000;
BA_ "NetworkRequest" SG_ 977 BCM_SmkOptTyp_Copy_0 0;
BA_ "UserSigValidity" SG_ 977 BCM_SmkOptTyp_Copy_0 0;
BA_ "GenSigSendType" SG_ 977 BCM_SmkOptTyp_Copy_0 4;
BA_ "Description" SG_ 977 BCM_SmkOptTyp_Copy_0 "-(Old)C_PICOption";
BA_ "Version" SG_ 977 BDC_ResetOpSta_Copy_0 "24.05.05";
BA_ "UserSigValidity" SG_ 977 BDC_ResetOpSta_Copy_0 0;
BA_ "GenSigSendType" SG_ 977 BDC_ResetOpSta_Copy_0 4;
BA_ "Description" SG_ 977 BDC_ResetOpSta_Copy_0 "This signal indicates whether the reset operation has been completed or not";
BA_ "Version" SG_ 977 IBU_SWVerMajor1_Copy_0 "20.12.04";
BA_ "UserSigValidity" SG_ 977 IBU_SWVerMajor1_Copy_0 0;
BA_ "GenSigSendType" SG_ 977 IBU_SWVerMajor1_Copy_0 4;
BA_ "Description" SG_ 977 IBU_SWVerMajor1_Copy_0 "Indicate the IBU software version as follows:

- The software version is displayed in three digits.

- The Major and Minor digits are separated by '.'

- Signal values are transmitted to ASCII codes.



б╪ Example

C_IBU_SWVerMajor1 : 0x41 (HEX) -> ASCII";
BA_ "Version" SG_ 977 IBU_SWVerMinor1_Copy_0 "18.10.02";
BA_ "UserSigValidity" SG_ 977 IBU_SWVerMinor1_Copy_0 0;
BA_ "GenSigSendType" SG_ 977 IBU_SWVerMinor1_Copy_0 4;
BA_ "Description" SG_ 977 IBU_SWVerMinor1_Copy_0 "Indicate the IBU software version as follows:

- The software version is displayed in three digits.

- The Major and Minor digits are separated by '.'

- Signal values are transmitted to ASCII codes.



б╪ Example

C_IBU_SWVerMajor1 : 0x41 (HEX) -> ASCII";
BA_ "Version" SG_ 977 IBU_SWVerMinor2_Copy_0 "18.10.02";
BA_ "UserSigValidity" SG_ 977 IBU_SWVerMinor2_Copy_0 0;
BA_ "GenSigSendType" SG_ 977 IBU_SWVerMinor2_Copy_0 4;
BA_ "Description" SG_ 977 IBU_SWVerMinor2_Copy_0 "Indicate the IBU software version as follows:

- The software version is displayed in three digits.

- The Major and Minor digits are separated by '.'

- Signal values are transmitted to ASCII codes.



б╪ Example

C_IBU_SWVerMajor1 : 0x41 (HEX) -> ASCII";
BA_ "Version" SG_ 977 BDC_PlatformVerType_Copy_0 "23.04.03";
BA_ "UserSigValidity" SG_ 977 BDC_PlatformVerType_Copy_0 0;
BA_ "GenSigSendType" SG_ 977 BDC_PlatformVerType_Copy_0 4;
BA_ "Description" SG_ 977 BDC_PlatformVerType_Copy_0 "BDC Platform Type Information

- A / B / C";
BA_ "Version" SG_ 977 BDC_PlatformVerDate_Copy_0 "23.02.01";
BA_ "UserSigValidity" SG_ 977 BDC_PlatformVerDate_Copy_0 0;
BA_ "GenSigSendType" SG_ 977 BDC_PlatformVerDate_Copy_0 4;
BA_ "Description" SG_ 977 BDC_PlatformVerDate_Copy_0 "BDC Platform Version Date 

Version Information

- YYMM 

- 0x1 : 2301 / 0x2 : 2302 бж";
BA_ "Version" SG_ 2529538561 L_UWB_RL_FD_Crc6Val "24.07.05";
BA_ "RoutingFactor" SG_ 2529538561 L_UWB_RL_FD_Crc6Val 0;
BA_ "UserSigValidity" SG_ 2529538561 L_UWB_RL_FD_Crc6Val 3;
BA_ "GenSigStartValue" SG_ 2529538561 L_UWB_RL_FD_Crc6Val 65535;
BA_ "GenSigSendType" SG_ 2529538561 L_UWB_RL_FD_Crc6Val 2;
BA_ "Description" SG_ 2529538561 L_UWB_RL_FD_Crc6Val "The data area for CRC calculation is based on the data length (DLC) of the message DB.

The CRC shall be calculated over the entire data block (excluding the CRC bytes) including the user data, alive counter and Data ID



- CRC Polynomial (0x1021) , Ini";
BA_ "Version" SG_ 2529538561 L_UWB_RL_FD_AlvCnt6Val "24.07.05";
BA_ "RoutingFactor" SG_ 2529538561 L_UWB_RL_FD_AlvCnt6Val 0;
BA_ "UserSigValidity" SG_ 2529538561 L_UWB_RL_FD_AlvCnt6Val 3;
BA_ "GenSigSendType" SG_ 2529538561 L_UWB_RL_FD_AlvCnt6Val 2;
BA_ "Description" SG_ 2529538561 L_UWB_RL_FD_AlvCnt6Val "For the first transmission request for a data element the counter shall be initialized with 0 and shall be incremented by 1 for every subsequent send request. 

When the counter reaches the maximum value(0xFF), then it shall restart with 0 for the next s";
BA_ "Version" SG_ 2529538561 RL_SWID_4_IVD_1 "24.07.05";
BA_ "RoutingFactor" SG_ 2529538561 RL_SWID_4_IVD_1 0;
BA_ "UserSigValidity" SG_ 2529538561 RL_SWID_4_IVD_1 0;
BA_ "GenSigSendType" SG_ 2529538561 RL_SWID_4_IVD_1 2;
BA_ "Version" SG_ 1468 DHRR_GST_Byte0 "22.07.01";
BA_ "NetworkRequestHoldingTime" SG_ 1468 DHRR_GST_Byte0 5000;
BA_ "NetworkRequest" SG_ 1468 DHRR_GST_Byte0 0;
BA_ "UserSigValidity" SG_ 1468 DHRR_GST_Byte0 0;
BA_ "UsrSigPurpose" SG_ 1468 DHRR_GST_Byte0 4;
BA_ "Description" SG_ 1468 DHRR_GST_Byte0 "TP Index : 214";
BA_ "Version" SG_ 1468 DHRR_GST_Byte2 "22.07.01";
BA_ "NetworkRequestHoldingTime" SG_ 1468 DHRR_GST_Byte2 5000;
BA_ "NetworkRequest" SG_ 1468 DHRR_GST_Byte2 0;
BA_ "UserSigValidity" SG_ 1468 DHRR_GST_Byte2 0;
BA_ "UsrSigPurpose" SG_ 1468 DHRR_GST_Byte2 4;
BA_ "Description" SG_ 1468 DHRR_GST_Byte2 "TP Index : 214";
BA_ "Version" SG_ 1468 DHRR_GST_Byte3 "22.07.01";
BA_ "NetworkRequestHoldingTime" SG_ 1468 DHRR_GST_Byte3 5000;
BA_ "NetworkRequest" SG_ 1468 DHRR_GST_Byte3 0;
BA_ "UserSigValidity" SG_ 1468 DHRR_GST_Byte3 0;
BA_ "UsrSigPurpose" SG_ 1468 DHRR_GST_Byte3 4;
BA_ "Description" SG_ 1468 DHRR_GST_Byte3 "TP Index : 214";
BA_ "Version" SG_ 1468 DHRR_GST_Byte4 "22.07.01";
BA_ "NetworkRequestHoldingTime" SG_ 1468 DHRR_GST_Byte4 5000;
BA_ "NetworkRequest" SG_ 1468 DHRR_GST_Byte4 0;
BA_ "UserSigValidity" SG_ 1468 DHRR_GST_Byte4 0;
BA_ "UsrSigPurpose" SG_ 1468 DHRR_GST_Byte4 4;
BA_ "Description" SG_ 1468 DHRR_GST_Byte4 "TP Index : 214";
BA_ "Version" SG_ 1468 DHRR_GST_Byte5 "22.07.01";
BA_ "NetworkRequestHoldingTime" SG_ 1468 DHRR_GST_Byte5 5000;
BA_ "NetworkRequest" SG_ 1468 DHRR_GST_Byte5 0;
BA_ "UserSigValidity" SG_ 1468 DHRR_GST_Byte5 0;
BA_ "UsrSigPurpose" SG_ 1468 DHRR_GST_Byte5 4;
BA_ "Description" SG_ 1468 DHRR_GST_Byte5 "TP Index : 214";
BA_ "Version" SG_ 1468 DHRR_GST_Byte6 "22.07.01";
BA_ "NetworkRequestHoldingTime" SG_ 1468 DHRR_GST_Byte6 5000;
BA_ "NetworkRequest" SG_ 1468 DHRR_GST_Byte6 0;
BA_ "UserSigValidity" SG_ 1468 DHRR_GST_Byte6 0;
BA_ "UsrSigPurpose" SG_ 1468 DHRR_GST_Byte6 4;
BA_ "Description" SG_ 1468 DHRR_GST_Byte6 "TP Index : 214";
BA_ "Version" SG_ 1468 DHRR_GST_Byte7 "22.07.01";
BA_ "NetworkRequestHoldingTime" SG_ 1468 DHRR_GST_Byte7 5000;
BA_ "NetworkRequest" SG_ 1468 DHRR_GST_Byte7 0;
BA_ "UserSigValidity" SG_ 1468 DHRR_GST_Byte7 0;
BA_ "UsrSigPurpose" SG_ 1468 DHRR_GST_Byte7 4;
BA_ "Description" SG_ 1468 DHRR_GST_Byte7 "TP Index : 214";
BA_ "Version" SG_ 1468 DHRR_GST_Byte1 "22.07.01";
BA_ "NetworkRequestHoldingTime" SG_ 1468 DHRR_GST_Byte1 5000;
BA_ "NetworkRequest" SG_ 1468 DHRR_GST_Byte1 0;
BA_ "UserSigValidity" SG_ 1468 DHRR_GST_Byte1 0;
BA_ "UsrSigPurpose" SG_ 1468 DHRR_GST_Byte1 4;
BA_ "Description" SG_ 1468 DHRR_GST_Byte1 "TP Index : 214";
BA_REL_ "GenSigTimeoutTime" BU_SG_REL_ L_UWB_BLE_MST_FD SG_ 994 Warn_DrvDrSwSta_Copy_0 1500;
BA_REL_ "GenSigTimeoutTime" BU_SG_REL_ L_UWB_BLE_MST_FD SG_ 994 Warn_AsstDrSwSta_Copy_0 1500;
BA_REL_ "GenSigTimeoutTime" BU_SG_REL_ L_UWB_BLE_MST_FD SG_ 994 Warn_RrLftDrSwSta_Copy_0 1500;
BA_REL_ "GenSigTimeoutTime" BU_SG_REL_ L_UWB_BLE_MST_FD SG_ 994 Warn_RrRtDrSwSta_Copy_0 1500;
BA_REL_ "GenSigTimeoutTime" BU_SG_REL_ L_UWB_BLE_MST_FD SG_ 994 Warn_HoodSwSta_Copy_0 1500;
BA_REL_ "GenSigTimeoutTime" BU_SG_REL_ L_UWB_BLE_MST_FD SG_ 994 DoorLock_DrvDrUnLkSta_Copy_0 1500;
BA_REL_ "GenSigTimeoutTime" BU_SG_REL_ L_UWB_BLE_MST_FD SG_ 994 DoorLock_AsstDrUnLkSta_Copy_0 1500;
BA_REL_ "GenSigTimeoutTime" BU_SG_REL_ L_UWB_BLE_MST_FD SG_ 994 DoorLock_RrLftDrUnLkSta_Copy_0 1500;
BA_REL_ "GenSigTimeoutTime" BU_SG_REL_ L_UWB_BLE_MST_FD SG_ 994 DoorLock_RrRtDrUnLkSta_Copy_0 1500;
BA_REL_ "GenSigTimeoutTime" BU_SG_REL_ L_SAL_FD SG_ 2348810241 L_BDC_FD_Crc1Val 1500;
BA_REL_ "GenSigTimeoutTime" BU_SG_REL_ L_SAL_FD SG_ 2348810241 MoodLamp_BottomBlueVal 1500;
BA_REL_ "GenSigTimeoutTime" BU_SG_REL_ L_SAL_FD SG_ 2348810241 MoodLamp_AIVoiceMicLevel 1500;
BA_REL_ "GenSigTimeoutTime" BU_SG_REL_ L_SAL_FD SG_ 2348810241 MoodLamp_AIVoiceTTSLevel 1500;
BA_REL_ "GenSigTimeoutTime" BU_SG_REL_ L_SAL_FD SG_ 2348810241 MoodLamp_VehicleSpeed 1500;
BA_REL_ "GenSigTimeoutTime" BU_SG_REL_ L_SAL_FD SG_ 2348810241 MoodLamp_MLBrghtModCmd_6bit 1500;
BA_REL_ "GenSigTimeoutTime" BU_SG_REL_ L_SAL_FD SG_ 2348810241 MoodLamp_MLColorModCmd_6bit 1500;
BA_REL_ "GenSigTimeoutTime" BU_SG_REL_ L_SAL_FD SG_ 2348810241 MoodLamp_DrvTempChgModCmd 1500;
BA_REL_ "GenSigTimeoutTime" BU_SG_REL_ L_SAL_FD SG_ 2348810241 MoodLamp_AstTempChgModCmd 1500;
BA_REL_ "GenSigTimeoutTime" BU_SG_REL_ L_SAL_FD SG_ 2348810241 MoodLamp_PhoneCallModCmd 1500;
BA_REL_ "GenSigTimeoutTime" BU_SG_REL_ L_SAL_FD SG_ 2348810241 MoodLamp_AIVoiceRecogPosSta 1500;
BA_REL_ "GenSigTimeoutTime" BU_SG_REL_ L_SAL_FD SG_ 2348810241 MoodLamp_FLDoorWarnModCmd 1500;
BA_REL_ "GenSigTimeoutTime" BU_SG_REL_ L_SAL_FD SG_ 2348810241 L_BDC_FD_AlvCnt1Val 1500;
BA_REL_ "GenSigTimeoutTime" BU_SG_REL_ L_SAL_FD SG_ 2348810241 MoodLamp_FRDoorWarnModCmd 1500;
BA_REL_ "GenSigTimeoutTime" BU_SG_REL_ L_SAL_FD SG_ 2348810241 MoodLamp_RLDoorWarnModCmd 1500;
BA_REL_ "GenSigTimeoutTime" BU_SG_REL_ L_SAL_FD SG_ 2348810241 MoodLamp_RRDoorWarnModCmd 1500;
BA_REL_ "GenSigTimeoutTime" BU_SG_REL_ L_SAL_FD SG_ 2348810241 MoodLamp_HazardModCmd 1500;
BA_REL_ "GenSigTimeoutTime" BU_SG_REL_ L_SAL_FD SG_ 2348810241 MoodLamp_FLDoorObstacleModCmd 1500;
BA_REL_ "GenSigTimeoutTime" BU_SG_REL_ L_SAL_FD SG_ 2348810241 MoodLamp_FRDoorObstacleModCmd 1500;
BA_REL_ "GenSigTimeoutTime" BU_SG_REL_ L_SAL_FD SG_ 2348810241 MoodLamp_RLDoorObstacleModCmd 1500;
BA_REL_ "GenSigTimeoutTime" BU_SG_REL_ L_SAL_FD SG_ 2348810241 MoodLamp_RRDoorObstacleModCmd 1500;
BA_REL_ "GenSigTimeoutTime" BU_SG_REL_ L_SAL_FD SG_ 2348810241 MoodLamp_LowFuelWarnModCmd 1500;
BA_REL_ "GenSigTimeoutTime" BU_SG_REL_ L_SAL_FD SG_ 2348810241 MoodLamp_NShiftModCmd 1500;
BA_REL_ "GenSigTimeoutTime" BU_SG_REL_ L_SAL_FD SG_ 2348810241 MoodLamp_MLBrghtModCmd 1500;
BA_REL_ "GenSigTimeoutTime" BU_SG_REL_ L_SAL_FD SG_ 2348810241 MoodLamp_MLColorModCmd 1500;
BA_REL_ "GenSigTimeoutTime" BU_SG_REL_ L_SAL_FD SG_ 2348810241 MoodLamp_WelcomeAndGoodbyeSeqMod 1500;
BA_REL_ "GenSigTimeoutTime" BU_SG_REL_ L_SAL_FD SG_ 2348810241 MoodLamp_AIVoiceSeqModCmd 1500;
BA_REL_ "GenSigTimeoutTime" BU_SG_REL_ L_SAL_FD SG_ 2348810241 MoodLamp_EngineRunningSeqModCmd 1500;
BA_REL_ "GenSigTimeoutTime" BU_SG_REL_ L_SAL_FD SG_ 2348810241 MoodLamp_OverSpeedSeqModCmd 1500;
BA_REL_ "GenSigTimeoutTime" BU_SG_REL_ L_SAL_FD SG_ 2348810241 MoodLamp_DriveSeqModCmd 1500;
BA_REL_ "GenSigTimeoutTime" BU_SG_REL_ L_SAL_FD SG_ 2348810241 MoodLamp_AirCleaningSeqModCmd 1500;
BA_REL_ "GenSigTimeoutTime" BU_SG_REL_ L_SAL_FD SG_ 2348810241 MoodLamp_FootLampModCmd 1500;
BA_REL_ "GenSigTimeoutTime" BU_SG_REL_ L_SAL_FD SG_ 2348810241 MoodLamp_SunroofModCmd 1500;
BA_REL_ "GenSigTimeoutTime" BU_SG_REL_ L_SAL_FD SG_ 2348810241 MoodLamp_BrghtVal 1500;
BA_REL_ "GenSigTimeoutTime" BU_SG_REL_ L_SAL_FD SG_ 2348810241 MoodLamp_RedVal 1500;
BA_REL_ "GenSigTimeoutTime" BU_SG_REL_ L_SAL_FD SG_ 2348810241 MoodLamp_GreenVal 1500;
BA_REL_ "GenSigTimeoutTime" BU_SG_REL_ L_SAL_FD SG_ 2348810241 MoodLamp_BlueVal 1500;
BA_REL_ "GenSigTimeoutTime" BU_SG_REL_ L_SAL_FD SG_ 2348810241 MoodLamp_BottomRedVal 1500;
BA_REL_ "GenSigTimeoutTime" BU_SG_REL_ L_SAL_FD SG_ 2348810241 MoodLamp_BottomGreenVal 1500;
BA_REL_ "GenSigTimeoutTime" BU_SG_REL_ L_TPMS_FD SG_ 996 ICU_PowerAutoCutModSta_Copy_0 1500;
BA_REL_ "GenSigTimeoutTime" BU_SG_REL_ L_DHL_FD SG_ 2549874800 SNI_CGW_CCU 1500;
BA_REL_ "GenSigTimeoutTime" BU_SG_REL_ L_DHRL_FD SG_ 2549874800 SNI_CGW_CCU 1500;
BA_REL_ "GenSigTimeoutTime" BU_SG_REL_ L_DHRR_FD SG_ 2549874800 SNI_CGW_CCU 1500;
BA_REL_ "GenSigTimeoutTime" BU_SG_REL_ L_DHR_FD SG_ 2549874800 SNI_CGW_CCU 1500;
BA_REL_ "GenSigTimeoutTime" BU_SG_REL_ L_SAL_FD SG_ 2549874800 SNI_CGW_CCU 1500;
BA_REL_ "GenSigTimeoutTime" BU_SG_REL_ L_TPMS_FD SG_ 2549874800 SNI_CGW_CCU 1500;
BA_REL_ "GenSigTimeoutTime" BU_SG_REL_ L_UWB_BLE_MST_FD SG_ 2549874800 SNI_CGW_CCU 1500;
BA_REL_ "GenSigTimeoutTime" BU_SG_REL_ L_UWB_BLE_SLV_FD SG_ 2549874800 SNI_CGW_CCU 1500;
BA_REL_ "GenSigTimeoutTime" BU_SG_REL_ L_UWB_FL_FD SG_ 2549874800 SNI_CGW_CCU 1500;
BA_REL_ "GenSigTimeoutTime" BU_SG_REL_ L_UWB_FRNK_FD SG_ 2549874800 SNI_CGW_CCU 1500;
BA_REL_ "GenSigTimeoutTime" BU_SG_REL_ L_UWB_FR_FD SG_ 2549874800 SNI_CGW_CCU 1500;
BA_REL_ "GenSigTimeoutTime" BU_SG_REL_ L_UWB_RL_FD SG_ 2549874800 SNI_CGW_CCU 1500;
BA_REL_ "GenSigTimeoutTime" BU_SG_REL_ L_UWB_RR_FD SG_ 2549874800 SNI_CGW_CCU 1500;
BA_REL_ "GenSigTimeoutTime" BU_SG_REL_ L_UWB_TRNK_FD SG_ 2549874800 SNI_CGW_CCU 1500;
BA_REL_ "GenSigTimeoutTime" BU_SG_REL_ L_WPC_FD SG_ 2549874800 SNI_CGW_CCU 1500;
BA_REL_ "GenSigTimeoutTime" BU_SG_REL_ L_DHL_FD SG_ 2549874800 CBV_NMCoSRB_CGW_CCU 1500;
BA_REL_ "GenSigTimeoutTime" BU_SG_REL_ L_DHRL_FD SG_ 2549874800 CBV_NMCoSRB_CGW_CCU 1500;
BA_REL_ "GenSigTimeoutTime" BU_SG_REL_ L_DHRR_FD SG_ 2549874800 CBV_NMCoSRB_CGW_CCU 1500;
BA_REL_ "GenSigTimeoutTime" BU_SG_REL_ L_DHR_FD SG_ 2549874800 CBV_NMCoSRB_CGW_CCU 1500;
BA_REL_ "GenSigTimeoutTime" BU_SG_REL_ L_SAL_FD SG_ 2549874800 CBV_NMCoSRB_CGW_CCU 1500;
BA_REL_ "GenSigTimeoutTime" BU_SG_REL_ L_TPMS_FD SG_ 2549874800 CBV_NMCoSRB_CGW_CCU 1500;
BA_REL_ "GenSigTimeoutTime" BU_SG_REL_ L_UWB_BLE_MST_FD SG_ 2549874800 CBV_NMCoSRB_CGW_CCU 1500;
BA_REL_ "GenSigTimeoutTime" BU_SG_REL_ L_UWB_BLE_SLV_FD SG_ 2549874800 CBV_NMCoSRB_CGW_CCU 1500;
BA_REL_ "GenSigTimeoutTime" BU_SG_REL_ L_UWB_FL_FD SG_ 2549874800 CBV_NMCoSRB_CGW_CCU 1500;
BA_REL_ "GenSigTimeoutTime" BU_SG_REL_ L_UWB_FRNK_FD SG_ 2549874800 CBV_NMCoSRB_CGW_CCU 1500;
BA_REL_ "GenSigTimeoutTime" BU_SG_REL_ L_UWB_FR_FD SG_ 2549874800 CBV_NMCoSRB_CGW_CCU 1500;
BA_REL_ "GenSigTimeoutTime" BU_SG_REL_ L_UWB_RL_FD SG_ 2549874800 CBV_NMCoSRB_CGW_CCU 1500;
BA_REL_ "GenSigTimeoutTime" BU_SG_REL_ L_UWB_RR_FD SG_ 2549874800 CBV_NMCoSRB_CGW_CCU 1500;
BA_REL_ "GenSigTimeoutTime" BU_SG_REL_ L_UWB_TRNK_FD SG_ 2549874800 CBV_NMCoSRB_CGW_CCU 1500;
BA_REL_ "GenSigTimeoutTime" BU_SG_REL_ L_WPC_FD SG_ 2549874800 CBV_NMCoSRB_CGW_CCU 1500;
BA_REL_ "GenSigTimeoutTime" BU_SG_REL_ L_DHL_FD SG_ 2549874800 CBV_AWB_CGW_CCU 1500;
BA_REL_ "GenSigTimeoutTime" BU_SG_REL_ L_DHRL_FD SG_ 2549874800 CBV_AWB_CGW_CCU 1500;
BA_REL_ "GenSigTimeoutTime" BU_SG_REL_ L_DHRR_FD SG_ 2549874800 CBV_AWB_CGW_CCU 1500;
BA_REL_ "GenSigTimeoutTime" BU_SG_REL_ L_DHR_FD SG_ 2549874800 CBV_AWB_CGW_CCU 1500;
BA_REL_ "GenSigTimeoutTime" BU_SG_REL_ L_SAL_FD SG_ 2549874800 CBV_AWB_CGW_CCU 1500;
BA_REL_ "GenSigTimeoutTime" BU_SG_REL_ L_TPMS_FD SG_ 2549874800 CBV_AWB_CGW_CCU 1500;
BA_REL_ "GenSigTimeoutTime" BU_SG_REL_ L_UWB_BLE_MST_FD SG_ 2549874800 CBV_AWB_CGW_CCU 1500;
BA_REL_ "GenSigTimeoutTime" BU_SG_REL_ L_UWB_BLE_SLV_FD SG_ 2549874800 CBV_AWB_CGW_CCU 1500;
BA_REL_ "GenSigTimeoutTime" BU_SG_REL_ L_UWB_FL_FD SG_ 2549874800 CBV_AWB_CGW_CCU 1500;
BA_REL_ "GenSigTimeoutTime" BU_SG_REL_ L_UWB_FRNK_FD SG_ 2549874800 CBV_AWB_CGW_CCU 1500;
BA_REL_ "GenSigTimeoutTime" BU_SG_REL_ L_UWB_FR_FD SG_ 2549874800 CBV_AWB_CGW_CCU 1500;
BA_REL_ "GenSigTimeoutTime" BU_SG_REL_ L_UWB_RL_FD SG_ 2549874800 CBV_AWB_CGW_CCU 1500;
BA_REL_ "GenSigTimeoutTime" BU_SG_REL_ L_UWB_RR_FD SG_ 2549874800 CBV_AWB_CGW_CCU 1500;
BA_REL_ "GenSigTimeoutTime" BU_SG_REL_ L_UWB_TRNK_FD SG_ 2549874800 CBV_AWB_CGW_CCU 1500;
BA_REL_ "GenSigTimeoutTime" BU_SG_REL_ L_WPC_FD SG_ 2549874800 CBV_AWB_CGW_CCU 1500;
BA_REL_ "GenSigTimeoutTime" BU_SG_REL_ L_DHL_FD SG_ 2549874800 PNI_CGW_CCU_2 1500;
BA_REL_ "GenSigTimeoutTime" BU_SG_REL_ L_DHRL_FD SG_ 2549874800 PNI_CGW_CCU_2 1500;
BA_REL_ "GenSigTimeoutTime" BU_SG_REL_ L_DHRR_FD SG_ 2549874800 PNI_CGW_CCU_2 1500;
BA_REL_ "GenSigTimeoutTime" BU_SG_REL_ L_DHR_FD SG_ 2549874800 PNI_CGW_CCU_2 1500;
BA_REL_ "GenSigTimeoutTime" BU_SG_REL_ L_SAL_FD SG_ 2549874800 PNI_CGW_CCU_2 1500;
BA_REL_ "GenSigTimeoutTime" BU_SG_REL_ L_TPMS_FD SG_ 2549874800 PNI_CGW_CCU_2 1500;
BA_REL_ "GenSigTimeoutTime" BU_SG_REL_ L_UWB_BLE_MST_FD SG_ 2549874800 PNI_CGW_CCU_2 1500;
BA_REL_ "GenSigTimeoutTime" BU_SG_REL_ L_UWB_BLE_SLV_FD SG_ 2549874800 PNI_CGW_CCU_2 1500;
BA_REL_ "GenSigTimeoutTime" BU_SG_REL_ L_UWB_FL_FD SG_ 2549874800 PNI_CGW_CCU_2 1500;
BA_REL_ "GenSigTimeoutTime" BU_SG_REL_ L_UWB_FRNK_FD SG_ 2549874800 PNI_CGW_CCU_2 1500;
BA_REL_ "GenSigTimeoutTime" BU_SG_REL_ L_UWB_FR_FD SG_ 2549874800 PNI_CGW_CCU_2 1500;
BA_REL_ "GenSigTimeoutTime" BU_SG_REL_ L_UWB_RL_FD SG_ 2549874800 PNI_CGW_CCU_2 1500;
BA_REL_ "GenSigTimeoutTime" BU_SG_REL_ L_UWB_RR_FD SG_ 2549874800 PNI_CGW_CCU_2 1500;
BA_REL_ "GenSigTimeoutTime" BU_SG_REL_ L_UWB_TRNK_FD SG_ 2549874800 PNI_CGW_CCU_2 1500;
BA_REL_ "GenSigTimeoutTime" BU_SG_REL_ L_WPC_FD SG_ 2549874800 PNI_CGW_CCU_2 1500;
BA_REL_ "GenSigTimeoutTime" BU_SG_REL_ L_DHL_FD SG_ 2549874800 CBV_PNIB_CGW_CCU 1500;
BA_REL_ "GenSigTimeoutTime" BU_SG_REL_ L_DHRL_FD SG_ 2549874800 CBV_PNIB_CGW_CCU 1500;
BA_REL_ "GenSigTimeoutTime" BU_SG_REL_ L_DHRR_FD SG_ 2549874800 CBV_PNIB_CGW_CCU 1500;
BA_REL_ "GenSigTimeoutTime" BU_SG_REL_ L_DHR_FD SG_ 2549874800 CBV_PNIB_CGW_CCU 1500;
BA_REL_ "GenSigTimeoutTime" BU_SG_REL_ L_SAL_FD SG_ 2549874800 CBV_PNIB_CGW_CCU 1500;
BA_REL_ "GenSigTimeoutTime" BU_SG_REL_ L_TPMS_FD SG_ 2549874800 CBV_PNIB_CGW_CCU 1500;
BA_REL_ "GenSigTimeoutTime" BU_SG_REL_ L_UWB_BLE_MST_FD SG_ 2549874800 CBV_PNIB_CGW_CCU 1500;
BA_REL_ "GenSigTimeoutTime" BU_SG_REL_ L_UWB_BLE_SLV_FD SG_ 2549874800 CBV_PNIB_CGW_CCU 1500;
BA_REL_ "GenSigTimeoutTime" BU_SG_REL_ L_UWB_FL_FD SG_ 2549874800 CBV_PNIB_CGW_CCU 1500;
BA_REL_ "GenSigTimeoutTime" BU_SG_REL_ L_UWB_FRNK_FD SG_ 2549874800 CBV_PNIB_CGW_CCU 1500;
BA_REL_ "GenSigTimeoutTime" BU_SG_REL_ L_UWB_FR_FD SG_ 2549874800 CBV_PNIB_CGW_CCU 1500;
BA_REL_ "GenSigTimeoutTime" BU_SG_REL_ L_UWB_RL_FD SG_ 2549874800 CBV_PNIB_CGW_CCU 1500;
BA_REL_ "GenSigTimeoutTime" BU_SG_REL_ L_UWB_RR_FD SG_ 2549874800 CBV_PNIB_CGW_CCU 1500;
BA_REL_ "GenSigTimeoutTime" BU_SG_REL_ L_UWB_TRNK_FD SG_ 2549874800 CBV_PNIB_CGW_CCU 1500;
BA_REL_ "GenSigTimeoutTime" BU_SG_REL_ L_WPC_FD SG_ 2549874800 CBV_PNIB_CGW_CCU 1500;
BA_REL_ "GenSigTimeoutTime" BU_SG_REL_ L_DHL_FD SG_ 2549874800 NRR_CGW_CCU 1500;
BA_REL_ "GenSigTimeoutTime" BU_SG_REL_ L_DHRL_FD SG_ 2549874800 NRR_CGW_CCU 1500;
BA_REL_ "GenSigTimeoutTime" BU_SG_REL_ L_DHRR_FD SG_ 2549874800 NRR_CGW_CCU 1500;
BA_REL_ "GenSigTimeoutTime" BU_SG_REL_ L_DHR_FD SG_ 2549874800 NRR_CGW_CCU 1500;
BA_REL_ "GenSigTimeoutTime" BU_SG_REL_ L_SAL_FD SG_ 2549874800 NRR_CGW_CCU 1500;
BA_REL_ "GenSigTimeoutTime" BU_SG_REL_ L_TPMS_FD SG_ 2549874800 NRR_CGW_CCU 1500;
BA_REL_ "GenSigTimeoutTime" BU_SG_REL_ L_UWB_BLE_MST_FD SG_ 2549874800 NRR_CGW_CCU 1500;
BA_REL_ "GenSigTimeoutTime" BU_SG_REL_ L_UWB_BLE_SLV_FD SG_ 2549874800 NRR_CGW_CCU 1500;
BA_REL_ "GenSigTimeoutTime" BU_SG_REL_ L_UWB_FL_FD SG_ 2549874800 NRR_CGW_CCU 1500;
BA_REL_ "GenSigTimeoutTime" BU_SG_REL_ L_UWB_FRNK_FD SG_ 2549874800 NRR_CGW_CCU 1500;
BA_REL_ "GenSigTimeoutTime" BU_SG_REL_ L_UWB_FR_FD SG_ 2549874800 NRR_CGW_CCU 1500;
BA_REL_ "GenSigTimeoutTime" BU_SG_REL_ L_UWB_RL_FD SG_ 2549874800 NRR_CGW_CCU 1500;
BA_REL_ "GenSigTimeoutTime" BU_SG_REL_ L_UWB_RR_FD SG_ 2549874800 NRR_CGW_CCU 1500;
BA_REL_ "GenSigTimeoutTime" BU_SG_REL_ L_UWB_TRNK_FD SG_ 2549874800 NRR_CGW_CCU 1500;
BA_REL_ "GenSigTimeoutTime" BU_SG_REL_ L_WPC_FD SG_ 2549874800 NRR_CGW_CCU 1500;
BA_REL_ "GenSigTimeoutTime" BU_SG_REL_ L_DHL_FD SG_ 2549874800 PNI_CGW_CCU_3 1500;
BA_REL_ "GenSigTimeoutTime" BU_SG_REL_ L_DHRL_FD SG_ 2549874800 PNI_CGW_CCU_3 1500;
BA_REL_ "GenSigTimeoutTime" BU_SG_REL_ L_DHRR_FD SG_ 2549874800 PNI_CGW_CCU_3 1500;
BA_REL_ "GenSigTimeoutTime" BU_SG_REL_ L_DHR_FD SG_ 2549874800 PNI_CGW_CCU_3 1500;
BA_REL_ "GenSigTimeoutTime" BU_SG_REL_ L_SAL_FD SG_ 2549874800 PNI_CGW_CCU_3 1500;
BA_REL_ "GenSigTimeoutTime" BU_SG_REL_ L_TPMS_FD SG_ 2549874800 PNI_CGW_CCU_3 1500;
BA_REL_ "GenSigTimeoutTime" BU_SG_REL_ L_UWB_BLE_MST_FD SG_ 2549874800 PNI_CGW_CCU_3 1500;
BA_REL_ "GenSigTimeoutTime" BU_SG_REL_ L_UWB_BLE_SLV_FD SG_ 2549874800 PNI_CGW_CCU_3 1500;
BA_REL_ "GenSigTimeoutTime" BU_SG_REL_ L_UWB_FL_FD SG_ 2549874800 PNI_CGW_CCU_3 1500;
BA_REL_ "GenSigTimeoutTime" BU_SG_REL_ L_UWB_FRNK_FD SG_ 2549874800 PNI_CGW_CCU_3 1500;
BA_REL_ "GenSigTimeoutTime" BU_SG_REL_ L_UWB_FR_FD SG_ 2549874800 PNI_CGW_CCU_3 1500;
BA_REL_ "GenSigTimeoutTime" BU_SG_REL_ L_UWB_RL_FD SG_ 2549874800 PNI_CGW_CCU_3 1500;
BA_REL_ "GenSigTimeoutTime" BU_SG_REL_ L_UWB_RR_FD SG_ 2549874800 PNI_CGW_CCU_3 1500;
BA_REL_ "GenSigTimeoutTime" BU_SG_REL_ L_UWB_TRNK_FD SG_ 2549874800 PNI_CGW_CCU_3 1500;
BA_REL_ "GenSigTimeoutTime" BU_SG_REL_ L_WPC_FD SG_ 2549874800 PNI_CGW_CCU_3 1500;
BA_REL_ "GenSigTimeoutTime" BU_SG_REL_ L_DHL_FD SG_ 2549874800 NM_State_CGW_CCU 1500;
BA_REL_ "GenSigTimeoutTime" BU_SG_REL_ L_DHRL_FD SG_ 2549874800 NM_State_CGW_CCU 1500;
BA_REL_ "GenSigTimeoutTime" BU_SG_REL_ L_DHRR_FD SG_ 2549874800 NM_State_CGW_CCU 1500;
BA_REL_ "GenSigTimeoutTime" BU_SG_REL_ L_DHR_FD SG_ 2549874800 NM_State_CGW_CCU 1500;
BA_REL_ "GenSigTimeoutTime" BU_SG_REL_ L_SAL_FD SG_ 2549874800 NM_State_CGW_CCU 1500;
BA_REL_ "GenSigTimeoutTime" BU_SG_REL_ L_TPMS_FD SG_ 2549874800 NM_State_CGW_CCU 1500;
BA_REL_ "GenSigTimeoutTime" BU_SG_REL_ L_UWB_BLE_MST_FD SG_ 2549874800 NM_State_CGW_CCU 1500;
BA_REL_ "GenSigTimeoutTime" BU_SG_REL_ L_UWB_BLE_SLV_FD SG_ 2549874800 NM_State_CGW_CCU 1500;
BA_REL_ "GenSigTimeoutTime" BU_SG_REL_ L_UWB_FL_FD SG_ 2549874800 NM_State_CGW_CCU 1500;
BA_REL_ "GenSigTimeoutTime" BU_SG_REL_ L_UWB_FRNK_FD SG_ 2549874800 NM_State_CGW_CCU 1500;
BA_REL_ "GenSigTimeoutTime" BU_SG_REL_ L_UWB_FR_FD SG_ 2549874800 NM_State_CGW_CCU 1500;
BA_REL_ "GenSigTimeoutTime" BU_SG_REL_ L_UWB_RL_FD SG_ 2549874800 NM_State_CGW_CCU 1500;
BA_REL_ "GenSigTimeoutTime" BU_SG_REL_ L_UWB_RR_FD SG_ 2549874800 NM_State_CGW_CCU 1500;
BA_REL_ "GenSigTimeoutTime" BU_SG_REL_ L_UWB_TRNK_FD SG_ 2549874800 NM_State_CGW_CCU 1500;
BA_REL_ "GenSigTimeoutTime" BU_SG_REL_ L_WPC_FD SG_ 2549874800 NM_State_CGW_CCU 1500;
BA_REL_ "GenSigTimeoutTime" BU_SG_REL_ L_DHL_FD SG_ 2549874800 PNI_CGW_CCU 1500;
BA_REL_ "GenSigTimeoutTime" BU_SG_REL_ L_DHRL_FD SG_ 2549874800 PNI_CGW_CCU 1500;
BA_REL_ "GenSigTimeoutTime" BU_SG_REL_ L_DHRR_FD SG_ 2549874800 PNI_CGW_CCU 1500;
BA_REL_ "GenSigTimeoutTime" BU_SG_REL_ L_DHR_FD SG_ 2549874800 PNI_CGW_CCU 1500;
BA_REL_ "GenSigTimeoutTime" BU_SG_REL_ L_SAL_FD SG_ 2549874800 PNI_CGW_CCU 1500;
BA_REL_ "GenSigTimeoutTime" BU_SG_REL_ L_TPMS_FD SG_ 2549874800 PNI_CGW_CCU 1500;
BA_REL_ "GenSigTimeoutTime" BU_SG_REL_ L_UWB_BLE_MST_FD SG_ 2549874800 PNI_CGW_CCU 1500;
BA_REL_ "GenSigTimeoutTime" BU_SG_REL_ L_UWB_BLE_SLV_FD SG_ 2549874800 PNI_CGW_CCU 1500;
BA_REL_ "GenSigTimeoutTime" BU_SG_REL_ L_UWB_FL_FD SG_ 2549874800 PNI_CGW_CCU 1500;
BA_REL_ "GenSigTimeoutTime" BU_SG_REL_ L_UWB_FRNK_FD SG_ 2549874800 PNI_CGW_CCU 1500;
BA_REL_ "GenSigTimeoutTime" BU_SG_REL_ L_UWB_FR_FD SG_ 2549874800 PNI_CGW_CCU 1500;
BA_REL_ "GenSigTimeoutTime" BU_SG_REL_ L_UWB_RL_FD SG_ 2549874800 PNI_CGW_CCU 1500;
BA_REL_ "GenSigTimeoutTime" BU_SG_REL_ L_UWB_RR_FD SG_ 2549874800 PNI_CGW_CCU 1500;
BA_REL_ "GenSigTimeoutTime" BU_SG_REL_ L_UWB_TRNK_FD SG_ 2549874800 PNI_CGW_CCU 1500;
BA_REL_ "GenSigTimeoutTime" BU_SG_REL_ L_WPC_FD SG_ 2549874800 PNI_CGW_CCU 1500;
BA_REL_ "GenSigTimeoutTime" BU_SG_REL_ L_DHL_FD SG_ 2549874800 PNI_CGW_CCU_1 1500;
BA_REL_ "GenSigTimeoutTime" BU_SG_REL_ L_DHRL_FD SG_ 2549874800 PNI_CGW_CCU_1 1500;
BA_REL_ "GenSigTimeoutTime" BU_SG_REL_ L_DHRR_FD SG_ 2549874800 PNI_CGW_CCU_1 1500;
BA_REL_ "GenSigTimeoutTime" BU_SG_REL_ L_DHR_FD SG_ 2549874800 PNI_CGW_CCU_1 1500;
BA_REL_ "GenSigTimeoutTime" BU_SG_REL_ L_SAL_FD SG_ 2549874800 PNI_CGW_CCU_1 1500;
BA_REL_ "GenSigTimeoutTime" BU_SG_REL_ L_TPMS_FD SG_ 2549874800 PNI_CGW_CCU_1 1500;
BA_REL_ "GenSigTimeoutTime" BU_SG_REL_ L_UWB_BLE_MST_FD SG_ 2549874800 PNI_CGW_CCU_1 1500;
BA_REL_ "GenSigTimeoutTime" BU_SG_REL_ L_UWB_BLE_SLV_FD SG_ 2549874800 PNI_CGW_CCU_1 1500;
BA_REL_ "GenSigTimeoutTime" BU_SG_REL_ L_UWB_FL_FD SG_ 2549874800 PNI_CGW_CCU_1 1500;
BA_REL_ "GenSigTimeoutTime" BU_SG_REL_ L_UWB_FRNK_FD SG_ 2549874800 PNI_CGW_CCU_1 1500;
BA_REL_ "GenSigTimeoutTime" BU_SG_REL_ L_UWB_FR_FD SG_ 2549874800 PNI_CGW_CCU_1 1500;
BA_REL_ "GenSigTimeoutTime" BU_SG_REL_ L_UWB_RL_FD SG_ 2549874800 PNI_CGW_CCU_1 1500;
BA_REL_ "GenSigTimeoutTime" BU_SG_REL_ L_UWB_RR_FD SG_ 2549874800 PNI_CGW_CCU_1 1500;
BA_REL_ "GenSigTimeoutTime" BU_SG_REL_ L_UWB_TRNK_FD SG_ 2549874800 PNI_CGW_CCU_1 1500;
BA_REL_ "GenSigTimeoutTime" BU_SG_REL_ L_WPC_FD SG_ 2549874800 PNI_CGW_CCU_1 1500;
BA_REL_ "GenSigTimeoutTime" BU_SG_REL_ L_DHL_FD SG_ 2549874800 CBV_RMR_CGW_CCU 1500;
BA_REL_ "GenSigTimeoutTime" BU_SG_REL_ L_DHRL_FD SG_ 2549874800 CBV_RMR_CGW_CCU 1500;
BA_REL_ "GenSigTimeoutTime" BU_SG_REL_ L_DHRR_FD SG_ 2549874800 CBV_RMR_CGW_CCU 1500;
BA_REL_ "GenSigTimeoutTime" BU_SG_REL_ L_DHR_FD SG_ 2549874800 CBV_RMR_CGW_CCU 1500;
BA_REL_ "GenSigTimeoutTime" BU_SG_REL_ L_SAL_FD SG_ 2549874800 CBV_RMR_CGW_CCU 1500;
BA_REL_ "GenSigTimeoutTime" BU_SG_REL_ L_TPMS_FD SG_ 2549874800 CBV_RMR_CGW_CCU 1500;
BA_REL_ "GenSigTimeoutTime" BU_SG_REL_ L_UWB_BLE_MST_FD SG_ 2549874800 CBV_RMR_CGW_CCU 1500;
BA_REL_ "GenSigTimeoutTime" BU_SG_REL_ L_UWB_BLE_SLV_FD SG_ 2549874800 CBV_RMR_CGW_CCU 1500;
BA_REL_ "GenSigTimeoutTime" BU_SG_REL_ L_UWB_FL_FD SG_ 2549874800 CBV_RMR_CGW_CCU 1500;
BA_REL_ "GenSigTimeoutTime" BU_SG_REL_ L_UWB_FRNK_FD SG_ 2549874800 CBV_RMR_CGW_CCU 1500;
BA_REL_ "GenSigTimeoutTime" BU_SG_REL_ L_UWB_FR_FD SG_ 2549874800 CBV_RMR_CGW_CCU 1500;
BA_REL_ "GenSigTimeoutTime" BU_SG_REL_ L_UWB_RL_FD SG_ 2549874800 CBV_RMR_CGW_CCU 1500;
BA_REL_ "GenSigTimeoutTime" BU_SG_REL_ L_UWB_RR_FD SG_ 2549874800 CBV_RMR_CGW_CCU 1500;
BA_REL_ "GenSigTimeoutTime" BU_SG_REL_ L_UWB_TRNK_FD SG_ 2549874800 CBV_RMR_CGW_CCU 1500;
BA_REL_ "GenSigTimeoutTime" BU_SG_REL_ L_WPC_FD SG_ 2549874800 CBV_RMR_CGW_CCU 1500;
BA_REL_ "GenSigTimeoutTime" BU_SG_REL_ L_DHL_FD SG_ 2549874800 CBV_NMCoID_CGW_CCU 1500;
BA_REL_ "GenSigTimeoutTime" BU_SG_REL_ L_DHRL_FD SG_ 2549874800 CBV_NMCoID_CGW_CCU 1500;
BA_REL_ "GenSigTimeoutTime" BU_SG_REL_ L_DHRR_FD SG_ 2549874800 CBV_NMCoID_CGW_CCU 1500;
BA_REL_ "GenSigTimeoutTime" BU_SG_REL_ L_DHR_FD SG_ 2549874800 CBV_NMCoID_CGW_CCU 1500;
BA_REL_ "GenSigTimeoutTime" BU_SG_REL_ L_SAL_FD SG_ 2549874800 CBV_NMCoID_CGW_CCU 1500;
BA_REL_ "GenSigTimeoutTime" BU_SG_REL_ L_TPMS_FD SG_ 2549874800 CBV_NMCoID_CGW_CCU 1500;
BA_REL_ "GenSigTimeoutTime" BU_SG_REL_ L_UWB_BLE_MST_FD SG_ 2549874800 CBV_NMCoID_CGW_CCU 1500;
BA_REL_ "GenSigTimeoutTime" BU_SG_REL_ L_UWB_BLE_SLV_FD SG_ 2549874800 CBV_NMCoID_CGW_CCU 1500;
BA_REL_ "GenSigTimeoutTime" BU_SG_REL_ L_UWB_FL_FD SG_ 2549874800 CBV_NMCoID_CGW_CCU 1500;
BA_REL_ "GenSigTimeoutTime" BU_SG_REL_ L_UWB_FRNK_FD SG_ 2549874800 CBV_NMCoID_CGW_CCU 1500;
BA_REL_ "GenSigTimeoutTime" BU_SG_REL_ L_UWB_FR_FD SG_ 2549874800 CBV_NMCoID_CGW_CCU 1500;
BA_REL_ "GenSigTimeoutTime" BU_SG_REL_ L_UWB_RL_FD SG_ 2549874800 CBV_NMCoID_CGW_CCU 1500;
BA_REL_ "GenSigTimeoutTime" BU_SG_REL_ L_UWB_RR_FD SG_ 2549874800 CBV_NMCoID_CGW_CCU 1500;
BA_REL_ "GenSigTimeoutTime" BU_SG_REL_ L_UWB_TRNK_FD SG_ 2549874800 CBV_NMCoID_CGW_CCU 1500;
BA_REL_ "GenSigTimeoutTime" BU_SG_REL_ L_WPC_FD SG_ 2549874800 CBV_NMCoID_CGW_CCU 1500;
BA_REL_ "GenSigTimeoutTime" BU_SG_REL_ L_TPMS_FD SG_ 2348810242 TPMS_SnsrIdRrVal 1500;
BA_REL_ "GenSigTimeoutTime" BU_SG_REL_ L_TPMS_FD SG_ 2348810242 TPMS_FrontLowPressureWarnSetVal 1500;
BA_REL_ "GenSigTimeoutTime" BU_SG_REL_ L_TPMS_FD SG_ 2348810242 TPMS_RearLowPressureWarnSetVal 1500;
BA_REL_ "GenSigTimeoutTime" BU_SG_REL_ L_TPMS_FD SG_ 2348810242 TPMS_FrontLowPressureWarnClearVa 1500;
BA_REL_ "GenSigTimeoutTime" BU_SG_REL_ L_TPMS_FD SG_ 2348810242 TPMS_RearLowPressureWarnClearVal 1500;
BA_REL_ "GenSigTimeoutTime" BU_SG_REL_ L_TPMS_FD SG_ 2348810242 TPMS_SensorSupplierInfo 1500;
BA_REL_ "GenSigTimeoutTime" BU_SG_REL_ L_TPMS_FD SG_ 2348810242 TPMS_RfConfigueVal 1500;
BA_REL_ "GenSigTimeoutTime" BU_SG_REL_ L_TPMS_FD SG_ 2348810242 TPMS_SnsrIdFlVal 1500;
BA_REL_ "GenSigTimeoutTime" BU_SG_REL_ L_TPMS_FD SG_ 2348810242 TPMS_LowPressureWarnSta 1500;
BA_REL_ "GenSigTimeoutTime" BU_SG_REL_ L_TPMS_FD SG_ 2348810242 TPMS_LastTpsDataReq 1500;
BA_REL_ "GenSigTimeoutTime" BU_SG_REL_ L_TPMS_FD SG_ 2348810242 TPMS_SnsrIdFrVal 1500;
BA_REL_ "GenSigTimeoutTime" BU_SG_REL_ L_TPMS_FD SG_ 2348810242 TPMS_SnsrIdRlVal 1500;
BA_REL_ "GenSigTimeoutTime" BU_SG_REL_ L_DHRL_FD SG_ 1459 GST_DHRL_Byte0 0;
BA_REL_ "GenSigTimeoutTime" BU_SG_REL_ L_DHRL_FD SG_ 1459 GST_DHRL_Byte2 0;
BA_REL_ "GenSigTimeoutTime" BU_SG_REL_ L_DHRL_FD SG_ 1459 GST_DHRL_Byte3 0;
BA_REL_ "GenSigTimeoutTime" BU_SG_REL_ L_DHRL_FD SG_ 1459 GST_DHRL_Byte4 0;
BA_REL_ "GenSigTimeoutTime" BU_SG_REL_ L_DHRL_FD SG_ 1459 GST_DHRL_Byte5 0;
BA_REL_ "GenSigTimeoutTime" BU_SG_REL_ L_DHRL_FD SG_ 1459 GST_DHRL_Byte6 0;
BA_REL_ "GenSigTimeoutTime" BU_SG_REL_ L_DHRL_FD SG_ 1459 GST_DHRL_Byte7 0;
BA_REL_ "GenSigTimeoutTime" BU_SG_REL_ L_DHRL_FD SG_ 1459 GST_DHRL_Byte1 0;
BA_REL_ "GenSigTimeoutTime" BU_SG_REL_ L_DHRR_FD SG_ 1460 GST_DHRR_Byte0 0;
BA_REL_ "GenSigTimeoutTime" BU_SG_REL_ L_DHRR_FD SG_ 1460 GST_DHRR_Byte2 0;
BA_REL_ "GenSigTimeoutTime" BU_SG_REL_ L_DHRR_FD SG_ 1460 GST_DHRR_Byte3 0;
BA_REL_ "GenSigTimeoutTime" BU_SG_REL_ L_DHRR_FD SG_ 1460 GST_DHRR_Byte4 0;
BA_REL_ "GenSigTimeoutTime" BU_SG_REL_ L_DHRR_FD SG_ 1460 GST_DHRR_Byte5 0;
BA_REL_ "GenSigTimeoutTime" BU_SG_REL_ L_DHRR_FD SG_ 1460 GST_DHRR_Byte6 0;
BA_REL_ "GenSigTimeoutTime" BU_SG_REL_ L_DHRR_FD SG_ 1460 GST_DHRR_Byte7 0;
BA_REL_ "GenSigTimeoutTime" BU_SG_REL_ L_DHRR_FD SG_ 1460 GST_DHRR_Byte1 0;
BA_REL_ "GenSigTimeoutTime" BU_SG_REL_ L_UWB_BLE_MST_FD SG_ 2281701616 UWB_RL_SW_MCU_Ver_Major 1500;
BA_REL_ "GenSigTimeoutTime" BU_SG_REL_ L_UWB_BLE_MST_FD SG_ 2281701616 UWB_RL_SW_MCU_Ver_Minor 1500;
BA_REL_ "GenSigTimeoutTime" BU_SG_REL_ L_UWB_BLE_MST_FD SG_ 2281701616 UWB_RL_SW_IC_Ver_Major 1500;
BA_REL_ "GenSigTimeoutTime" BU_SG_REL_ L_UWB_BLE_MST_FD SG_ 2281701616 UWB_RL_SW_IC_Ver_Minor 1500;
BA_REL_ "GenSigTimeoutTime" BU_SG_REL_ L_UWB_BLE_MST_FD SG_ 2281701616 UWB_RL_DTC 1500;
BA_REL_ "GenSigTimeoutTime" BU_SG_REL_ GW_BDC_FD SG_ 2281701616 UWB_RL_Status1 1500;
BA_REL_ "GenSigTimeoutTime" BU_SG_REL_ L_UWB_BLE_MST_FD SG_ 2281701616 UWB_RL_Status1 1500;
BA_REL_ "GenSigTimeoutTime" BU_SG_REL_ GW_BDC_FD SG_ 2281701616 UWB_RL_Status2 1500;
BA_REL_ "GenSigTimeoutTime" BU_SG_REL_ L_UWB_BLE_MST_FD SG_ 2281701616 UWB_RL_Status2 1500;
BA_REL_ "GenSigTimeoutTime" BU_SG_REL_ GW_BDC_FD SG_ 2281701616 UWB_RL_Status3 1500;
BA_REL_ "GenSigTimeoutTime" BU_SG_REL_ L_UWB_BLE_MST_FD SG_ 2281701616 UWB_RL_Status3 1500;
BA_REL_ "GenSigTimeoutTime" BU_SG_REL_ GW_BDC_FD SG_ 2281701616 UWB_RL_Status4 1500;
BA_REL_ "GenSigTimeoutTime" BU_SG_REL_ L_UWB_BLE_MST_FD SG_ 2281701616 UWB_RL_Status4 1500;
BA_REL_ "GenSigTimeoutTime" BU_SG_REL_ GW_BDC_FD SG_ 2281701616 UWB_RL_Status5 1500;
BA_REL_ "GenSigTimeoutTime" BU_SG_REL_ L_UWB_BLE_MST_FD SG_ 2281701616 UWB_RL_Status5 1500;
BA_REL_ "GenSigTimeoutTime" BU_SG_REL_ GW_BDC_FD SG_ 2281701616 UWB_RL_Status6 1500;
BA_REL_ "GenSigTimeoutTime" BU_SG_REL_ L_UWB_BLE_MST_FD SG_ 2281701616 UWB_RL_Status6 1500;
BA_REL_ "GenSigTimeoutTime" BU_SG_REL_ GW_BDC_FD SG_ 2281701616 UWB_RL_Status7 1500;
BA_REL_ "GenSigTimeoutTime" BU_SG_REL_ L_UWB_BLE_MST_FD SG_ 2281701616 UWB_RL_Status7 1500;
BA_REL_ "GenSigTimeoutTime" BU_SG_REL_ GW_BDC_FD SG_ 2281701616 UWB_RL_Status8 1500;
BA_REL_ "GenSigTimeoutTime" BU_SG_REL_ L_UWB_BLE_MST_FD SG_ 2281701616 UWB_RL_Status8 1500;
BA_REL_ "GenSigTimeoutTime" BU_SG_REL_ GW_BDC_FD SG_ 2281701616 UWB_RL_Status9 1500;
BA_REL_ "GenSigTimeoutTime" BU_SG_REL_ L_UWB_BLE_MST_FD SG_ 2281701616 UWB_RL_Status9 1500;
BA_REL_ "GenSigTimeoutTime" BU_SG_REL_ GW_BDC_FD SG_ 2281701616 UWB_RL_Status10 1500;
BA_REL_ "GenSigTimeoutTime" BU_SG_REL_ L_UWB_BLE_MST_FD SG_ 2281701616 UWB_RL_Status10 1500;
BA_REL_ "GenSigTimeoutTime" BU_SG_REL_ GW_BDC_FD SG_ 2281701616 UWB_RL_Status11 1500;
BA_REL_ "GenSigTimeoutTime" BU_SG_REL_ L_UWB_BLE_MST_FD SG_ 2281701616 UWB_RL_Status11 1500;
BA_REL_ "GenSigTimeoutTime" BU_SG_REL_ GW_BDC_FD SG_ 2281701616 UWB_RL_Status12 1500;
BA_REL_ "GenSigTimeoutTime" BU_SG_REL_ L_UWB_BLE_MST_FD SG_ 2281701616 UWB_RL_Status12 1500;
BA_REL_ "GenSigTimeoutTime" BU_SG_REL_ GW_BDC_FD SG_ 2281701616 UWB_RL_Status13 1500;
BA_REL_ "GenSigTimeoutTime" BU_SG_REL_ L_UWB_BLE_MST_FD SG_ 2281701616 UWB_RL_Status13 1500;
BA_REL_ "GenSigTimeoutTime" BU_SG_REL_ GW_BDC_FD SG_ 2281701616 UWB_RL_Status14 1500;
BA_REL_ "GenSigTimeoutTime" BU_SG_REL_ L_UWB_BLE_MST_FD SG_ 2281701616 UWB_RL_Status14 1500;
BA_REL_ "GenSigTimeoutTime" BU_SG_REL_ GW_BDC_FD SG_ 2281701616 UWB_RL_Status15 1500;
BA_REL_ "GenSigTimeoutTime" BU_SG_REL_ L_UWB_BLE_MST_FD SG_ 2281701616 UWB_RL_Status15 1500;
BA_REL_ "GenSigTimeoutTime" BU_SG_REL_ GW_BDC_FD SG_ 2281701616 UWB_RL_Status16 1500;
BA_REL_ "GenSigTimeoutTime" BU_SG_REL_ L_UWB_BLE_MST_FD SG_ 2281701616 UWB_RL_Status16 1500;
BA_REL_ "GenSigTimeoutTime" BU_SG_REL_ L_UWB_BLE_MST_FD SG_ 2281701616 UWB_RL_HW_Ver_Major 1500;
BA_REL_ "GenSigTimeoutTime" BU_SG_REL_ L_UWB_BLE_MST_FD SG_ 2281701616 UWB_RL_HW_Ver_Minor 1500;
BA_REL_ "GenSigTimeoutTime" BU_SG_REL_ L_ROA_FD SG_ 979 Warn_RrStRmndAlrmInfo_1_Copy_0 1500;
BA_REL_ "GenSigTimeoutTime" BU_SG_REL_ L_UWB_BLE_MST_FD SG_ 2533736961 TRNK_SWID_4_IVD_1 0;
BA_REL_ "GenSigTimeoutTime" BU_SG_REL_ GW_BDC_FD SG_ 1467 DHRL_GST_Byte0 0;
BA_REL_ "GenSigTimeoutTime" BU_SG_REL_ GW_BDC_FD SG_ 1467 DHRL_GST_Byte2 0;
BA_REL_ "GenSigTimeoutTime" BU_SG_REL_ GW_BDC_FD SG_ 1467 DHRL_GST_Byte3 0;
BA_REL_ "GenSigTimeoutTime" BU_SG_REL_ GW_BDC_FD SG_ 1467 DHRL_GST_Byte4 0;
BA_REL_ "GenSigTimeoutTime" BU_SG_REL_ GW_BDC_FD SG_ 1467 DHRL_GST_Byte5 0;
BA_REL_ "GenSigTimeoutTime" BU_SG_REL_ GW_BDC_FD SG_ 1467 DHRL_GST_Byte6 0;
BA_REL_ "GenSigTimeoutTime" BU_SG_REL_ GW_BDC_FD SG_ 1467 DHRL_GST_Byte7 0;
BA_REL_ "GenSigTimeoutTime" BU_SG_REL_ GW_BDC_FD SG_ 1467 DHRL_GST_Byte1 0;
BA_REL_ "GenSigTimeoutTime" BU_SG_REL_ L_ROA_FD SG_ 977 BCM_Ign1InSta_Copy_0 1500;
BA_REL_ "GenSigTimeoutTime" BU_SG_REL_ L_ROA_FR_FD SG_ 977 BCM_Ign1InSta_Copy_0 1500;
BA_REL_ "GenSigTimeoutTime" BU_SG_REL_ L_TPMS_FD SG_ 977 BCM_Ign1InSta_Copy_0 1500;
BA_REL_ "GenSigTimeoutTime" BU_SG_REL_ L_UWB_BLE_MST_FD SG_ 977 BCM_Ign1InSta_Copy_0 1500;
BA_REL_ "GenSigTimeoutTime" BU_SG_REL_ L_UWB_BLE_SLV_FD SG_ 977 BCM_Ign1InSta_Copy_0 1500;
BA_REL_ "GenSigTimeoutTime" BU_SG_REL_ L_ROA_FD SG_ 977 BCM_Ign2InSta_Copy_0 1500;
BA_REL_ "GenSigTimeoutTime" BU_SG_REL_ L_ROA_FR_FD SG_ 977 BCM_Ign2InSta_Copy_0 1500;
BA_REL_ "GenSigTimeoutTime" BU_SG_REL_ L_UWB_BLE_MST_FD SG_ 977 BCM_Ign2InSta_Copy_0 1500;
BA_REL_ "GenSigTimeoutTime" BU_SG_REL_ L_UWB_BLE_SLV_FD SG_ 977 BCM_Ign2InSta_Copy_0 1500;
BA_REL_ "GenSigTimeoutTime" BU_SG_REL_ L_UWB_BLE_MST_FD SG_ 2529538561 RL_SWID_4_IVD_1 0;
BA_REL_ "GenSigTimeoutTime" BU_SG_REL_ GW_BDC_FD SG_ 1468 DHRR_GST_Byte0 0;
BA_REL_ "GenSigTimeoutTime" BU_SG_REL_ GW_BDC_FD SG_ 1468 DHRR_GST_Byte2 0;
BA_REL_ "GenSigTimeoutTime" BU_SG_REL_ GW_BDC_FD SG_ 1468 DHRR_GST_Byte3 0;
BA_REL_ "GenSigTimeoutTime" BU_SG_REL_ GW_BDC_FD SG_ 1468 DHRR_GST_Byte4 0;
BA_REL_ "GenSigTimeoutTime" BU_SG_REL_ GW_BDC_FD SG_ 1468 DHRR_GST_Byte5 0;
BA_REL_ "GenSigTimeoutTime" BU_SG_REL_ GW_BDC_FD SG_ 1468 DHRR_GST_Byte6 0;
BA_REL_ "GenSigTimeoutTime" BU_SG_REL_ GW_BDC_FD SG_ 1468 DHRR_GST_Byte7 0;
BA_REL_ "GenSigTimeoutTime" BU_SG_REL_ GW_BDC_FD SG_ 1468 DHRR_GST_Byte1 0;
VAL_ 994 PDC_FD_Crc3Val 0 "0x0x0~0xFFFF:CRCValue" 65535 "0x0x0~0xFFFF:CRCValue" ;
VAL_ 994 PDC_FD_AlvCnt3Val 0 "0x0x0~0xFF:AlvCntValue" 255 "0x0x0~0xFF:AlvCntValue" ;
VAL_ 994 Warn_DrvDrSwSta_Copy_0 0 "Close" 1 "Open" 2 "Not Used" 3 "Error Indicator" ;
VAL_ 994 Warn_AsstDrSwSta_Copy_0 0 "Close" 1 "Open" 2 "Not Used" 3 "Error Indicator" ;
VAL_ 994 Warn_RrLftDrSwSta_Copy_0 0 "Close" 1 "Open" 2 "Not Used" 3 "Error Indicator" ;
VAL_ 994 Warn_RrRtDrSwSta_Copy_0 0 "Close" 1 "Open" 2 "Not Used" 3 "Error Indicator" ;
VAL_ 994 Warn_HoodSwSta_Copy_0 0 "Off" 1 "On" 2 "Not Used" 3 "Error Indicator" ;
VAL_ 994 DoorLock_DrvDrUnLkSta_Copy_0 0 "Lock" 1 "Unlock" 2 "Not Used" 3 "Error Indicator" ;
VAL_ 994 DoorLock_AsstDrUnLkSta_Copy_0 0 "Lock" 1 "Unlock" 2 "Not Used" 3 "Error Indicator" ;
VAL_ 994 DoorLock_RrLftDrUnLkSta_Copy_0 0 "Lock" 1 "Unlock" 2 "Not Used" 3 "Error Indicator" ;
VAL_ 994 DoorLock_RrRtDrUnLkSta_Copy_0 0 "Lock" 1 "Unlock" 2 "Not Used" 3 "Error Indicator" ;
VAL_ 994 DoorLock_DrvKeyLkSwSta_Copy_0 0 "Off" 1 "Lock" 2 "Not Used" 3 "Error Indicator" ;
VAL_ 994 DoorLock_DrvKeyUnLkSwSta_Copy_0 0 "Off" 1 "Unlock" 2 "Not Used" 3 "Error Indicator" ;
VAL_ 994 DoorLock_CtrlDrLkSwSta_ICU_Copy_ 0 "Off" 1 "On(Lock On)" 2 "Not Used" 3 "Error Indicator" ;
VAL_ 994 DoorLock_CtrlDrUnLkSwSta_ICU_Cop 0 "Off" 1 "On(Unlock On)" 2 "Not Used" 3 "Error Indicator" ;
VAL_ 994 DoorLock_CtrlDrLkUnLkSwSta_ICU_C 0 "Off" 1 "On" 2 "Not Used" 3 "Error Indicator" ;
VAL_ 994 C_CrashUnlockState_Copy_0 0 "Off" 1 "Unlock(Crash)" 2 "RESERVED" 3 "RESERVED" ;
VAL_ 994 Lamp_LedHdLmpSta_Copy_0 0 "LED Headlamp is in nornal condition" 1 "RESERVED" 2 "LED Fail" 3 "RESERVED" ;
VAL_ 994 Warn_ChaDrSwFrtSta_Copy_0 0 "Default" 1 "Close" 2 "Open" 3 "Error Indicator" ;
VAL_ 994 Warn_ChaDrSwRrSta_Copy_0 0 "Default" 1 "Close" 2 "Open" 3 "Error Indicator" ;
VAL_ 2348810241 L_BDC_FD_Crc1Val 0 "0x0x0~0xFFFF:CRCValue" 65535 "0x0x0~0xFFFF:CRCValue" ;
VAL_ 2348810241 MoodLamp_BottomBlueVal 0 "0x0x00~0xFF:Blue Color 0~255" 255 "0x0x00~0xFF:Blue Color 0~255" ;
VAL_ 2348810241 MoodLamp_AIVoiceMicLevel 0 "Default" 1 "MiCModLVL 1~62" 2 "MiCModLVL 1~62" 3 "MiCModLVL 1~62" 4 "MiCModLVL 1~62" 5 "MiCModLVL 1~62" 6 "MiCModLVL 1~62" 7 "MiCModLVL 1~62" 8 "MiCModLVL 1~62" 9 "MiCModLVL 1~62" 10 "MiCModLVL 1~62" 11 "MiCModLVL 1~62" 12 "MiCModLVL 1~62" 13 "MiCModLVL 1~62" 14 "MiCModLVL 1~62" 15 "MiCModLVL 1~62" 16 "MiCModLVL 1~62" 17 "MiCModLVL 1~62" 18 "MiCModLVL 1~62" 19 "MiCModLVL 1~62" 20 "MiCModLVL 1~62" 21 "MiCModLVL 1~62" 22 "MiCModLVL 1~62" 23 "MiCModLVL 1~62" 24 "MiCModLVL 1~62" 25 "MiCModLVL 1~62" 26 "MiCModLVL 1~62" 27 "MiCModLVL 1~62" 28 "MiCModLVL 1~62" 29 "MiCModLVL 1~62" 30 "MiCModLVL 1~62" 31 "MiCModLVL 1~62" 32 "MiCModLVL 1~62" 33 "MiCModLVL 1~62" 34 "MiCModLVL 1~62" 35 "MiCModLVL 1~62" 36 "MiCModLVL 1~62" 37 "MiCModLVL 1~62" 38 "MiCModLVL 1~62" 39 "MiCModLVL 1~62" 40 "MiCModLVL 1~62" 41 "MiCModLVL 1~62" 42 "MiCModLVL 1~62" 43 "MiCModLVL 1~62" 44 "MiCModLVL 1~62" 45 "MiCModLVL 1~62" 46 "MiCModLVL 1~62" 47 "MiCModLVL 1~62" 48 "MiCModLVL 1~62" 49 "MiCModLVL 1~62" 50 "MiCModLVL 1~62" 51 "MiCModLVL 1~62" 52 "MiCModLVL 1~62" 53 "MiCModLVL 1~62" 54 "MiCModLVL 1~62" 55 "MiCModLVL 1~62" 56 "MiCModLVL 1~62" 57 "MiCModLVL 1~62" 58 "MiCModLVL 1~62" 59 "MiCModLVL 1~62" 60 "MiCModLVL 1~62" 61 "MiCModLVL 1~62" 62 "MiCModLVL 1~62" 63 "Invalid" ;
VAL_ 2348810241 MoodLamp_AIVoiceTTSLevel 0 "Default" 1 "TTSModLVL 1~62" 2 "TTSModLVL 1~62" 3 "TTSModLVL 1~62" 4 "TTSModLVL 1~62" 5 "TTSModLVL 1~62" 6 "TTSModLVL 1~62" 7 "TTSModLVL 1~62" 8 "TTSModLVL 1~62" 9 "TTSModLVL 1~62" 10 "TTSModLVL 1~62" 11 "TTSModLVL 1~62" 12 "TTSModLVL 1~62" 13 "TTSModLVL 1~62" 14 "TTSModLVL 1~62" 15 "TTSModLVL 1~62" 16 "TTSModLVL 1~62" 17 "TTSModLVL 1~62" 18 "TTSModLVL 1~62" 19 "TTSModLVL 1~62" 20 "TTSModLVL 1~62" 21 "TTSModLVL 1~62" 22 "TTSModLVL 1~62" 23 "TTSModLVL 1~62" 24 "TTSModLVL 1~62" 25 "TTSModLVL 1~62" 26 "TTSModLVL 1~62" 27 "TTSModLVL 1~62" 28 "TTSModLVL 1~62" 29 "TTSModLVL 1~62" 30 "TTSModLVL 1~62" 31 "TTSModLVL 1~62" 32 "TTSModLVL 1~62" 33 "TTSModLVL 1~62" 34 "TTSModLVL 1~62" 35 "TTSModLVL 1~62" 36 "TTSModLVL 1~62" 37 "TTSModLVL 1~62" 38 "TTSModLVL 1~62" 39 "TTSModLVL 1~62" 40 "TTSModLVL 1~62" 41 "TTSModLVL 1~62" 42 "TTSModLVL 1~62" 43 "TTSModLVL 1~62" 44 "TTSModLVL 1~62" 45 "TTSModLVL 1~62" 46 "TTSModLVL 1~62" 47 "TTSModLVL 1~62" 48 "TTSModLVL 1~62" 49 "TTSModLVL 1~62" 50 "TTSModLVL 1~62" 51 "TTSModLVL 1~62" 52 "TTSModLVL 1~62" 53 "TTSModLVL 1~62" 54 "TTSModLVL 1~62" 55 "TTSModLVL 1~62" 56 "TTSModLVL 1~62" 57 "TTSModLVL 1~62" 58 "TTSModLVL 1~62" 59 "TTSModLVL 1~62" 60 "TTSModLVL 1~62" 61 "TTSModLVL 1~62" 62 "TTSModLVL 1~62" 63 "Invalid" ;
VAL_ 2348810241 MoodLamp_VehicleSpeed 0 "0x0x0~0x1FE: Speed" 510 "0x0x0~0x1FE: Speed" 511 "Error indicator" ;
VAL_ 2348810241 MoodLamp_MLBrghtModCmd_6bit 0 "Off" 1 "BoostMode" 2 "VehicleOverSpeedMode" 3 "TherapyVitalityMode" 4 "TherapyDelightMode" 5 "TherapyCareMode" 6 "TherapyComfortMode" 7 "VehicleSpeedMode" 8 "NightDrivingMode" 9 "NormalMode" 10 "EarlyEveningDrivingMode" 11 "MoodCuratorSiestaAMode" 12 "MoodCuratorSiestaBMode" 13 "MoodCuratorSocialMode" 14 "MoodCuratorTheaterMode" 15 "WakeUp&Greeting" 16 "SpaceKeeping" 17 "Not Used" 18 "Not Used" 19 "Not Used" 20 "Not Used" 21 "Not Used" 22 "Not Used" 23 "Not Used" 24 "Not Used" 25 "Not Used" 26 "Not Used" 27 "Not Used" 28 "Not Used" 29 "Not Used" 30 "Not Used" 31 "Not Used" 32 "Not Used" 33 "Not Used" 34 "Not Used" 35 "Not Used" 36 "Not Used" 37 "Not Used" 38 "Not Used" 39 "Not Used" 40 "Not Used" 41 "Not Used" 42 "Not Used" 43 "Not Used" 44 "Not Used" 45 "Not Used" 46 "Not Used" 47 "Not Used" 48 "Not Used" 49 "Not Used" 50 "Not Used" 51 "Not Used" 52 "Not Used" 53 "Not Used" 54 "Not Used" 55 "Not Used" 56 "Not Used" 57 "Not Used" 58 "Not Used" 59 "Not Used" 60 "Not Used" 61 "Not Used" 62 "Not Used" 63 "Error Indicator" ;
VAL_ 2348810241 MoodLamp_MLColorModCmd_6bit 0 "Off" 1 "BoostMode" 2 "VehicleOverSpeedMode" 3 "TherapyVitalityMode" 4 "TherapyDelightMode" 5 "TherapyCareMode" 6 "TherapyComfortMode" 7 "DriveNormalMode" 8 "DriveEcoMode" 9 "DriveSportMode" 10 "DriveSportPlusMode" 11 "DriveSmartMode" 12 "DriveCustom1Mode" 13 "DriveNMode" 14 "DriveCustom2Mode" 15 "NormalMode" 16 "MoodCuratorDelightMode" 17 "MoodCuratorCozyMode" 18 "MoodCuratorCalmingMode" 19 "MoodCuratorSiestaCMode" 20 "Not Used" 21 "Not Used" 22 "Not Used" 23 "Not Used" 24 "Not Used" 25 "Not Used" 26 "Not Used" 27 "Not Used" 28 "Not Used" 29 "Not Used" 30 "Not Used" 31 "Not Used" 32 "Not Used" 33 "Not Used" 34 "Not Used" 35 "Not Used" 36 "Not Used" 37 "Not Used" 38 "Not Used" 39 "Not Used" 40 "Not Used" 41 "Not Used" 42 "Not Used" 43 "Not Used" 44 "Not Used" 45 "Not Used" 46 "Not Used" 47 "Not Used" 48 "Not Used" 49 "Not Used" 50 "Not Used" 51 "Not Used" 52 "Not Used" 53 "Not Used" 54 "Not Used" 55 "Not Used" 56 "Not Used" 57 "Not Used" 58 "Not Used" 59 "Not Used" 60 "Not Used" 61 "Not Used" 62 "Not Used" 63 "Error Indicator" ;
VAL_ 2348810241 MoodLamp_DrvTempChgModCmd 0 "Off" 1 "Up" 2 "Down" 3 "Error Indicator" ;
VAL_ 2348810241 MoodLamp_AstTempChgModCmd 0 "Off" 1 "Up" 2 "Down" 3 "Error Indicator" ;
VAL_ 2348810241 MoodLamp_PhoneCallModCmd 0 "Off" 1 "On" 2 "Not Used" 3 "Error Indicator" ;
VAL_ 2348810241 MoodLamp_AIVoiceRecogPosSta 0 "Default" 1 "Front Left" 2 "Front Right" 3 "Rear Left" 4 "Rear Right" 5 "Third Left" 6 "Third Right" 7 "Invalid" ;
VAL_ 2348810241 MoodLamp_FLDoorWarnModCmd 0 "Off" 1 "BCA" 2 "SEA" 3 "RCCA" 4 "RESERVED" 5 "RESERVED" 6 "RESERVED" 7 "Error Indicator" ;
VAL_ 2348810241 L_BDC_FD_AlvCnt1Val 0 "0x0x0~0xFF:AlvCntValue" 255 "0x0x0~0xFF:AlvCntValue" ;
VAL_ 2348810241 MoodLamp_FRDoorWarnModCmd 0 "Off" 1 "BCA" 2 "SEA" 3 "RCCA" 4 "RESERVED" 5 "RESERVED" 6 "RESERVED" 7 "Error Indicator" ;
VAL_ 2348810241 MoodLamp_RLDoorWarnModCmd 0 "Off" 1 "BCA" 2 "SEA" 3 "RCCA" 4 "RESERVED" 5 "RESERVED" 6 "RESERVED" 7 "Error Indicator" ;
VAL_ 2348810241 MoodLamp_RRDoorWarnModCmd 0 "Off" 1 "BCA" 2 "SEA" 3 "RCCA" 4 "RESERVED" 5 "RESERVED" 6 "RESERVED" 7 "Error Indicator" ;
VAL_ 2348810241 MoodLamp_HazardModCmd 0 "Inactive" 1 "Active(Off)" 2 "Active(On)" 3 "Error Indicator" ;
VAL_ 2348810241 MoodLamp_FLDoorObstacleModCmd 0 "Off" 1 "On" 2 "RESERVED" 3 "Error Indicator" ;
VAL_ 2348810241 MoodLamp_FRDoorObstacleModCmd 0 "Off" 1 "On" 2 "RESERVED" 3 "Error Indicator" ;
VAL_ 2348810241 MoodLamp_RLDoorObstacleModCmd 0 "Off" 1 "On" 2 "RESERVED" 3 "Error Indicator" ;
VAL_ 2348810241 MoodLamp_RRDoorObstacleModCmd 0 "Off" 1 "On" 2 "RESERVED" 3 "Error Indicator" ;
VAL_ 2348810241 MoodLamp_LowFuelWarnModCmd 0 "Off" 1 "On(AMBER)" 2 "On(RED)" 3 "Error Indicator" ;
VAL_ 2348810241 MoodLamp_NShiftModCmd 0 "Off" 1 "Step1" 2 "Step2" 3 "Step3" 4 "Step4" 5 "Step5" 6 "Step6 (LED Blinking)" 7 "Invalid" ;
VAL_ 2348810241 MoodLamp_MLBrghtModCmd 0 "Off" 1 "BoostMode" 2 "VehicleOverSpeedMode" 3 "TherapyVitalityMode" 4 "TherapyDelightMode" 5 "TherapyCareMode" 6 "TherapyComfortMode" 7 "VehicleSpeedMode" 8 "NightDrivingMode" 9 "NormalMode" 10 "EarlyEveningDrivingMode" 11 "NotUsed" 12 "NotUsed" 13 "NotUsed" 14 "NotUsed" 15 "Error Indicator" ;
VAL_ 2348810241 MoodLamp_MLColorModCmd 0 "Off" 1 "BoostMode" 2 "VehicleOverSpeedMode" 3 "TherapyVitalityMode" 4 "TherapyDelightMode" 5 "TherapyCareMode" 6 "TherapyComfortMode" 7 "DriveNormalMode" 8 "DriveEcoMode" 9 "DriveSportMode" 10 "DriveSportPlusMode" 11 "DriveSmartMode" 12 "DriveCustom1Mode" 13 "DriveNMode" 14 "DriveCustom2Mode" 15 "NormalMode" ;
VAL_ 2348810241 MoodLamp_WelcomeAndGoodbyeSeqMod 0 "Off" 1 "Welcome" 2 "Goodbye" 3 "Error Indicator" ;
VAL_ 2348810241 MoodLamp_AIVoiceSeqModCmd 0 "Default" 1 "AI Voice Start" 2 "User Response" 3 "User No Response/ 0x4:Processing" 5 "AI Voice Response" 6 "AI Voice End" 7 "Error Indicator" ;
VAL_ 2348810241 MoodLamp_EngineRunningSeqModCmd 0 "Off" 1 "EngineOn" 2 "EngineOff" 3 "Error Indicator" ;
VAL_ 2348810241 MoodLamp_OverSpeedSeqModCmd 0 "Off" 1 "On" 2 "Not Used" 3 "Error Indicator" ;
VAL_ 2348810241 MoodLamp_DriveSeqModCmd 0 "Off" 1 "Normal" 2 "Eco" 3 "Sport" 4 "SportPlus" 5 "Smart" 6 "Custom1" 7 "Nmode" 8 "Custom2" 9 "Not Used" 10 "Not Used" 11 "Not Used" 12 "Not Used" 13 "Not Used" 14 "Not Used" 15 "Error Indicator" ;
VAL_ 2348810241 MoodLamp_AirCleaningSeqModCmd 0 "Off" 1 "Mono Color" 2 "Blue Color" 3 "Green Color" 4 "Orange Color" 5 "Red Color" 6 "Yellow Color" 7 "Gray Color(Deactivate)" ;
VAL_ 2348810241 MoodLamp_FootLampModCmd 0 "Off" 1 "On" 2 "Dim Out" 3 "AnyDoorOpen" ;
VAL_ 2348810241 MoodLamp_SunroofModCmd 0 "BothClose" 1 "GlassCloseBlindNotClose" 2 "GlassNotClose" 3 "Error Indicator" ;
VAL_ 2348810241 MoodLamp_BrghtVal 0 "Off" 1 "step1~10" 2 "step1~10" 3 "step1~10" 4 "step1~10" 5 "step1~10" 6 "step1~10" 7 "step1~10" 8 "step1~10" 9 "step1~10" 10 "step1~10" 11 "Not Used" 12 "Not Used" 13 "Not Used" 14 "Not Used" 15 "Error Indicator" ;
VAL_ 2348810241 MoodLamp_RedVal 0 "0x0x00~0xFF:Red Color 0~255" 255 "0x0x00~0xFF:Red Color 0~255" ;
VAL_ 2348810241 MoodLamp_GreenVal 0 "0x0x00~0xFF:Green Color 0~255" 255 "0x0x00~0xFF:Green Color 0~255" ;
VAL_ 2348810241 MoodLamp_BlueVal 0 "0x0x00~0xFF:Blue Color 0~255" 255 "0x0x00~0xFF:Blue Color 0~255" ;
VAL_ 2348810241 MoodLamp_BottomRedVal 0 "0x0x00~0xFF:Red Color 0~255" 255 "0x0x00~0xFF:Red Color 0~255" ;
VAL_ 2348810241 MoodLamp_BottomGreenVal 0 "0x0x00~0xFF:Green Color 0~255" 255 "0x0x00~0xFF:Green Color 0~255" ;
VAL_ 996 PDC_FD_Crc10Val 0 "0x0x0~0xFFFF:CRCValue" 65535 "0x0x0~0xFFFF:CRCValue" ;
VAL_ 996 PDC_PwrOnModePowerReq_Copy_0 0 "Default" 1 "Request On" 2 "RESERVED" 3 "Error" ;
VAL_ 996 PDC_LeadAcidBatType_Copy_0 0 "Not Applied" 1 "CMF 35Ah" 2 "CMF 40Ah" 3 "CMF 45Ah" 4 "CMF 50Ah" 5 "CMF 60Ah" 6 "CMF 68Ah" 7 "CMF 70Ah" 8 "CMF 80Ah" 9 "CMF 90Ah" 10 "CMF 110Ah" 11 "MF 40Ah" 12 "MF 45Ah" 13 "MF 60Ah" 14 "MF 68Ah" 15 "MF 80Ah" 16 "MF 90Ah" 17 "MF 110Ah" 18 "AGM 60Ah" 19 "AGM 70Ah" 20 "AGM 80Ah" 21 "AGM 50Ah" 22 "AGM 105Ah" 23 "AGM 90Ah" 24 "EFB 50Ah" 25 "EFB 60Ah" 26 "EFB 70Ah" 27 "RESERVED" 28 "RESERVED" 29 "RESERVED" 30 "RESERVED" 31 "RESERVED" ;
VAL_ 996 PDC_BatPwrClassOpt_Copy_0 0 "Invalid" 1 "SOC type" 2 "Class type" 3 "RESERVED" ;
VAL_ 996 PDC_MainLBMOpt 0 "Not Applied" 1 "Applied" 2 "RESERVED" 3 "Invalid" ;
VAL_ 996 PDC_FD_AlvCnt10Val 0 "0x0x0~0xFF:AlvCntValue" 255 "0x0x0~0xFF:AlvCntValue" ;
VAL_ 996 ICU_PowerAutoCutModSta_Copy_0 0 "Factory Mode (default)" 1 "Dealer Mode" 2 "Customer Mode" 3 "Error Indicator" ;
VAL_ 996 Autocut_DlvryModSta_Copy_0 0 "Before Delivery(Welcome Off)" 1 "After Delivery(Welcome On)" 2 "Not Used" 3 "Error Indicator" ;
VAL_ 996 ICU_SoCBattStaMsgReq_Copy_0 0 "Default" 1 "Alert" 2 "Warning" 3 "Invalid" ;
VAL_ 996 Batt_SoCWarningValue_Copy_0 0 "0x0x0~0x64:0 ~ 100%" 100 "0x0x0~0x64:0 ~ 100%" 101 "0x65~0xFE:RESERVED" 254 "0x65~0xFE:RESERVED" 255 "Invalid" ;
VAL_ 996 ICU_BattAutoCutPreWrng_Copy_0 0 "No Warning" 1 "Warning" 2 "Not Used" 3 "Invalid" ;
VAL_ 996 OTAModeACCOffReq_Copy_0 0 "Default" 1 "Off(ACC Off Request)" 2 "RESERVED" 3 "RESERVED" ;
VAL_ 996 C_ICUIGNOffReq_Copy_0 0 "Default" 1 "Off(IGN Off Request)" 2 "RESERVED" 3 "RESERVED" ;
VAL_ 996 IGN_AutoOff_WarnSta_Copy_0 0 "No Warning" 1 "Power Off Warning" 2 "RESERVED" 3 "Error Indicator" ;
VAL_ 996 IGN_AutoOff_WarnSta_CLU_Copy_0 0 "No Warning" 1 "Power Off Warning" 2 "RESERVED" 3 "Error Indicator" ;
VAL_ 996 PDC_BatPwrStateClassA_Copy_0 0 "Invalid" 1 "Low power condition for ClassA-load operation" 2 "High power condition for ClassA-load operation" 3 "RESERVED" ;
VAL_ 996 PDC_BatPwrStateClassB_Copy_0 0 "Invalid" 1 "Low power condition for ClassB-load operation" 2 "High power condition for ClassB-load operation" 3 "RESERVED" ;
VAL_ 996 PDC_BatPwrStateClassC_Copy_0 0 "Invalid" 1 "Low power condition for ClassC-load operation" 2 "High power condition for ClassC-load operation" 3 "RESERVED" ;
VAL_ 996 PLBMAvailableState_Copy_0 0 "Invaild" 1 "PLBM Power is available" ;
VAL_ 996 Bat_dischrg_Copy_0 0 "Flag OFF" 1 "Flag ON" 2 "RESERVED" 3 "RESERVED" ;
VAL_ 996 Bat12V_Chr_Req_Copy_0 0 "Off (Default)" 1 "On_IBS" 2 "On_OTA" 3 "On_Load" ;
VAL_ 996 ICU_BattMngAlert_Copy_0 0 "No Warning(Default)" 1 "Hazard On" 2 "Tail On" 3 "Hazard/Tail On" 4 "0x4~0xFE:RESERVED" 254 "0x4~0xFE:RESERVED" 255 "Invalid" ;
VAL_ 2549874800 SNI_CGW_CCU 0 "0x0x0~0xFF:NM Source Node ID" 255 "0x0x0~0xFF:NM Source Node ID" ;
VAL_ 2549874800 CBV_NMCoSRB_CGW_CCU 0 "Start of synchronized shutdown is not requested by main coordinator" 1 "Start of synchronized shutdown is requested by main coordinator" ;
VAL_ 2549874800 CBV_AWB_CGW_CCU 0 "Node has not woken up the network (passive wakeup)" 1 "Node has woken up the network (active wakeup)" ;
VAL_ 2549874800 PNI_CGW_CCU_2 0 "0x0~0xFFFFFFFFFFFFFFFF:NM PNC Bit" ;
VAL_ 2549874800 CBV_PNIB_CGW_CCU 0 "NM PDU contains no partial network cluster information in the user data area" 1 "NM PDU contains partial network cluster information in the user data area" ;
VAL_ 2549874800 NRR_CGW_CCU 0 "Default" 1 "0x1~0xFF:RESERVED" 255 "0x1~0xFF:RESERVED" ;
VAL_ 2549874800 PNI_CGW_CCU_3 0 "0x0~0xFFFFFFFFFFFFFFFF:NM PNC Bit" ;
VAL_ 2549874800 NM_State_CGW_CCU 0 "Default" 1 "NM_RMS_BSM" 2 "NM_RMS_PBSM" 3 "RESERVED" 4 "NM_NS_RMS" 5 "RESERVED" 6 "RESERVED" 7 "RESERVED" 8 "NM_NS_RSS" 9 "RESERVED" 10 "RESERVED" 11 "RESERVED" 12 "RESERVED" 13 "RESERVED" 14 "RESERVED" 15 "RESERVED" 16 "NM_RMS_RSS" 17 "RESERVED" 18 "RESERVED" 19 "RESERVED" 20 "RESERVED" 21 "RESERVED" 22 "RESERVED" 23 "RESERVED" 24 "RESERVED" 25 "RESERVED" 26 "RESERVED" 27 "RESERVED" 28 "RESERVED" 29 "RESERVED" 30 "RESERVED" 31 "RESERVED" 32 "NM_RMS_NS" 33 "0x21~0xFF:RESERVED" 255 "0x21~0xFF:RESERVED" ;
VAL_ 2549874800 PNI_CGW_CCU 0 "0x0x0~0xFFFFFFFF:NM PNC Bit" 2147483647 "0x0x0~0xFFFFFFFF:NM PNC Bit" ;
VAL_ 2549874800 PNI_CGW_CCU_1 0 "0x0~0xFFFFFFFFFFFFFFFF:NM PNC Bit" ;
VAL_ 2549874800 CBV_RMR_CGW_CCU 0 "Repeat Message State not requested" 1 "Repeat Message State requested" ;
VAL_ 2549874800 CBV_NMCoID_CGW_CCU 0 "NM Coordinator ID" 1 "NM Coordinator ID" 2 "NM Coordinator ID" 3 "NM Coordinator ID" ;
VAL_ 2348810242 TPMS_SnsrIdRrVal 0 "0x0x0~0xFFFFFFFE:IDValue" 2147483647 "0x0x0~0xFFFFFFFE:IDValue" 2147483647 "Invalid" ;
VAL_ 2348810242 TPMS_FrontLowPressureWarnSetVal 0 "0x0x0~0xFFFE:LowPressureSetValue" 65534 "0x0x0~0xFFFE:LowPressureSetValue" 65535 "Invalid" ;
VAL_ 2348810242 TPMS_RearLowPressureWarnSetVal 0 "0x0x0~0xFFFE:LowPressureSetValue" 65534 "0x0x0~0xFFFE:LowPressureSetValue" 65535 "Invalid" ;
VAL_ 2348810242 TPMS_FrontLowPressureWarnClearVa 0 "0x0x0~0xFFFE:LowPressureClearValue" 65534 "0x0x0~0xFFFE:LowPressureClearValue" 65535 "Invalid" ;
VAL_ 2348810242 TPMS_RearLowPressureWarnClearVal 0 "0x0x0~0xFFFE:LowPressureClearValue" 65534 "0x0x0~0xFFFE:LowPressureClearValue" 65535 "Invalid" ;
VAL_ 2348810242 TPMS_SensorSupplierInfo 0 "Continental(default)" 1 "Sensata" 2 "Baolong" 3 "Continental _commercial" ;
VAL_ 2348810242 TPMS_RfConfigueVal 0 "433MHz" 1 "315MHz" 2 "RESERVED" 3 "Error Indicator" ;
VAL_ 2348810242 TPMS_SnsrIdFlVal 0 "0x0x0~0xFFFFFFFE:IDValue" 2147483647 "0x0x0~0xFFFFFFFE:IDValue" 2147483647 "Invalid" ;
VAL_ 2348810242 TPMS_LowPressureWarnSta 0 "LowPressureWarningSta" 1 "LowPressureWarningSta" 2 "LowPressureWarningSta" 3 "LowPressureWarningSta" 4 "LowPressureWarningSta" 5 "LowPressureWarningSta" 6 "LowPressureWarningSta" 7 "LowPressureWarningSta" 8 "LowPressureWarningSta" 9 "LowPressureWarningSta" 10 "LowPressureWarningSta" 11 "LowPressureWarningSta" 12 "LowPressureWarningSta" 13 "LowPressureWarningSta" 14 "LowPressureWarningSta" 15 "LowPressureWarningSta" ;
VAL_ 2348810242 TPMS_LastTpsDataReq 0 "Off" 1 "On" 2 "RESERVED" 3 "Error Indicator" ;
VAL_ 2348810242 TPMS_SnsrIdFrVal 0 "0x0x0~0xFFFFFFFE:IDValue" 2147483647 "0x0x0~0xFFFFFFFE:IDValue" 2147483647 "Invalid" ;
VAL_ 2348810242 TPMS_SnsrIdRlVal 0 "0x0x0~0xFFFFFFFE:IDValue" 2147483647 "0x0x0~0xFFFFFFFE:IDValue" 2147483647 "Invalid" ;
VAL_ 2281701616 L_UWB_RL_FD_Crc10Val 0 "0x0x0~0xFFFF:CRCValue" 65535 "0x0x0~0xFFFF:CRCValue" ;
VAL_ 2281701616 L_UWB_RL_FD_AlvCnt10Val 0 "0x0x0~0xFF:AlvCntValue" 255 "0x0x0~0xFF:AlvCntValue" ;
VAL_ 2281701616 UWB_RL_Status1 0 "Default" 1 "No_Ranging" 2 "URSK_Stored" 3 "UWB_Session_Setup" 4 "Ranging_Start(Not_In_Sync)" 5 "Ranging_Start(In_Sync)" 6 "Ranging_Stop(Max_Signal_Missed)" 7 "Fob_Ranging" 8 "RESERVED" 9 "RESERVED" 10 "RESERVED" 11 "RESERVED" 12 "RESERVED" 13 "RESERVED" 14 "RESERVED" 15 "Invalid" ;
VAL_ 2281701616 UWB_RL_Status2 0 "Default" 1 "No_Ranging" 2 "URSK_Stored" 3 "UWB_Session_Setup" 4 "Ranging_Start(Not_In_Sync)" 5 "Ranging_Start(In_Sync)" 6 "Ranging_Stop(Max_Signal_Missed)" 7 "Fob_Ranging" 8 "RESERVED" 9 "RESERVED" 10 "RESERVED" 11 "RESERVED" 12 "RESERVED" 13 "RESERVED" 14 "RESERVED" 15 "Invalid" ;
VAL_ 2281701616 UWB_RL_Status3 0 "Default" 1 "No_Ranging" 2 "URSK_Stored" 3 "UWB_Session_Setup" 4 "Ranging_Start(Not_In_Sync)" 5 "Ranging_Start(In_Sync)" 6 "Ranging_Stop(Max_Signal_Missed)" 7 "Fob_Ranging" 8 "RESERVED" 9 "RESERVED" 10 "RESERVED" 11 "RESERVED" 12 "RESERVED" 13 "RESERVED" 14 "RESERVED" 15 "Invalid" ;
VAL_ 2281701616 UWB_RL_Status4 0 "Default" 1 "No_Ranging" 2 "URSK_Stored" 3 "UWB_Session_Setup" 4 "Ranging_Start(Not_In_Sync)" 5 "Ranging_Start(In_Sync)" 6 "Ranging_Stop(Max_Signal_Missed)" 7 "Fob_Ranging" 8 "RESERVED" 9 "RESERVED" 10 "RESERVED" 11 "RESERVED" 12 "RESERVED" 13 "RESERVED" 14 "RESERVED" 15 "Invalid" ;
VAL_ 2281701616 UWB_RL_Status5 0 "Default" 1 "No_Ranging" 2 "URSK_Stored" 3 "UWB_Session_Setup" 4 "Ranging_Start(Not_In_Sync)" 5 "Ranging_Start(In_Sync)" 6 "Ranging_Stop(Max_Signal_Missed)" 7 "Fob_Ranging" 8 "RESERVED" 9 "RESERVED" 10 "RESERVED" 11 "RESERVED" 12 "RESERVED" 13 "RESERVED" 14 "RESERVED" 15 "Invalid" ;
VAL_ 2281701616 UWB_RL_Status6 0 "Default" 1 "No_Ranging" 2 "URSK_Stored" 3 "UWB_Session_Setup" 4 "Ranging_Start(Not_In_Sync)" 5 "Ranging_Start(In_Sync)" 6 "Ranging_Stop(Max_Signal_Missed)" 7 "Fob_Ranging" 8 "RESERVED" 9 "RESERVED" 10 "RESERVED" 11 "RESERVED" 12 "RESERVED" 13 "RESERVED" 14 "RESERVED" 15 "Invalid" ;
VAL_ 2281701616 UWB_RL_Status7 0 "Default" 1 "No_Ranging" 2 "URSK_Stored" 3 "UWB_Session_Setup" 4 "Ranging_Start(Not_In_Sync)" 5 "Ranging_Start(In_Sync)" 6 "Ranging_Stop(Max_Signal_Missed)" 7 "Fob_Ranging" 8 "RESERVED" 9 "RESERVED" 10 "RESERVED" 11 "RESERVED" 12 "RESERVED" 13 "RESERVED" 14 "RESERVED" 15 "Invalid" ;
VAL_ 2281701616 UWB_RL_Status8 0 "Default" 1 "No_Ranging" 2 "URSK_Stored" 3 "UWB_Session_Setup" 4 "Ranging_Start(Not_In_Sync)" 5 "Ranging_Start(In_Sync)" 6 "Ranging_Stop(Max_Signal_Missed)" 7 "Fob_Ranging" 8 "RESERVED" 9 "RESERVED" 10 "RESERVED" 11 "RESERVED" 12 "RESERVED" 13 "RESERVED" 14 "RESERVED" 15 "Invalid" ;
VAL_ 2281701616 UWB_RL_Status9 0 "Default" 1 "No_Ranging" 2 "URSK_Stored" 3 "UWB_Session_Setup" 4 "Ranging_Start(Not_In_Sync)" 5 "Ranging_Start(In_Sync)" 6 "Ranging_Stop(Max_Signal_Missed)" 7 "Fob_Ranging" 8 "RESERVED" 9 "RESERVED" 10 "RESERVED" 11 "RESERVED" 12 "RESERVED" 13 "RESERVED" 14 "RESERVED" 15 "Invalid" ;
VAL_ 2281701616 UWB_RL_Status10 0 "Default" 1 "No_Ranging" 2 "URSK_Stored" 3 "UWB_Session_Setup" 4 "Ranging_Start(Not_In_Sync)" 5 "Ranging_Start(In_Sync)" 6 "Ranging_Stop(Max_Signal_Missed)" 7 "Fob_Ranging" 8 "RESERVED" 9 "RESERVED" 10 "RESERVED" 11 "RESERVED" 12 "RESERVED" 13 "RESERVED" 14 "RESERVED" 15 "Invalid" ;
VAL_ 2281701616 UWB_RL_Status11 0 "Default" 1 "No_Ranging" 2 "URSK_Stored" 3 "UWB_Session_Setup" 4 "Ranging_Start(Not_In_Sync)" 5 "Ranging_Start(In_Sync)" 6 "Ranging_Stop(Max_Signal_Missed)" 7 "Fob_Ranging" 8 "RESERVED" 9 "RESERVED" 10 "RESERVED" 11 "RESERVED" 12 "RESERVED" 13 "RESERVED" 14 "RESERVED" 15 "Invalid" ;
VAL_ 2281701616 UWB_RL_Status12 0 "Default" 1 "No_Ranging" 2 "URSK_Stored" 3 "UWB_Session_Setup" 4 "Ranging_Start(Not_In_Sync)" 5 "Ranging_Start(In_Sync)" 6 "Ranging_Stop(Max_Signal_Missed)" 7 "Fob_Ranging" 8 "RESERVED" 9 "RESERVED" 10 "RESERVED" 11 "RESERVED" 12 "RESERVED" 13 "RESERVED" 14 "RESERVED" 15 "Invalid" ;
VAL_ 2281701616 UWB_RL_Status13 0 "Default" 1 "No_Ranging" 2 "URSK_Stored" 3 "UWB_Session_Setup" 4 "Ranging_Start(Not_In_Sync)" 5 "Ranging_Start(In_Sync)" 6 "Ranging_Stop(Max_Signal_Missed)" 7 "Fob_Ranging" 8 "RESERVED" 9 "RESERVED" 10 "RESERVED" 11 "RESERVED" 12 "RESERVED" 13 "RESERVED" 14 "RESERVED" 15 "Invalid" ;
VAL_ 2281701616 UWB_RL_Status14 0 "Default" 1 "No_Ranging" 2 "URSK_Stored" 3 "UWB_Session_Setup" 4 "Ranging_Start(Not_In_Sync)" 5 "Ranging_Start(In_Sync)" 6 "Ranging_Stop(Max_Signal_Missed)" 7 "Fob_Ranging" 8 "RESERVED" 9 "RESERVED" 10 "RESERVED" 11 "RESERVED" 12 "RESERVED" 13 "RESERVED" 14 "RESERVED" 15 "Invalid" ;
VAL_ 2281701616 UWB_RL_Status15 0 "Default" 1 "No_Ranging" 2 "URSK_Stored" 3 "UWB_Session_Setup" 4 "Ranging_Start(Not_In_Sync)" 5 "Ranging_Start(In_Sync)" 6 "Ranging_Stop(Max_Signal_Missed)" 7 "Fob_Ranging" 8 "RESERVED" 9 "RESERVED" 10 "RESERVED" 11 "RESERVED" 12 "RESERVED" 13 "RESERVED" 14 "RESERVED" 15 "Invalid" ;
VAL_ 2281701616 UWB_RL_Status16 0 "Default" 1 "No_Ranging" 2 "URSK_Stored" 3 "UWB_Session_Setup" 4 "Ranging_Start(Not_In_Sync)" 5 "Ranging_Start(In_Sync)" 6 "Ranging_Stop(Max_Signal_Missed)" 7 "Fob_Ranging" 8 "RESERVED" 9 "RESERVED" 10 "RESERVED" 11 "RESERVED" 12 "RESERVED" 13 "RESERVED" 14 "RESERVED" 15 "Invalid" ;
VAL_ 979 BDC_FD_Crc4Val 0 "0x0x0~0xFFFF:CRCValue" 65535 "0x0x0~0xFFFF:CRCValue" ;
VAL_ 979 BDC_FD_AlvCnt4Val 0 "0x0x0~0xFF:AlvCntValue" 255 "0x0x0~0xFF:AlvCntValue" ;
VAL_ 979 BAlarm_BglrAlrm_CurrentSta 0 "Off" 1 "DisArm" 2 "Arm" 3 "PreArm" 4 "ArmWait" 5 "ArmHold" 6 "ReArm" 7 "AutoLockTimer (AutoLockTimer1)" 8 "RESERVED" 9 "Alarm" 10 "Default" 11 "TrunkTgTimer (AutoLockTimer3)" 12 "RESERVED" 13 "RESERVED" 14 "Not Used" 15 "Error Indicator" ;
VAL_ 979 BAlarm_BglrAlrm_Sta 0 "DIS-, PRE-, AUTOLOCKTIMER (AutoLockTimer1), TrunkTgTimer (AutoLockTimer3)" 1 "ARM, -WAIT, RE-, ALARM, -HD(Trunk)" 2 "Not Used" 3 "Error Indicator" ;
VAL_ 979 BAlarm_PncAlrmSta_Copy_0 0 "Off" 1 "On (Panic Alarm ON)" 2 "Not Used" 3 "Error Indicator" ;
VAL_ 979 SBR_StBltStpWrngBzrSta_Copy_0 0 "Warning Off" 1 "Buzzer Hold" 2 "1st Warning" 3 "2nd Warning" 4 "3rd Warning" 5 "Reserved" 6 "Pre Warning" 7 "Error Indicator" ;
VAL_ 979 SBR_StBltWrngBzrSta_Copy_0 0 "Warning Off" 1 "Buzzer Hold" 2 "Buzzer On" 3 "Reserved" 4 "Reserved" 5 "Reseved" 6 "Not Used" 7 "Error Indicator" ;
VAL_ 979 BAlarm_BrglrHrnRlySta_Copy_0 0 "Off" 1 "On" 2 "Not Used" 3 "Error Indicator" ;
VAL_ 979 SBR_DrvStBltIndSta_Copy_0 0 "Off" 1 "On" 2 "Not Used" 3 "Error Indicator" ;
VAL_ 979 SBR_RrLftStBltWrngIndSta_Copy_0 0 "Off" 1 "On" 2 "Belted" 3 "Error Indicator" ;
VAL_ 979 SBR_RrRtStBltWrngIndSta_Copy_0 0 "Off" 1 "On" 2 "Belted" 3 "Error Indicator" ;
VAL_ 979 SBR_RrCtrStBltIndSta_Copy_0 0 "Off" 1 "On" 2 "Belted" 3 "Error Indicator" ;
VAL_ 979 SBR_3rdLftStBltWrngIndSta_Copy_0 0 "Off" 1 "On" 2 "Belted" 3 "Error Indicator" ;
VAL_ 979 SBR_3rdRtStBltWrngIndSta_Copy_0 0 "Off" 1 "On" 2 "Belted" 3 "Error Indicator" ;
VAL_ 979 SBR_3rdCtrStBltWrngIndSta_Copy_0 0 "Off" 1 "On" 2 "Belted" 3 "Error Indicator" ;
VAL_ 979 Warn_BzrWrngSta_Copy_0 0 "Off" 1 "SeatBelt Warning" 2 "Key Operated Warning" 3 "Parking Brake Warning" 4 "Sun Roof Open Warning" 5 "Key Learning Sound(NoSMKOption" 6 "ICE Warning" 7 "Rear Fog Warning" 8 "Reserved" 9 "Reserved" 10 "Reserved" 11 "Reserved" 12 "Reserved" 13 "Reserved" 14 "Not Used" 15 "Error Indicator" ;
VAL_ 979 Warn_BCMWrngSta_Copy_0 0 "Off" 1 "Power off request warning" 2 "Shift P request Warning" 3 "Shift P Warning 2 (Pwr Off, Shift Enable)" 4 "Shift P Warning 2 (Pwr Off, Shift Disable)" 5 "Shift P Warning 2 (Pwr On, Shift Enable)" 6 "Shift P Warning 2 (Pwr On, Shift Disable)" 7 "RESERVED" 8 "RESERVED" 9 "RESERVED" 10 "RESERVED" 11 "RESERVED" 12 "RESERVED" 13 "RESERVED" 14 "Not Used" 15 "Error Indicator" ;
VAL_ 979 ROA_RrBlwAutoOffReq_Copy_0 0 "default" 1 "Request of Rear Blow Off (auto Cut)" 2 "Not Used" 3 "Error Indciator" ;
VAL_ 979 ROA_RegionOpt_Copy_0 0 "Non Euro NCAP CPD" 1 "Euro NCAP CPD" 2 "Reserved" 3 "Error Indicator" ;
VAL_ 979 Warn_RrStRmndOpt_Copy_0 0 "Not apply RrSeatRemind" 1 "Apply RrSeatRemind" 2 "Apply Radar ROA sensor" 3 "Error Indicator" ;
VAL_ 979 Warn_RrStRmndAlrmOnReq_Copy_0 0 "Off" 1 "On(Alarm)" 2 "Not Used" 3 "Error Indicator" ;
VAL_ 979 Warn_RrStRmndSysSta_Copy_0 0 "Default" 1 "System ON" 2 "System OFF" 3 "Error Indicator" ;
VAL_ 979 Warn_RrStRmndAlrmInfo_Copy_0 0 "Off" 1 "Rear Seat Reminder" 2 "Rear Seat Reminder 1st Only" 3 "Delayed ROA" 4 "Pre-warning" 5 "Pre-warning 1st Only" 6 "Pre-warning Ncap" 7 "Error Indicator" ;
VAL_ 979 Warn_RoaErr_Copy_0 0 "Off" 1 "SensorError( Malfunction)" 2 "Reserved" 3 "Reserved" 4 "Reserved" 5 "Reseved" 6 "Not Used" 7 "Error Indicator" ;
VAL_ 979 Warn_RrStRmndDelay_Copy_0 0 "Off" 1 "Delayed ROA" 2 "Not Used" 3 "Error Indicator" ;
VAL_ 979 Warn_RrStRmndSysAct_Copy_0 0 "Default" 1 "Deactivation" 2 "Off" 3 "Error Indicator" ;
VAL_ 979 WAL_FobSearching_Copy_0 0 "Not Fob Exist" 1 "Fob Exist" 2 "Reserved" 3 "Error Indicator" ;
VAL_ 979 Warn_RrStRmndSysOffIND_Copy_0 0 "Indicator Off" 1 "Indicator On" 2 "Not Used" 3 "Error Indicator" ;
VAL_ 979 Warn_VehNotPWrngSta_Copy_0 0 "Off" 1 "Not P Warning (Pwr Off, Shift Enable)" 2 "Not P Warning (Pwr Off, Shift Disable)" 3 "Not P Warning (Pwr On, Shift Enable)" 4 "Not P Warning (Pwr On, Shift Disable)" 5 "RESERVED" 6 "RESERVED" 7 "Error Indicator" ;
VAL_ 979 Warn_RrStRmndAlrmInfo_1_Copy_0 0 "Default" 1 "OFF" 2 "Pre-warning" 3 "Pre-warning 1st Only" 4 "Pre-warning Ncap" 5 "RESERVED" 6 "RESERVED" 7 "Error Indicator" ;
VAL_ 2533736961 L_UWB_TRNK_FD_Crc6Val 0 "0x0x0~0xFFFF:CRCValue" 65535 "0x0x0~0xFFFF:CRCValue" ;
VAL_ 2533736961 L_UWB_TRNK_FD_AlvCnt6Val 0 "0x0x0~0xFF:AlvCntValue" 255 "0x0x0~0xFF:AlvCntValue" ;
VAL_ 977 BDC_FD_Crc2Val 0 "0x0x0~0xFFFF:CRCValue" 65535 "0x0x0~0xFFFF:CRCValue" ;
VAL_ 977 BDC_FD_AlvCnt2Val 0 "0x0x0~0xFF:AlvCntValue" 255 "0x0x0~0xFF:AlvCntValue" ;
VAL_ 977 BCM_KeyInSta_Copy_0 0 "Off (Key removed)" 1 "On (Key inserted)" 2 "Not Used" 3 "Error Indicator" ;
VAL_ 977 BCM_AccInSta_Copy_0 0 "Acc Off" 1 "Acc On" 2 "Not Used" 3 "Error Indicator" ;
VAL_ 977 BCM_Ign1InSta_Copy_0 0 "IGN1 Off" 1 "IGN1 On" 2 "Not Used" 3 "Error Indicator" ;
VAL_ 977 BCM_Ign2InSta_Copy_0 0 "IGN2 Off" 1 "IGN2 On" 2 "Not Used" 3 "Error Indicator" ;
VAL_ 977 IBU_HDPSpprtSWVer_Copy_0 0 "Not Support (Init)" 1 "SW Version" 2 "SW Version" 3 "SW Version" 4 "SW Version" 5 "SW Version" 6 "SW Version" 7 "SW Version" 8 "SW Version" 9 "SW Version" 10 "SW Version" 11 "SW Version" 12 "SW Version" 13 "SW Version" 14 "SW Version" 15 "SW Version" 16 "SW Version" 17 "SW Version" 18 "SW Version" 19 "SW Version" 20 "SW Version" 21 "SW Version" 22 "SW Version" 23 "SW Version" 24 "SW Version" 25 "SW Version" 26 "SW Version" 27 "SW Version" 28 "SW Version" 29 "SW Version" 30 "SW Version" 31 "SW Version" 32 "SW Version" 33 "SW Version" 34 "SW Version" 35 "SW Version" 36 "SW Version" 37 "SW Version" 38 "SW Version" 39 "SW Version" 40 "SW Version" 41 "SW Version" 42 "SW Version" 43 "SW Version" 44 "SW Version" 45 "SW Version" 46 "SW Version" 47 "SW Version" 48 "SW Version" 49 "SW Version" 50 "SW Version" 51 "SW Version" 52 "SW Version" 53 "SW Version" 54 "SW Version" 55 "SW Version" 56 "SW Version" 57 "SW Version" 58 "SW Version" 59 "SW Version" 60 "SW Version" 61 "SW Version" 62 "SW Version" 63 "Error Indicator" ;
VAL_ 977 IBU_HDPSpprtRdy_Copy_0 0 "Normal" 1 "ADAS Message Not Recognized" 2 "RESERVED" 3 "RESERVED" ;
VAL_ 977 BCM_GearPosPSta_Copy_0 0 "Off" 1 "P" 2 "Not Used" 3 "Error Indicator" ;
VAL_ 977 BCM_SmkOptTyp_Copy_0 0 "Non SMK Option" 1 "SMK Option" 2 "Not Used" 3 "Error Indicator" ;
VAL_ 977 BDC_ResetOpSta_Copy_0 0 "Normal" 1 "Reset Complete" 2 "Reset Fail" 3 "RESERVED" ;
VAL_ 977 IBU_SWVerMajor1_Copy_0 0 "0x0x0~0x7F:ASCII Code Value (HEX)" 127 "0x0x0~0x7F:ASCII Code Value (HEX)" ;
VAL_ 977 IBU_SWVerMinor1_Copy_0 0 "0x0x0~0x7F:ASCII Code Value (HEX)" 127 "0x0x0~0x7F:ASCII Code Value (HEX)" ;
VAL_ 977 IBU_SWVerMinor2_Copy_0 0 "0x0x0~0x7F:ASCII Code Value (HEX)" 127 "0x0x0~0x7F:ASCII Code Value (HEX)" ;
VAL_ 977 BDC_PlatformVerType_Copy_0 0 "Default(Not Defined)" 1 "A" 2 "B" 3 "C" 4 "Not Used" 5 "Not Used" 6 "Not Used" 7 "Not Used" 8 "Not Used" 9 "Not Used" 10 "Not Used" 11 "Not Used" 12 "Not Used" 13 "Not Used" 14 "Not Used" 15 "Invalid" ;
VAL_ 977 BDC_PlatformVerDate_Copy_0 0 "Default(Not Defined)" 1 "2301" 2 "2302" 3 "2303" 4 "2304" 5 "2305" 6 "0x6~0xFE:YYMM(2306~)" 254 "0x6~0xFE:YYMM(2306~)" 255 "Invalid" ;
VAL_ 2529538561 L_UWB_RL_FD_Crc6Val 0 "0x0x0~0xFFFF:CRCValue" 65535 "0x0x0~0xFFFF:CRCValue" ;
VAL_ 2529538561 L_UWB_RL_FD_AlvCnt6Val 0 "0x0x0~0xFF:AlvCntValue" 255 "0x0x0~0xFF:AlvCntValue" ;
